// *************************************************************************** *
// *                                                                           *
// *                      Mentor Graphics Corporation                          *
// *                          All rights reserved                              *
// *                                                                           *
// *************************************************************************** *
// *                                                                           *
// * Description:         Partial CANDB File (for BMS Node)                    *
// * Generated at:        2025-09-16 19:54                                     *
// * Node                 BMS                                                  *
// *                                                                           *
// *************************************************************************** *
// *                                                                           *
// *             THIS CONFIGURATION MIGHT CONTAIN SOME ERRORS                  *
// *              IF THE INPUT MODEL WAS NOT PROPERLY FORMED!                  *
// *                    Do Not Use this File directly!                         *
// *                                                                           *
// *************************************************************************** *
VERSION "BMS"

NS_ :

BS_ :

BU_ : BMS

BO_ 305 BMS_PTCANFD_0x131 : 16 BMS
 SG_ BMSChrgrCurCurCp : 63|12@0+ (0.25,0.0) [0.0|1023.75] "A" Vector__XXX
 SG_ HvBattAvgCur : 47|16@0+ (0.1,-3276.7) [-3276.7|3276.8] "A" Vector__XXX
 SG_ HvBattChrgnModSts : 23|3@0+ (1,0) [0|7] "" Vector__XXX
 SG_ HvBattDCPortU : 31|14@0+ (0.1,0.0) [0.0|1638.3000000000002] "" Vector__XXX
 SG_ HvBattHVIL1Sts : 13|2@0+ (1,0) [0|3] "" Vector__XXX
 SG_ HvBattHVIL2Sts : 15|2@0+ (1,0) [0|3] "" Vector__XXX
 SG_ HvBattHVILStsSigGrpChks : 7|8@0+ (1,0) [0|255] "" Vector__XXX
 SG_ HvBattHVILStsSigGrpCntr : 11|4@0+ (1,0) [0|15] "" Vector__XXX
 SG_ HvBattServModSts : 33|2@0+ (1,0) [0|3] "" Vector__XXX

BO_ 449 BMS_PTCANFD_0x1C1 : 32 BMS
 SG_ BMSAuthenticationSts : 57|2@0+ (1,0) [0|3] "" Vector__XXX
 SG_ BMSBCPErrSts : 87|3@0+ (1,0) [0|7] "" Vector__XXX
 SG_ BMSBHMErrSts : 39|2@0+ (1.0,0.0) [0.0|1.0] "" Vector__XXX
 SG_ BMSChrgnAwakeSts : 84|3@0+ (1,0) [0|7] "" Vector__XXX
 SG_ BMSChrgnPauseSts : 81|2@0+ (1,0) [0|3] "" Vector__XXX
 SG_ BMSChrgnRepeatReq : 111|2@0+ (1,0) [0|3] "" Vector__XXX
 SG_ DCChrgnCntctSts : 13|2@0+ (1,0) [0|3] "" Vector__XXX
 SG_ DCChrgnHvBattSoCSigGrpChks : 7|8@0+ (1,0) [0|255] "" Vector__XXX
 SG_ DCChrgnHvBattSoCSigGrpCntr : 11|4@0+ (1,0) [0|15] "" Vector__XXX
 SG_ DCChrgnNegCntctSts : 25|2@0+ (1,0) [0|3] "" Vector__XXX
 SG_ DCChrgnPosCntctSts : 15|2@0+ (1,0) [0|3] "" Vector__XXX
 SG_ DCPileType : 35|3@0+ (1.0,0.0) [0.0|5.0] "" Vector__XXX
 SG_ HvBattAvgCurBackUp : 143|16@0+ (0.1,-3276.7) [-3276.7|3276.8] "A" Vector__XXX
 SG_ HvBattCoolgLvlReq : 63|3@0+ (1,0) [0|7] "" Vector__XXX
 SG_ HvBattFlgChrgnSoCLimFinish : 51|1@0+ (1,0) [0|1] "" Vector__XXX
 SG_ HvBattFlgDchrgnSoCLimFinish : 50|1@0+ (1,0) [0|1] "" Vector__XXX
 SG_ HvBattFlgFullChrgnFinish : 52|1@0+ (1,0) [0|1] "" Vector__XXX
 SG_ HvBattHeatCurLim : 71|14@0+ (0.1,0.0) [0.0|1638.3000000000002] "A" Vector__XXX
 SG_ HvBattHeatgLvlReq : 60|3@0+ (1,0) [0|7] "" Vector__XXX
 SG_ HvBattLowTSocRedn : 109|14@0+ (0.01,0.0) [0.0|100.0] "pct" Vector__XXX
 SG_ HvBattNormTDispSoc : 127|14@0+ (0.01,0.0) [0.0|100.0] "pct" Vector__XXX
 SG_ HvBattSoCAct : 23|11@0+ (0.05,0.0) [0.0|100.0] "%" Vector__XXX
 SG_ HvBattSoCDisp : 47|11@0+ (0.05,0.0) [0.0|100.0] "%" Vector__XXX
 SG_ HvBattSoCDispForHiResl : 95|16@0+ (0.01,0.0) [0.0|100.0] "%" Vector__XXX
 SG_ HvBattSoCDispFV : 215|16@0+ (1.0,0.0) [0.0|65535.0] "" Vector__XXX
 SG_ HvBattSoCDispMAC : 231|32@0+ (1.0,0.0) [0.0|4294967295.0] "" Vector__XXX
 SG_ HVSampChipOverCurrFlg : 49|1@0+ (1.0,0.0) [0.0|1.0] "" Vector__XXX
 SG_ PrechargnPosCntctSts : 37|2@0+ (1,0) [0|3] "" Vector__XXX

BO_ 534 BMS_PTCANFD_0x216 : 8 BMS
 SG_ BMSSyncFVReq : 7|32@0+ (1.0,0.0) [0.0|4294967295.0] "" Vector__XXX

BO_ 626 BMS_PTCANFD_0x272 : 24 BMS
 SG_ BMSFaultInfoFlag : 119|1@0+ (1.0,0.0) [0.0|1.0] "" Vector__XXX
 SG_ FlybackFaultInf : 151|12@0+ (1.0,0.0) [0.0|4095.0] "" Vector__XXX
 SG_ FlybackOutput4Volt : 167|9@0+ (0.1,0.0) [0.0|51.1] "V" Vector__XXX
 SG_ FlybackSupply2OcCtr : 183|8@0+ (1.0,0.0) [0.0|255.0] "" Vector__XXX
 SG_ HvBattActvThermRemd : 31|2@0+ (1,0) [0|3] "" Vector__XXX
 SG_ HvBattDchrgnEgyDisp : 103|11@0+ (0.1,0.0) [0.0|200.0] "kWh" Vector__XXX
 SG_ HvBattDchrgnEgyMax : 87|11@0+ (0.1,0.0) [0.0|200.0] "kWh" Vector__XXX
 SG_ HvBattFlgLowSoc : 118|2@0+ (1,0) [0|3] "" Vector__XXX
 SG_ HvBattFlgPfmn : 27|1@0+ (1,0) [0|1] "" Vector__XXX
 SG_ HvBattFlgSfty : 55|3@0+ (1,0) [0|7] "" Vector__XXX
 SG_ HvBattFlgSftySigGrpChks : 39|8@0+ (1,0) [0|255] "" Vector__XXX
 SG_ HvBattFlgSftySigGrpCntr : 43|4@0+ (1,0) [0|15] "" Vector__XXX
 SG_ HvBattFlgThermRunAway : 45|2@0+ (1,0) [0|3] "" Vector__XXX
 SG_ HvBattHlthMngtFcnSts : 25|2@0+ (1,0) [0|3] "" Vector__XXX
 SG_ HvBattHWFailReq : 76|1@0+ (1,0) [0|1] "" Vector__XXX
 SG_ HvBattLeakFltIndcn : 116|1@0+ (1.0,0.0) [0.0|1.0] "" Vector__XXX
 SG_ HvBattLowSocDrvInhb : 115|1@0+ (1,0) [0|1] "" Vector__XXX
 SG_ HvBattRlyHldSts : 143|2@0+ (1,0) [0|3] "" Vector__XXX
 SG_ HvBattRlyHldStsChks : 127|8@0+ (1.0,0.0) [0.0|255.0] "" Vector__XXX
 SG_ HvBattRlyHldStsCntr : 131|4@0+ (1.0,0.0) [0.0|15.0] "" Vector__XXX
 SG_ HvBattRmngChrgnTi : 7|12@0+ (1.0,0.0) [0.0|4095.0] "min" Vector__XXX
 SG_ HvBattRmngDchrgnTi : 11|12@0+ (1.0,0.0) [0.0|4095.0] "min" Vector__XXX
 SG_ HvBattSoCLock : 71|11@0+ (0.05,0.0) [0.0|100.0] "%" Vector__XXX
 SG_ HvbattSrvReq : 114|2@0+ (1,0) [0|3] "" Vector__XXX
 SG_ HvBattSupChrgnResp : 153|2@0+ (1,0) [0|3] "" Vector__XXX
 SG_ HvBattTempLowFault : 26|1@0+ (1,0) [0|1] "" Vector__XXX

BO_ 627 BMS_PTCANFD_0x273 : 16 BMS
 SG_ HvBattCellUDifFltRSMS : 21|2@0+ (1,0) [0|3] "" Vector__XXX
 SG_ HvBattCellUOverFltRSMS : 31|2@0+ (1,0) [0|3] "" Vector__XXX
 SG_ HvBattCellUUnderFltRSMS : 29|2@0+ (1,0) [0|3] "" Vector__XXX
 SG_ HvBattChrgnEmcyOffReq : 25|1@0+ (1.0,0.0) [0.0|1.0] "" Vector__XXX
 SG_ HvBattChrgnrComFltRSMS : 51|2@0+ (1,0) [0|3] "" Vector__XXX
 SG_ HvBattColdWarn : 35|1@0+ (1,0) [0|1] "" Vector__XXX
 SG_ HvBattFRSReact : 63|8@0+ (1.0,0.0) [0.0|255.0] "" Vector__XXX
 SG_ HvBattFusaPulseCurrMon : 24|1@0+ (1.0,0.0) [0.0|1.0] "" Vector__XXX
 SG_ HvBattMaxUCellIDRSMS : 7|8@0+ (1.0,0.0) [1.0|255.0] "" Vector__XXX
 SG_ HvBattMILReq : 32|1@0+ (1,0) [0|1] "" Vector__XXX
 SG_ HvBattMinUCellIDRSMS : 15|8@0+ (1.0,0.0) [1.0|255.0] "" Vector__XXX
 SG_ HvBattOperationReq : 39|4@0+ (1,0) [0|15] "" Vector__XXX
 SG_ HvBattOverChrgnFltRSMS : 27|2@0+ (1,0) [0|3] "" Vector__XXX
 SG_ HvBattOverCurFltRSMS : 49|2@0+ (1,0) [0|3] "" Vector__XXX
 SG_ HvBattPackUOverFltRSMS : 34|2@0+ (1,0) [0|3] "" Vector__XXX
 SG_ HvBattPackUUnderFltRSMS : 47|2@0+ (1,0) [0|3] "" Vector__XXX
 SG_ HvBattPwrDoMoSceRSMS : 67|2@0+ (1,0) [0|3] "" Vector__XXX
 SG_ HvBattRutPheatgChrgnSts1 : 79|8@0+ (1.0,0.0) [0.0|255.0] "" Vector__XXX
 SG_ HvBattRutPheatgChrgnSts2 : 87|8@0+ (1,0) [0|255] "" Vector__XXX
 SG_ HvBattRutPheatgChrgnSts3 : 95|16@0+ (1.0,0.0) [0.0|65535.0] "" Vector__XXX
 SG_ HvBattRutPheatgChrgnSts4 : 111|16@0+ (1.0,0.0) [0.0|65535.0] "" Vector__XXX
 SG_ HvBattSocHiFltRSMS : 45|2@0+ (1,0) [0|3] "" Vector__XXX
 SG_ HvBattSocHopFltRSMS : 43|2@0+ (1,0) [0|3] "" Vector__XXX
 SG_ HvBattSocLoFltRSMS : 41|2@0+ (1,0) [0|3] "" Vector__XXX
 SG_ HvBattTDifFltRSMS : 55|2@0+ (1,0) [0|3] "" Vector__XXX
 SG_ HvBattTotFltQntyRSMS : 19|4@0+ (1.0,0.0) [0.0|15.0] "" Vector__XXX
 SG_ HvBattTOverFltRSMS : 53|2@0+ (1,0) [0|3] "" Vector__XXX
 SG_ MainNegCntctFlt : 65|2@0+ (1,0) [0|3] "" Vector__XXX
 SG_ MainPosCntctFlt : 23|2@0+ (1,0) [0|3] "" Vector__XXX

BO_ 629 BMS_PTCANFD_0x275 : 16 BMS
 SG_ DCChrgrCurCp : 27|12@0+ (0.25,0.0) [0.0|1023.75] "A" Vector__XXX
 SG_ DCChrgrUCp : 47|11@0+ (1.0,0.0) [0.0|2047.0] "V" Vector__XXX
 SG_ FlybackOutput1Volt : 48|9@0+ (0.1,0.0) [0.0|51.1] "V" Vector__XXX
 SG_ FlybackOutput2Volt : 71|9@0+ (0.1,0.0) [0.0|51.1] "V" Vector__XXX
 SG_ FlybackOutput3Volt : 72|9@0+ (0.1,0.0) [0.0|51.1] "V" Vector__XXX
 SG_ FlybackSupply1OcCtr : 95|8@0+ (1.0,0.0) [0.0|255.0] "" Vector__XXX
 SG_ HvBattCurMaxLimDCChrgn : 7|14@0+ (0.1,0.0) [0.0|1000.0] "A" Vector__XXX
 SG_ HvBattUMaxLimDCChrgn : 23|12@0+ (0.25,0.0) [0.0|1000.0] "V" Vector__XXX

BO_ 630 BMS_PTCANFD_0x276 : 64 BMS
 SG_ BuckOutpUReq : 135|13@0+ (0.1,0.0) [0.0|819.1] "V" Vector__XXX
 SG_ DCChrgnProtocolVers : 90|3@0+ (1,0) [0|7] "" Vector__XXX
 SG_ DCChrgrActCur : 103|12@0+ (0.25,0.0) [0.0|1023.75] "A" Vector__XXX
 SG_ DCChrgrActU : 119|11@0+ (1.0,0.0) [0.0|2047.0] "V" Vector__XXX
 SG_ DCChrgrTypInfo : 107|4@0+ (1,0) [0|15] "" Vector__XXX
 SG_ HvBatt2CCUSleepCmd : 183|8@0+ (1.0,0.0) [0.0|255.0] "" Vector__XXX
 SG_ HvBattBkdHeatgTi : 207|12@0+ (1.0,0.0) [0.0|4095.0] "min" Vector__XXX
 SG_ HvBattBkdPredChrgnTi : 211|12@0+ (1.0,0.0) [0.0|4095.0] "min" Vector__XXX
 SG_ HvBattChrgdEgyThisChrgnCyc : 151|17@0+ (0.001,0.0) [0.0|131.071] "kwh" Vector__XXX
 SG_ HvBattCurMaxLimACChrgn : 55|14@0+ (0.1,0.0) [0.0|1000.0] "A" Vector__XXX
 SG_ HvBattDCChrgnfltTyp : 255|3@0+ (1,0) [0|7] "" Vector__XXX
 SG_ HvBattDCChrgnSts : 123|4@0+ (1,0) [0|15] "" Vector__XXX
 SG_ HvBattDCChrgnTyp : 252|3@0+ (1,0) [0|7] "" Vector__XXX
 SG_ HvBattKeepWrmgTi : 231|12@0+ (1.0,0.0) [0.0|4095.0] "min" Vector__XXX
 SG_ HvBattOCCurMaxAuxFastRec : 191|16@0+ (1.0,-32767.0) [-32767.0|32768.0] "A" Vector__XXX
 SG_ HvBattOCCurMaxAuxRec : 327|16@0+ (1.0,-32767.0) [-32767.0|32768.0] "A" Vector__XXX
 SG_ HvBattOCCurMaxMainFastRec : 343|16@0+ (1.0,-32767.0) [-32767.0|32768.0] "A" Vector__XXX
 SG_ HvBattOCCurMaxMainRec : 359|16@0+ (1.0,-32767.0) [-32767.0|32768.0] "A" Vector__XXX
 SG_ HvBattPreHeatgTi : 235|12@0+ (1.0,0.0) [0.0|4095.0] "min" Vector__XXX
 SG_ HvBattSyncUCellMax : 311|16@0+ (0.0001,0.0) [0.0|6.5535000000000005] "V" Vector__XXX
 SG_ HvBattSyncUCellMin : 295|16@0+ (0.0001,0.0) [0.0|6.5535000000000005] "V" Vector__XXX
 SG_ HvBattUCellAvg : 87|13@0+ (0.001,0.0) [0.0|8.19] "V" Vector__XXX
 SG_ HvBattUCellMax : 23|13@0+ (0.001,0.0) [0.0|8.191] "V" Vector__XXX
 SG_ HvBattUCellMin : 39|13@0+ (0.001,0.0) [0.0|8.191] "V" Vector__XXX
 SG_ HvBattUCellSigGrpChks : 7|8@0+ (1,0) [0|255] "" Vector__XXX
 SG_ HvBattUCellSigGrpCntr : 11|4@0+ (1,0) [0|15] "" Vector__XXX
 SG_ HvBattUCellSyncCur : 279|16@0+ (0.1,-3276.8) [-3276.8|3276.7] "A" Vector__XXX
 SG_ HvBattUCellSyncSigGrpChks : 263|8@0+ (1,0) [0|255] "" Vector__XXX
 SG_ HvBattUCellSyncSigGrpCntr : 267|4@0+ (1,0) [0|15] "" Vector__XXX
 SG_ HvBattUMaxLimACChrgn : 71|12@0+ (0.25,0.0) [0.0|1000.0] "V" Vector__XXX

BO_ 632 BMS_PTCANFD_0x278 : 32 BMS
 SG_ HvBattCorsCur : 7|16@0+ (0.1,-3276.7) [-3276.7|3276.8] "A" Vector__XXX
 SG_ HvBattFltNr1 : 191|10@0+ (1.0,0.0) [0.0|1023.0] "" Vector__XXX
 SG_ HvBattFltNr2 : 215|10@0+ (1.0,0.0) [0.0|1023.0] "" Vector__XXX
 SG_ HvBattFltNr3 : 217|10@0+ (1.0,0.0) [0.0|1023.0] "" Vector__XXX
 SG_ HvBattFltNr4 : 239|10@0+ (1.0,0.0) [0.0|1023.0] "" Vector__XXX
 SG_ HvBattFltNr5 : 241|10@0+ (1.0,0.0) [0.0|1023.0] "" Vector__XXX
 SG_ HvBattFltNrIdx : 193|10@0+ (1.0,0.0) [0.0|1023.0] "" Vector__XXX
 SG_ HvBattFltTotNr : 137|10@0+ (1.0,0.0) [0.0|1023.0] "" Vector__XXX
 SG_ HvBatThrRson : 159|32@0+ (1.0,0.0) [0.0|4294967295.0] "" Vector__XXX
 SG_ HvBattSopMdlLongTiChrgCurr : 39|11@0+ (1.0,0.0) [0.0|2047.0] "A" Vector__XXX
 SG_ HvBattSopMdlLongTiDchaCurr : 55|11@0+ (1.0,0.0) [0.0|2047.0] "A" Vector__XXX
 SG_ HvBattSopMdlShoTiChrgCurr : 71|11@0+ (1.0,0.0) [0.0|2047.0] "A" Vector__XXX
 SG_ HvBattSopMdlShoTiDchaCurr : 87|11@0+ (1.0,0.0) [0.0|2047.0] "A" Vector__XXX
 SG_ HvBattUkl30C : 135|9@0+ (0.1,0.0) [0.0|51.1] "V" Vector__XXX
 SG_ HvBattV2VSts : 142|3@0+ (1,0) [0|7] "" Vector__XXX

BO_ 633 BMS_PTCANFD_0x279 : 32 BMS
 SG_ HvBattCellURSMS1 : 7|13@0+ (0.001,0.0) [0.0|8.19] "V" Vector__XXX
 SG_ HvBattCellURSMS10 : 151|13@0+ (0.001,0.0) [0.0|8.19] "V" Vector__XXX
 SG_ HvBattCellURSMS11 : 167|13@0+ (0.001,0.0) [0.0|8.19] "V" Vector__XXX
 SG_ HvBattCellURSMS12 : 183|13@0+ (0.001,0.0) [0.0|8.19] "V" Vector__XXX
 SG_ HvBattCellURSMS13 : 199|13@0+ (0.001,0.0) [0.0|8.19] "V" Vector__XXX
 SG_ HvBattCellURSMS14 : 215|13@0+ (0.001,0.0) [0.0|8.19] "V" Vector__XXX
 SG_ HvBattCellURSMS15 : 231|13@0+ (0.001,0.0) [0.0|8.19] "V" Vector__XXX
 SG_ HvBattCellURSMS16 : 247|13@0+ (0.001,0.0) [0.0|8.191] "V" Vector__XXX
 SG_ HvBattCellURSMS2 : 23|13@0+ (0.001,0.0) [0.0|8.19] "V" Vector__XXX
 SG_ HvBattCellURSMS3 : 39|13@0+ (0.001,0.0) [0.0|8.19] "V" Vector__XXX
 SG_ HvBattCellURSMS4 : 55|13@0+ (0.001,0.0) [0.0|8.19] "V" Vector__XXX
 SG_ HvBattCellURSMS5 : 71|13@0+ (0.001,0.0) [0.0|8.19] "V" Vector__XXX
 SG_ HvBattCellURSMS6 : 87|13@0+ (0.001,0.0) [0.0|8.19] "V" Vector__XXX
 SG_ HvBattCellURSMS7 : 103|13@0+ (0.001,0.0) [0.0|8.19] "V" Vector__XXX
 SG_ HvBattCellURSMS8 : 119|13@0+ (0.001,0.0) [0.0|8.19] "V" Vector__XXX
 SG_ HvBattCellURSMS9 : 135|13@0+ (0.001,0.0) [0.0|8.19] "V" Vector__XXX

BO_ 634 BMS_PTCANFD_0x27A : 32 BMS
 SG_ HvBattCellURSMS17 : 7|13@0+ (0.001,0.0) [0.0|8.191] "V" Vector__XXX
 SG_ HvBattCellURSMS18 : 23|13@0+ (0.001,0.0) [0.0|8.191] "V" Vector__XXX
 SG_ HvBattCellURSMS19 : 39|13@0+ (0.001,0.0) [0.0|8.191] "V" Vector__XXX
 SG_ HvBattCellURSMS20 : 55|13@0+ (0.001,0.0) [0.0|8.191] "V" Vector__XXX
 SG_ HvBattCellURSMS21 : 71|13@0+ (0.001,0.0) [0.0|8.191] "V" Vector__XXX
 SG_ HvBattCellURSMS22 : 87|13@0+ (0.001,0.0) [0.0|8.191] "V" Vector__XXX
 SG_ HvBattCellURSMS23 : 103|13@0+ (0.001,0.0) [0.0|8.191] "V" Vector__XXX
 SG_ HvBattCellURSMS24 : 119|13@0+ (0.001,0.0) [0.0|8.191] "V" Vector__XXX
 SG_ HvBattCellURSMS25 : 135|13@0+ (0.001,0.0) [0.0|8.191] "V" Vector__XXX
 SG_ HvBattCellURSMS26 : 151|13@0+ (0.001,0.0) [0.0|8.191] "V" Vector__XXX
 SG_ HvBattCellURSMS27 : 167|13@0+ (0.001,0.0) [0.0|8.191] "V" Vector__XXX
 SG_ HvBattCellURSMS28 : 183|13@0+ (0.001,0.0) [0.0|8.191] "V" Vector__XXX
 SG_ HvBattCellURSMS29 : 199|13@0+ (0.001,0.0) [0.0|8.191] "V" Vector__XXX
 SG_ HvBattCellURSMS30 : 215|13@0+ (0.001,0.0) [0.0|8.191] "V" Vector__XXX
 SG_ HvBattCellURSMS31 : 231|13@0+ (0.001,0.0) [0.0|8.191] "V" Vector__XXX
 SG_ HvBattCellURSMS32 : 247|13@0+ (0.001,0.0) [0.0|8.191] "V" Vector__XXX

BO_ 635 BMS_PTCANFD_0x27B : 32 BMS
 SG_ HvBattCellURSMS33 : 7|13@0+ (0.001,0.0) [0.0|8.191] "V" Vector__XXX
 SG_ HvBattCellURSMS34 : 23|13@0+ (0.001,0.0) [0.0|8.191] "V" Vector__XXX
 SG_ HvBattCellURSMS35 : 39|13@0+ (0.001,0.0) [0.0|8.191] "V" Vector__XXX
 SG_ HvBattCellURSMS36 : 55|13@0+ (0.001,0.0) [0.0|8.191] "V" Vector__XXX
 SG_ HvBattCellURSMS37 : 71|13@0+ (0.001,0.0) [0.0|8.191] "V" Vector__XXX
 SG_ HvBattCellURSMS38 : 87|13@0+ (0.001,0.0) [0.0|8.191] "V" Vector__XXX
 SG_ HvBattCellURSMS39 : 103|13@0+ (0.001,0.0) [0.0|8.191] "V" Vector__XXX
 SG_ HvBattCellURSMS40 : 119|13@0+ (0.001,0.0) [0.0|8.191] "V" Vector__XXX
 SG_ HvBattCellURSMS41 : 135|13@0+ (0.001,0.0) [0.0|8.191] "V" Vector__XXX
 SG_ HvBattCellURSMS42 : 151|13@0+ (0.001,0.0) [0.0|8.191] "V" Vector__XXX
 SG_ HvBattCellURSMS43 : 167|13@0+ (0.001,0.0) [0.0|8.191] "V" Vector__XXX
 SG_ HvBattCellURSMS44 : 183|13@0+ (0.001,0.0) [0.0|8.191] "V" Vector__XXX
 SG_ HvBattCellURSMS45 : 199|13@0+ (0.001,0.0) [0.0|8.191] "V" Vector__XXX
 SG_ HvBattCellURSMS46 : 215|13@0+ (0.001,0.0) [0.0|8.191] "V" Vector__XXX
 SG_ HvBattCellURSMS47 : 231|13@0+ (0.001,0.0) [0.0|8.191] "V" Vector__XXX
 SG_ HvBattCellURSMS48 : 247|13@0+ (0.001,0.0) [0.0|8.191] "V" Vector__XXX

BO_ 636 BMS_PTCANFD_0x27C : 32 BMS
 SG_ HvBattCellURSMS49 : 7|13@0+ (0.001,0.0) [0.0|8.191] "V" Vector__XXX
 SG_ HvBattCellURSMS50 : 23|13@0+ (0.001,0.0) [0.0|8.191] "V" Vector__XXX
 SG_ HvBattCellURSMS51 : 39|13@0+ (0.001,0.0) [0.0|8.191] "V" Vector__XXX
 SG_ HvBattCellURSMS52 : 55|13@0+ (0.001,0.0) [0.0|8.191] "V" Vector__XXX
 SG_ HvBattCellURSMS53 : 71|13@0+ (0.001,0.0) [0.0|8.191] "V" Vector__XXX
 SG_ HvBattCellURSMS54 : 87|13@0+ (0.001,0.0) [0.0|8.191] "V" Vector__XXX
 SG_ HvBattCellURSMS55 : 103|13@0+ (0.001,0.0) [0.0|8.191] "V" Vector__XXX
 SG_ HvBattCellURSMS56 : 119|13@0+ (0.001,0.0) [0.0|8.191] "V" Vector__XXX
 SG_ HvBattCellURSMS57 : 135|13@0+ (0.001,0.0) [0.0|8.191] "V" Vector__XXX
 SG_ HvBattCellURSMS58 : 151|13@0+ (0.001,0.0) [0.0|8.191] "V" Vector__XXX
 SG_ HvBattCellURSMS59 : 167|13@0+ (0.001,0.0) [0.0|8.191] "V" Vector__XXX
 SG_ HvBattCellURSMS60 : 183|13@0+ (0.001,0.0) [0.0|8.191] "V" Vector__XXX
 SG_ HvBattCellURSMS61 : 199|13@0+ (0.001,0.0) [0.0|8.191] "V" Vector__XXX
 SG_ HvBattCellURSMS62 : 215|13@0+ (0.001,0.0) [0.0|8.191] "V" Vector__XXX
 SG_ HvBattCellURSMS63 : 231|13@0+ (0.001,0.0) [0.0|8.191] "V" Vector__XXX
 SG_ HvBattCellURSMS64 : 247|13@0+ (0.001,0.0) [0.0|8.191] "V" Vector__XXX

BO_ 637 BMS_PTCANFD_0x27D : 32 BMS
 SG_ HvBattCellURSMS65 : 7|13@0+ (0.001,0.0) [0.0|8.191] "V" Vector__XXX
 SG_ HvBattCellURSMS66 : 23|13@0+ (0.001,0.0) [0.0|8.191] "V" Vector__XXX
 SG_ HvBattCellURSMS67 : 39|13@0+ (0.001,0.0) [0.0|8.191] "V" Vector__XXX
 SG_ HvBattCellURSMS68 : 55|13@0+ (0.001,0.0) [0.0|8.191] "V" Vector__XXX
 SG_ HvBattCellURSMS69 : 71|13@0+ (0.001,0.0) [0.0|8.191] "V" Vector__XXX
 SG_ HvBattCellURSMS70 : 87|13@0+ (0.001,0.0) [0.0|8.191] "V" Vector__XXX
 SG_ HvBattCellURSMS71 : 103|13@0+ (0.001,0.0) [0.0|8.191] "V" Vector__XXX
 SG_ HvBattCellURSMS72 : 119|13@0+ (0.001,0.0) [0.0|8.191] "V" Vector__XXX
 SG_ HvBattCellURSMS73 : 135|13@0+ (0.001,0.0) [0.0|8.191] "V" Vector__XXX
 SG_ HvBattCellURSMS74 : 151|13@0+ (0.001,0.0) [0.0|8.191] "V" Vector__XXX
 SG_ HvBattCellURSMS75 : 167|13@0+ (0.001,0.0) [0.0|8.191] "V" Vector__XXX
 SG_ HvBattCellURSMS76 : 183|13@0+ (0.001,0.0) [0.0|8.191] "V" Vector__XXX
 SG_ HvBattCellURSMS77 : 199|13@0+ (0.001,0.0) [0.0|8.191] "V" Vector__XXX
 SG_ HvBattCellURSMS78 : 215|13@0+ (0.001,0.0) [0.0|8.191] "V" Vector__XXX
 SG_ HvBattCellURSMS79 : 231|13@0+ (0.001,0.0) [0.0|8.191] "V" Vector__XXX
 SG_ HvBattCellURSMS80 : 247|13@0+ (0.001,0.0) [0.0|8.191] "V" Vector__XXX

BO_ 638 BMS_PTCANFD_0x27E : 32 BMS
 SG_ HvBattCellURSMS81 : 7|13@0+ (0.001,0.0) [0.0|8.191] "V" Vector__XXX
 SG_ HvBattCellURSMS82 : 23|13@0+ (0.001,0.0) [0.0|8.191] "V" Vector__XXX
 SG_ HvBattCellURSMS83 : 39|13@0+ (0.001,0.0) [0.0|8.191] "V" Vector__XXX
 SG_ HvBattCellURSMS84 : 55|13@0+ (0.001,0.0) [0.0|8.191] "V" Vector__XXX
 SG_ HvBattCellURSMS85 : 71|13@0+ (0.001,0.0) [0.0|8.191] "V" Vector__XXX
 SG_ HvBattCellURSMS86 : 87|13@0+ (0.001,0.0) [0.0|8.191] "V" Vector__XXX
 SG_ HvBattCellURSMS87 : 103|13@0+ (0.001,0.0) [0.0|8.191] "V" Vector__XXX
 SG_ HvBattCellURSMS88 : 119|13@0+ (0.001,0.0) [0.0|8.191] "V" Vector__XXX
 SG_ HvBattCellURSMS89 : 135|13@0+ (0.001,0.0) [0.0|8.191] "V" Vector__XXX
 SG_ HvBattCellURSMS90 : 151|13@0+ (0.001,0.0) [0.0|8.191] "V" Vector__XXX
 SG_ HvBattCellURSMS91 : 167|13@0+ (0.001,0.0) [0.0|8.191] "V" Vector__XXX
 SG_ HvBattCellURSMS92 : 183|13@0+ (0.001,0.0) [0.0|8.191] "V" Vector__XXX
 SG_ HvBattCellURSMS93 : 199|13@0+ (0.001,0.0) [0.0|8.191] "V" Vector__XXX
 SG_ HvBattCellURSMS94 : 215|13@0+ (0.001,0.0) [0.0|8.191] "V" Vector__XXX
 SG_ HvBattCellURSMS95 : 231|13@0+ (0.001,0.0) [0.0|8.191] "V" Vector__XXX
 SG_ HvBattCellURSMS96 : 247|13@0+ (0.001,0.0) [0.0|8.191] "V" Vector__XXX

BO_ 639 BMS_PTCANFD_0x27F : 32 BMS
 SG_ HvBattCellURSMS100 : 55|13@0+ (0.001,0.0) [0.0|8.191] "V" Vector__XXX
 SG_ HvBattCellURSMS101 : 71|13@0+ (0.001,0.0) [0.0|8.191] "V" Vector__XXX
 SG_ HvBattCellURSMS102 : 87|13@0+ (0.001,0.0) [0.0|8.191] "V" Vector__XXX
 SG_ HvBattCellURSMS103 : 103|13@0+ (0.001,0.0) [0.0|8.191] "V" Vector__XXX
 SG_ HvBattCellURSMS104 : 119|13@0+ (0.001,0.0) [0.0|8.191] "V" Vector__XXX
 SG_ HvBattCellURSMS105 : 135|13@0+ (0.001,0.0) [0.0|8.191] "V" Vector__XXX
 SG_ HvBattCellURSMS106 : 151|13@0+ (0.001,0.0) [0.0|8.191] "V" Vector__XXX
 SG_ HvBattCellURSMS107 : 167|13@0+ (0.001,0.0) [0.0|8.191] "V" Vector__XXX
 SG_ HvBattCellURSMS108 : 183|13@0+ (0.001,0.0) [0.0|8.191] "V" Vector__XXX
 SG_ HvBattCellURSMS109 : 199|13@0+ (0.001,0.0) [0.0|8.191] "V" Vector__XXX
 SG_ HvBattCellURSMS110 : 215|13@0+ (0.001,0.0) [0.0|8.191] "V" Vector__XXX
 SG_ HvBattCellURSMS111 : 231|13@0+ (0.001,0.0) [0.0|8.191] "V" Vector__XXX
 SG_ HvBattCellURSMS112 : 247|13@0+ (0.001,0.0) [0.0|8.191] "V" Vector__XXX
 SG_ HvBattCellURSMS97 : 7|13@0+ (0.001,0.0) [0.0|8.191] "V" Vector__XXX
 SG_ HvBattCellURSMS98 : 23|13@0+ (0.001,0.0) [0.0|8.191] "V" Vector__XXX
 SG_ HvBattCellURSMS99 : 39|13@0+ (0.001,0.0) [0.0|8.191] "V" Vector__XXX

BO_ 642 BMS_PTCANFD_0x282 : 8 BMS
 SG_ BMUFuSaFltRct : 23|1@0+ (1,0) [0|1] "" Vector__XXX
 SG_ CellOverVoltFatalFaultNum : 7|8@0+ (1.0,0.0) [0.0|255.0] "" Vector__XXX
 SG_ CellUnderVoltFatalFaultNum : 15|8@0+ (1.0,0.0) [0.0|255.0] "" Vector__XXX
 SG_ GaCMSAfeDieTempOTTestFail : 22|1@0+ (1,0) [0|1] "" Vector__XXX
 SG_ GaCTMModlTempSampElecFault : 21|1@0+ (1,0) [0|1] "" Vector__XXX
 SG_ GaCTMModlTempSamplingOoRSts : 20|1@0+ (1,0) [0|1] "" Vector__XXX
 SG_ GeACCChargeOvercurrentL1Fault : 19|1@0+ (1,0) [0|1] "" Vector__XXX
 SG_ GeACCChargeOvercurrentL2Fault : 18|1@0+ (1,0) [0|1] "" Vector__XXX
 SG_ GeACCChargeOverCurrentL3Fault : 17|1@0+ (1,0) [0|1] "" Vector__XXX
 SG_ GeACCChargeOverCurrentL4Fault : 16|1@0+ (1,0) [0|1] "" Vector__XXX
 SG_ GeACCChargeOverCurrentL5Fault : 31|1@0+ (1,0) [0|1] "" Vector__XXX
 SG_ GeBCSOverCurrentDeviationFault : 30|1@0+ (1,0) [0|1] "" Vector__XXX
 SG_ GeBCVVdncSmpCircAbnFault : 29|1@0+ (1,0) [0|1] "" Vector__XXX
 SG_ GeBCVVdpcSmpCircAbnFault : 28|1@0+ (1,0) [0|1] "" Vector__XXX
 SG_ GeBCVVmncSmpCircAbnFault : 27|1@0+ (1,0) [0|1] "" Vector__XXX
 SG_ GeBCVVmpcSmpCircAbnFault : 26|1@0+ (1,0) [0|1] "" Vector__XXX
 SG_ GeDCCChargeOvercurrentL1Fault : 25|1@0+ (1,0) [0|1] "" Vector__XXX
 SG_ GeDCCChargeOvercurrentL2Fault : 24|1@0+ (1,0) [0|1] "" Vector__XXX
 SG_ GeDCCChargeOverCurrentL3Fault : 39|1@0+ (1,0) [0|1] "" Vector__XXX
 SG_ GeDCCChargeOverCurrentL4Fault : 38|1@0+ (1,0) [0|1] "" Vector__XXX
 SG_ GeDCCChargeOverCurrentL5Fault : 47|1@0+ (1,0) [0|1] "" Vector__XXX
 SG_ ModlOverTempFatalFaultNum : 37|6@0+ (1.0,0.0) [0.0|63.0] "" Vector__XXX

BO_ 645 BMS_PTCANFD_0x285 : 48 BMS
 SG_ HvBattAFECommSt : 191|16@0+ (1,0) [0|65535] "" Vector__XXX
 SG_ HvBattUCellEigValue1 : 156|13@0+ (0.001,0.0) [0.0|8.191] "V" Vector__XXX
 SG_ HvBattUCellEigValue2 : 175|13@0+ (0.001,0.0) [0.0|8.191] "V" Vector__XXX

BO_ 646 BMS_PTCANFD_0x286 : 24 BMS
 SG_ BMSBCLCurReq : 87|14@0+ (0.1,0.0) [0.0|1638.3000000000002] "A" Vector__XXX
 SG_ BMSBCLVolReq : 117|14@0+ (0.1,0.0) [0.0|1638.3000000000002] "V" Vector__XXX
 SG_ BMSBCPFxCurU : 151|11@0+ (1.0,0.0) [0.0|2047.0] "V" Vector__XXX
 SG_ BMSBCPFxMaxU : 154|11@0+ (1.0,0.0) [0.0|2047.0] "V" Vector__XXX
 SG_ BMSBHMFxU : 175|11@0+ (1.0,0.0) [0.0|2047.0] "V" Vector__XXX
 SG_ BMSCHMRxSts : 89|2@0+ (1.0,0.0) [0.0|1.0] "" Vector__XXX
 SG_ BMSCMLRxSts : 103|2@0+ (1.0,0.0) [0.0|1.0] "" Vector__XXX
 SG_ BMSCRMARxSts : 101|2@0+ (1.0,0.0) [0.0|1.0] "" Vector__XXX
 SG_ BMSCRMORxSts : 99|2@0+ (1,0) [0|3] "" Vector__XXX
 SG_ BMSCROARxSts : 97|2@0+ (1.0,0.0) [0.0|1.0] "" Vector__XXX
 SG_ BMSCROORxSts : 107|2@0+ (1.0,0.0) [0.0|1.0] "" Vector__XXX
 SG_ DCChrgnNegCntctFlt : 111|2@0+ (1,0) [0|3] "" Vector__XXX
 SG_ DCChrgnPosCntctFlt : 109|2@0+ (1,0) [0|3] "" Vector__XXX
 SG_ DCChrgrCc1ConnectnSts : 180|3@0+ (1,0) [0|7] "" Vector__XXX
 SG_ DchaByChrgrBattallwFlg : 131|2@0+ (1,0) [0|3] "" Vector__XXX
 SG_ HvBattChrgnDeratForT : 105|2@0+ (1,0) [0|3] "" Vector__XXX
 SG_ HvBattCmptFaultIndcn : 135|4@0+ (1,0) [0|15] "" Vector__XXX
 SG_ HvBattInsulChkProgrs : 143|8@0+ (1.0,0.0) [0.0|255.0] "" Vector__XXX
 SG_ HvBattInsulChkSigGrpChks : 7|8@0+ (1,0) [0|255] "" Vector__XXX
 SG_ HvBattInsulChkSigGrpCntr : 11|4@0+ (1,0) [0|15] "" Vector__XXX
 SG_ HvBattInsulChkSts : 14|3@0+ (1,0) [0|7] "" Vector__XXX
 SG_ HvBattInsulRN : 39|16@0+ (1.0,0.0) [0.0|65535.0] "kOhm" Vector__XXX
 SG_ HvBattInsulRP : 23|16@0+ (1.0,0.0) [0.0|65535.0] "kOhm" Vector__XXX
 SG_ HvBusInsulRN : 71|16@0+ (1.0,0.0) [0.0|65535.0] "kOhm" Vector__XXX
 SG_ HvBusInsulRP : 55|16@0+ (1.0,0.0) [0.0|65535.0] "kOhm" Vector__XXX
 SG_ PrechargnPosCntctFlt : 119|2@0+ (1,0) [0|3] "" Vector__XXX

BO_ 647 BMS_PTCANFD_0x287 : 32 BMS
 SG_ HvBattCellURSMS113 : 7|13@0+ (0.001,0.0) [0.0|8.191] "V" Vector__XXX
 SG_ HvBattCellURSMS114 : 23|13@0+ (0.001,0.0) [0.0|8.191] "V" Vector__XXX
 SG_ HvBattCellURSMS115 : 39|13@0+ (0.001,0.0) [0.0|8.191] "V" Vector__XXX
 SG_ HvBattCellURSMS116 : 55|13@0+ (0.001,0.0) [0.0|8.191] "V" Vector__XXX
 SG_ HvBattCellURSMS117 : 71|13@0+ (0.001,0.0) [0.0|8.191] "V" Vector__XXX
 SG_ HvBattCellURSMS118 : 87|13@0+ (0.001,0.0) [0.0|8.191] "V" Vector__XXX
 SG_ HvBattCellURSMS119 : 103|13@0+ (0.001,0.0) [0.0|8.191] "V" Vector__XXX
 SG_ HvBattCellURSMS120 : 119|13@0+ (0.001,0.0) [0.0|8.191] "V" Vector__XXX
 SG_ HvBattCellURSMS121 : 135|13@0+ (0.001,0.0) [0.0|8.191] "V" Vector__XXX
 SG_ HvBattCellURSMS122 : 151|13@0+ (0.001,0.0) [0.0|8.191] "V" Vector__XXX
 SG_ HvBattCellURSMS123 : 167|13@0+ (0.001,0.0) [0.0|8.191] "V" Vector__XXX
 SG_ HvBattCellURSMS124 : 183|13@0+ (0.001,0.0) [0.0|8.191] "V" Vector__XXX
 SG_ HvBattCellURSMS125 : 199|13@0+ (0.001,0.0) [0.0|8.191] "V" Vector__XXX
 SG_ HvBattCellURSMS126 : 215|13@0+ (0.001,0.0) [0.0|8.191] "V" Vector__XXX
 SG_ HvBattCellURSMS127 : 231|13@0+ (0.001,0.0) [0.0|8.191] "V" Vector__XXX
 SG_ HvBattCellURSMS128 : 247|13@0+ (0.001,0.0) [0.0|8.191] "V" Vector__XXX

BO_ 648 BMS_PTCANFD_0x288 : 32 BMS
 SG_ HvBattCellURSMS129 : 7|13@0+ (0.001,0.0) [0.0|8.191] "V" Vector__XXX
 SG_ HvBattCellURSMS130 : 23|13@0+ (0.001,0.0) [0.0|8.191] "V" Vector__XXX
 SG_ HvBattCellURSMS131 : 39|13@0+ (0.001,0.0) [0.0|8.191] "V" Vector__XXX
 SG_ HvBattCellURSMS132 : 55|13@0+ (0.001,0.0) [0.0|8.191] "V" Vector__XXX
 SG_ HvBattCellURSMS133 : 71|13@0+ (0.001,0.0) [0.0|8.191] "V" Vector__XXX
 SG_ HvBattCellURSMS134 : 87|13@0+ (0.001,0.0) [0.0|8.191] "V" Vector__XXX
 SG_ HvBattCellURSMS135 : 103|13@0+ (0.001,0.0) [0.0|8.191] "V" Vector__XXX
 SG_ HvBattCellURSMS136 : 119|13@0+ (0.001,0.0) [0.0|8.191] "V" Vector__XXX
 SG_ HvBattCellURSMS137 : 135|13@0+ (0.001,0.0) [0.0|8.191] "V" Vector__XXX
 SG_ HvBattCellURSMS138 : 151|13@0+ (0.001,0.0) [0.0|8.191] "V" Vector__XXX
 SG_ HvBattCellURSMS139 : 167|13@0+ (0.001,0.0) [0.0|8.191] "V" Vector__XXX
 SG_ HvBattCellURSMS140 : 183|13@0+ (0.001,0.0) [0.0|8.191] "V" Vector__XXX
 SG_ HvBattCellURSMS141 : 199|13@0+ (0.001,0.0) [0.0|8.191] "V" Vector__XXX
 SG_ HvBattCellURSMS142 : 215|13@0+ (0.001,0.0) [0.0|8.191] "V" Vector__XXX
 SG_ HvBattCellURSMS143 : 231|13@0+ (0.001,0.0) [0.0|8.191] "V" Vector__XXX
 SG_ HvBattCellURSMS144 : 247|13@0+ (0.001,0.0) [0.0|8.191] "V" Vector__XXX

BO_ 649 BMS_PTCANFD_0x289 : 32 BMS
 SG_ HvBattCellURSMS145 : 7|13@0+ (0.001,0.0) [0.0|8.191] "V" Vector__XXX
 SG_ HvBattCellURSMS146 : 23|13@0+ (0.001,0.0) [0.0|8.191] "V" Vector__XXX
 SG_ HvBattCellURSMS147 : 39|13@0+ (0.001,0.0) [0.0|8.191] "V" Vector__XXX
 SG_ HvBattCellURSMS148 : 55|13@0+ (0.001,0.0) [0.0|8.191] "V" Vector__XXX
 SG_ HvBattCellURSMS149 : 71|13@0+ (0.001,0.0) [0.0|8.191] "V" Vector__XXX
 SG_ HvBattCellURSMS150 : 87|13@0+ (0.001,0.0) [0.0|8.191] "V" Vector__XXX
 SG_ HvBattCellURSMS151 : 103|13@0+ (0.001,0.0) [0.0|8.191] "V" Vector__XXX
 SG_ HvBattCellURSMS152 : 119|13@0+ (0.001,0.0) [0.0|8.191] "V" Vector__XXX
 SG_ HvBattCellURSMS153 : 135|13@0+ (0.001,0.0) [0.0|8.191] "V" Vector__XXX
 SG_ HvBattCellURSMS154 : 151|13@0+ (0.001,0.0) [0.0|8.191] "V" Vector__XXX
 SG_ HvBattCellURSMS155 : 167|13@0+ (0.001,0.0) [0.0|8.191] "V" Vector__XXX
 SG_ HvBattCellURSMS156 : 183|13@0+ (0.001,0.0) [0.0|8.191] "V" Vector__XXX
 SG_ HvBattCellURSMS157 : 199|13@0+ (0.001,0.0) [0.0|8.191] "V" Vector__XXX
 SG_ HvBattCellURSMS158 : 215|13@0+ (0.001,0.0) [0.0|8.191] "V" Vector__XXX
 SG_ HvBattCellURSMS159 : 231|13@0+ (0.001,0.0) [0.0|8.191] "V" Vector__XXX
 SG_ HvBattCellURSMS160 : 247|13@0+ (0.001,0.0) [0.0|8.191] "V" Vector__XXX

BO_ 650 BMS_PTCANFD_0x28A : 32 BMS
 SG_ HvBattCellURSMS161 : 7|13@0+ (0.001,0.0) [0.0|8.191] "V" Vector__XXX
 SG_ HvBattCellURSMS162 : 23|13@0+ (0.001,0.0) [0.0|8.191] "V" Vector__XXX
 SG_ HvBattCellURSMS163 : 39|13@0+ (0.001,0.0) [0.0|8.191] "V" Vector__XXX
 SG_ HvBattCellURSMS164 : 55|13@0+ (0.001,0.0) [0.0|8.191] "V" Vector__XXX
 SG_ HvBattCellURSMS165 : 71|13@0+ (0.001,0.0) [0.0|8.191] "V" Vector__XXX
 SG_ HvBattCellURSMS166 : 87|13@0+ (0.001,0.0) [0.0|8.191] "V" Vector__XXX
 SG_ HvBattCellURSMS167 : 103|13@0+ (0.001,0.0) [0.0|8.191] "V" Vector__XXX
 SG_ HvBattCellURSMS168 : 119|13@0+ (0.001,0.0) [0.0|8.191] "V" Vector__XXX
 SG_ HvBattCellURSMS169 : 135|13@0+ (0.001,0.0) [0.0|8.191] "V" Vector__XXX
 SG_ HvBattCellURSMS170 : 151|13@0+ (0.001,0.0) [0.0|8.191] "V" Vector__XXX
 SG_ HvBattCellURSMS171 : 167|13@0+ (0.001,0.0) [0.0|8.191] "V" Vector__XXX
 SG_ HvBattCellURSMS172 : 183|13@0+ (0.001,0.0) [0.0|8.191] "V" Vector__XXX
 SG_ HvBattCellURSMS173 : 199|13@0+ (0.001,0.0) [0.0|8.191] "V" Vector__XXX
 SG_ HvBattCellURSMS174 : 215|13@0+ (0.001,0.0) [0.0|8.191] "V" Vector__XXX
 SG_ HvBattCellURSMS175 : 231|13@0+ (0.001,0.0) [0.0|8.191] "V" Vector__XXX
 SG_ HvBattCellURSMS176 : 247|13@0+ (0.001,0.0) [0.0|8.191] "V" Vector__XXX

BO_ 651 BMS_PTCANFD_0x28B : 32 BMS
 SG_ HvBattCellURSMS177 : 7|13@0+ (0.001,0.0) [0.0|8.191] "V" Vector__XXX
 SG_ HvBattCellURSMS178 : 23|13@0+ (0.001,0.0) [0.0|8.191] "V" Vector__XXX
 SG_ HvBattCellURSMS179 : 39|13@0+ (0.001,0.0) [0.0|8.191] "V" Vector__XXX
 SG_ HvBattCellURSMS180 : 55|13@0+ (0.001,0.0) [0.0|8.191] "V" Vector__XXX
 SG_ HvBattCellURSMS181 : 71|13@0+ (0.001,0.0) [0.0|8.191] "V" Vector__XXX
 SG_ HvBattCellURSMS182 : 87|13@0+ (0.001,0.0) [0.0|8.191] "V" Vector__XXX
 SG_ HvBattCellURSMS183 : 103|13@0+ (0.001,0.0) [0.0|8.191] "V" Vector__XXX
 SG_ HvBattCellURSMS184 : 119|13@0+ (0.001,0.0) [0.0|8.191] "V" Vector__XXX
 SG_ HvBattCellURSMS185 : 135|13@0+ (0.001,0.0) [0.0|8.191] "V" Vector__XXX
 SG_ HvBattCellURSMS186 : 151|13@0+ (0.001,0.0) [0.0|8.191] "V" Vector__XXX
 SG_ HvBattCellURSMS187 : 167|13@0+ (0.001,0.0) [0.0|8.191] "V" Vector__XXX
 SG_ HvBattCellURSMS188 : 183|13@0+ (0.001,0.0) [0.0|8.191] "V" Vector__XXX
 SG_ HvBattCellURSMS189 : 199|13@0+ (0.001,0.0) [0.0|8.191] "V" Vector__XXX
 SG_ HvBattCellURSMS190 : 215|13@0+ (0.001,0.0) [0.0|8.191] "V" Vector__XXX
 SG_ HvBattCellURSMS191 : 231|13@0+ (0.001,0.0) [0.0|8.191] "V" Vector__XXX
 SG_ HvBattCellURSMS192 : 247|13@0+ (0.001,0.0) [0.0|8.191] "V" Vector__XXX

BO_ 652 BMS_PTCANFD_0x28C : 32 BMS
 SG_ HvBattCellURSMS193 : 7|13@0+ (0.001,0.0) [0.0|8.191] "V" Vector__XXX
 SG_ HvBattCellURSMS194 : 23|13@0+ (0.001,0.0) [0.0|8.191] "V" Vector__XXX
 SG_ HvBattCellURSMS195 : 39|13@0+ (0.001,0.0) [0.0|8.191] "V" Vector__XXX
 SG_ HvBattCellURSMS196 : 55|13@0+ (0.001,0.0) [0.0|8.191] "V" Vector__XXX
 SG_ HvBattCellURSMS197 : 71|13@0+ (0.001,0.0) [0.0|8.191] "V" Vector__XXX
 SG_ HvBattCellURSMS198 : 87|13@0+ (0.001,0.0) [0.0|8.191] "V" Vector__XXX
 SG_ HvBattCellURSMS199 : 103|13@0+ (0.001,0.0) [0.0|8.191] "V" Vector__XXX
 SG_ HvBattCellURSMS200 : 119|13@0+ (0.001,0.0) [0.0|8.191] "V" Vector__XXX
 SG_ HvBattCellURSMS201 : 135|13@0+ (0.001,0.0) [0.0|8.191] "V" Vector__XXX
 SG_ HvBattCellURSMS202 : 151|13@0+ (0.001,0.0) [0.0|8.191] "V" Vector__XXX
 SG_ HvBattCellURSMS203 : 167|13@0+ (0.001,0.0) [0.0|8.191] "V" Vector__XXX
 SG_ HvBattCellURSMS204 : 183|13@0+ (0.001,0.0) [0.0|8.191] "V" Vector__XXX
 SG_ HvBattCellURSMS205 : 199|13@0+ (0.001,0.0) [0.0|8.191] "V" Vector__XXX
 SG_ HvBattCellURSMS206 : 215|13@0+ (0.001,0.0) [0.0|8.191] "V" Vector__XXX
 SG_ HvBattCellURSMS207 : 231|13@0+ (0.001,0.0) [0.0|8.191] "V" Vector__XXX
 SG_ HvBattCellURSMS208 : 247|13@0+ (0.001,0.0) [0.0|8.191] "V" Vector__XXX

BO_ 653 BMS_PTCANFD_0x28D : 32 BMS
 SG_ HvBattCellURSMS209 : 7|13@0+ (0.001,0.0) [0.0|8.191] "V" Vector__XXX
 SG_ HvBattCellURSMS210 : 23|13@0+ (0.001,0.0) [0.0|8.191] "V" Vector__XXX
 SG_ HvBattCellURSMS211 : 39|13@0+ (0.001,0.0) [0.0|8.191] "V" Vector__XXX
 SG_ HvBattCellURSMS212 : 55|13@0+ (0.001,0.0) [0.0|8.191] "V" Vector__XXX
 SG_ HvBattCellURSMS213 : 71|13@0+ (0.001,0.0) [0.0|8.191] "V" Vector__XXX
 SG_ HvBattCellURSMS214 : 87|13@0+ (0.001,0.0) [0.0|8.191] "V" Vector__XXX
 SG_ HvBattCellURSMS215 : 103|13@0+ (0.001,0.0) [0.0|8.191] "V" Vector__XXX
 SG_ HvBattCellURSMS216 : 119|13@0+ (0.001,0.0) [0.0|8.191] "V" Vector__XXX
 SG_ HvBattCellURSMS217 : 135|13@0+ (0.001,0.0) [0.0|8.191] "V" Vector__XXX
 SG_ HvBattCellURSMS218 : 151|13@0+ (0.001,0.0) [0.0|8.191] "V" Vector__XXX
 SG_ HvBattCellURSMS219 : 167|13@0+ (0.001,0.0) [0.0|8.191] "V" Vector__XXX
 SG_ HvBattCellURSMS220 : 183|13@0+ (0.001,0.0) [0.0|8.191] "V" Vector__XXX
 SG_ HvBattCellURSMS221 : 199|13@0+ (0.001,0.0) [0.0|8.191] "V" Vector__XXX
 SG_ HvBattCellURSMS222 : 215|13@0+ (0.001,0.0) [0.0|8.191] "V" Vector__XXX
 SG_ HvBattCellURSMS223 : 231|13@0+ (0.001,0.0) [0.0|8.191] "V" Vector__XXX
 SG_ HvBattCellURSMS224 : 247|13@0+ (0.001,0.0) [0.0|8.191] "V" Vector__XXX

BO_ 654 BMS_PTCANFD_0x28E : 32 BMS
 SG_ HvBattCellURSMS225 : 7|13@0+ (0.001,0.0) [0.0|8.191] "V" Vector__XXX
 SG_ HvBattCellURSMS226 : 23|13@0+ (0.001,0.0) [0.0|8.191] "V" Vector__XXX
 SG_ HvBattCellURSMS227 : 39|13@0+ (0.001,0.0) [0.0|8.191] "V" Vector__XXX
 SG_ HvBattCellURSMS228 : 55|13@0+ (0.001,0.0) [0.0|8.191] "V" Vector__XXX
 SG_ HvBattCellURSMS229 : 71|13@0+ (0.001,0.0) [0.0|8.191] "V" Vector__XXX
 SG_ HvBattCellURSMS230 : 87|13@0+ (0.001,0.0) [0.0|8.191] "V" Vector__XXX
 SG_ HvBattCellURSMS231 : 103|13@0+ (0.001,0.0) [0.0|8.191] "V" Vector__XXX
 SG_ HvBattCellURSMS232 : 119|13@0+ (0.001,0.0) [0.0|8.191] "V" Vector__XXX
 SG_ HvBattCellURSMS233 : 135|13@0+ (0.001,0.0) [0.0|8.191] "V" Vector__XXX
 SG_ HvBattCellURSMS234 : 151|13@0+ (0.001,0.0) [0.0|8.191] "V" Vector__XXX
 SG_ HvBattCellURSMS235 : 167|13@0+ (0.001,0.0) [0.0|8.191] "V" Vector__XXX
 SG_ HvBattCellURSMS236 : 183|13@0+ (0.001,0.0) [0.0|8.191] "V" Vector__XXX
 SG_ HvBattCellURSMS237 : 199|13@0+ (0.001,0.0) [0.0|8.191] "V" Vector__XXX
 SG_ HvBattCellURSMS238 : 215|13@0+ (0.001,0.0) [0.0|8.191] "V" Vector__XXX
 SG_ HvBattCellURSMS239 : 231|13@0+ (0.001,0.0) [0.0|8.191] "V" Vector__XXX
 SG_ HvBattCellURSMS240 : 247|13@0+ (0.001,0.0) [0.0|8.191] "V" Vector__XXX

BO_ 678 BMS_PTCANFD_0x2A6 : 32 BMS
 SG_ BmsFaultReact : 119|32@0+ (1.0,0.0) [0.0|4294967295.0] "" Vector__XXX
 SG_ GeTHRBpsSensorErrFault : 104|1@0+ (1.0,0.0) [0.0|1.0] "" Vector__XXX
 SG_ HallCurrSampDiag : 151|8@0+ (1,0) [0|255] "" Vector__XXX
 SG_ HvBattCellSocSts : 159|8@0+ (1.0,0.0) [0.0|255.0] "" Vector__XXX
 SG_ HvBattCellTempNotOkNum : 167|8@0+ (1,0) [0|255] "" Vector__XXX
 SG_ HvBattCellVoltNotOkNum : 175|8@0+ (1,0) [0|255] "" Vector__XXX
 SG_ HvBattChrgnDrtRsn : 183|4@0+ (1.0,0.0) [0.0|15.0] "" Vector__XXX
 SG_ HvBattDcChgSts : 231|5@0+ (1,0) [0|31] "" Vector__XXX
 SG_ HvBattDchaSocThisDischrgnCyc : 226|11@0+ (0.05,0.0) [0.0|100.05000000000001] "%" Vector__XXX
 SG_ HvBattDchrgnDrtRsn : 179|4@0+ (1.0,0.0) [0.0|15.0] "" Vector__XXX
 SG_ HvBattHvRawU2 : 7|15@0+ (0.1,-1638.4) [-1638.4|1638.3000000000002] "V" Vector__XXX
 SG_ HvBattHvRawU3 : 23|15@0+ (0.1,-1638.4) [-1638.4|1638.3000000000002] "V" Vector__XXX
 SG_ HvBattHvRawU4 : 39|15@0+ (0.1,-1638.4) [-1638.4|1638.3000000000002] "V" Vector__XXX
 SG_ HvBattHvRawU5 : 55|15@0+ (0.1,-1638.4) [-1638.4|1638.3000000000002] "V" Vector__XXX
 SG_ HvBattHvRawU6 : 71|15@0+ (0.1,-1638.4) [-1638.4|1638.3000000000002] "V" Vector__XXX
 SG_ HvBattHvRawU7 : 87|15@0+ (0.1,-1638.4) [-1638.4|1638.3000000000002] "V" Vector__XXX
 SG_ HvBattHvRawU8 : 103|15@0+ (0.1,-1638.4) [-1638.4|1638.3000000000002] "V" Vector__XXX
 SG_ HvBattLeakSensU : 223|8@0+ (0.1,0.0) [0.0|25.5] "V" Vector__XXX
 SG_ HvBattPfcChipDiag : 191|8@0+ (1,0) [0|255] "" Vector__XXX
 SG_ HvBattPfcDeploySts : 199|8@0+ (1,0) [0|255] "" Vector__XXX
 SG_ HvBattPheatgForChrgnFnshTi : 247|6@0+ (1.0,0.0) [0.0|63.0] "" Vector__XXX
 SG_ HvBattRutPheatgFinshd : 255|3@0+ (1.0,0.0) [0.0|4.0] "" Vector__XXX
 SG_ HVSampDiag : 207|8@0+ (1,0) [0|255] "" Vector__XXX
 SG_ ShuntCurrSampDiag : 215|8@0+ (1,0) [0|255] "" Vector__XXX

BO_ 679 BMS_PTCANFD_0x2A7 : 32 BMS
 SG_ HvBattCellURSMS241 : 7|13@0+ (0.001,0.0) [0.0|8.191] "V" Vector__XXX
 SG_ HvBattCellURSMS242 : 23|13@0+ (0.001,0.0) [0.0|8.191] "V" Vector__XXX
 SG_ HvBattCellURSMS243 : 39|13@0+ (0.001,0.0) [0.0|8.191] "V" Vector__XXX
 SG_ HvBattCellURSMS244 : 55|13@0+ (0.001,0.0) [0.0|8.191] "V" Vector__XXX
 SG_ HvBattCellURSMS245 : 71|13@0+ (0.001,0.0) [0.0|8.191] "V" Vector__XXX
 SG_ HvBattCellURSMS246 : 87|13@0+ (0.001,0.0) [0.0|8.191] "V" Vector__XXX
 SG_ HvBattCellURSMS247 : 103|13@0+ (0.001,0.0) [0.0|8.191] "V" Vector__XXX
 SG_ HvBattCellURSMS248 : 119|13@0+ (0.001,0.0) [0.0|8.191] "V" Vector__XXX
 SG_ HvBattCellURSMS249 : 135|13@0+ (0.001,0.0) [0.0|8.191] "V" Vector__XXX
 SG_ HvBattCellURSMS250 : 151|13@0+ (0.001,0.0) [0.0|8.191] "V" Vector__XXX
 SG_ HvBattCellURSMS251 : 167|13@0+ (0.001,0.0) [0.0|8.191] "V" Vector__XXX
 SG_ HvBattCellURSMS252 : 183|13@0+ (0.001,0.0) [0.0|8.191] "V" Vector__XXX
 SG_ HvBattCellURSMS253 : 199|13@0+ (0.001,0.0) [0.0|8.191] "V" Vector__XXX
 SG_ HvBattCellURSMS254 : 215|13@0+ (0.001,0.0) [0.0|8.191] "V" Vector__XXX
 SG_ HvBattCellURSMS255 : 231|13@0+ (0.001,0.0) [0.0|8.191] "V" Vector__XXX
 SG_ HvBattCellURSMS256 : 247|13@0+ (0.001,0.0) [0.0|8.191] "V" Vector__XXX

BO_ 821 BMS_PTCANFD_0x335 : 64 BMS
 SG_ HvBattAFEErrMsk1 : 7|32@0+ (1.0,0.0) [0.0|4294967295.0] "" Vector__XXX
 SG_ HvBattAFEErrMsk2 : 39|32@0+ (1.0,0.0) [0.0|4294967295.0] "" Vector__XXX
 SG_ HvBattAFEErrMsk3 : 71|32@0+ (1.0,0.0) [0.0|4294967295.0] "" Vector__XXX
 SG_ HvBattAFEErrMsk4 : 103|32@0+ (1.0,0.0) [0.0|4294967295.0] "" Vector__XXX
 SG_ HvBattBJBErrMsk1 : 135|32@0+ (1.0,0.0) [0.0|4294967295.0] "" Vector__XXX
 SG_ HvBattBJBErrMsk2 : 167|32@0+ (1.0,0.0) [0.0|4294967295.0] "" Vector__XXX
 SG_ HvBattBJBErrMsk3 : 199|32@0+ (1.0,0.0) [0.0|4294967295.0] "" Vector__XXX
 SG_ HvBattMCUErrMsk1 : 231|32@0+ (1.0,0.0) [0.0|4294967295.0] "" Vector__XXX
 SG_ HvBattMCUErrMsk2 : 263|32@0+ (1.0,0.0) [0.0|4294967295.0] "" Vector__XXX
 SG_ HvBattMCUErrMsk3 : 295|32@0+ (1.0,0.0) [0.0|4294967295.0] "" Vector__XXX
 SG_ HvBattMCUErrMsk4 : 327|32@0+ (1.0,0.0) [0.0|4294967295.0] "" Vector__XXX
 SG_ HvBattMCUErrMsk5 : 359|32@0+ (1.0,0.0) [0.0|4294967295.0] "" Vector__XXX
 SG_ HvBattMCUErrMsk6 : 391|32@0+ (1.0,0.0) [0.0|4294967295.0] "" Vector__XXX
 SG_ HvBattMCUErrMsk7 : 423|32@0+ (1.0,0.0) [0.0|4294967295.0] "" Vector__XXX
 SG_ HvBattMCUErrMsk8 : 455|32@0+ (1.0,0.0) [0.0|4294967295.0] "" Vector__XXX
 SG_ HvBattSBCErrMsk1 : 487|32@0+ (1.0,0.0) [0.0|4294967295.0] "" Vector__XXX

BO_ 832 BMS_PTCANFD_0x340 : 32 BMS
 SG_ HvBattTempRSMS1 : 7|9@0+ (0.5,-40.0) [-40.0|215.0] "℃" Vector__XXX
 SG_ HvBattTempRSMS10 : 151|9@0+ (0.5,-40.0) [-40.0|215.0] "℃" Vector__XXX
 SG_ HvBattTempRSMS11 : 167|9@0+ (0.5,-40.0) [-40.0|215.0] "℃" Vector__XXX
 SG_ HvBattTempRSMS12 : 183|9@0+ (0.5,-40.0) [-40.0|215.0] "℃" Vector__XXX
 SG_ HvBattTempRSMS13 : 199|9@0+ (0.5,-40.0) [-40.0|215.0] "℃" Vector__XXX
 SG_ HvBattTempRSMS14 : 215|9@0+ (0.5,-40.0) [-40.0|215.0] "℃" Vector__XXX
 SG_ HvBattTempRSMS15 : 231|9@0+ (0.5,-40.0) [-40.0|215.0] "℃" Vector__XXX
 SG_ HvBattTempRSMS16 : 247|9@0+ (0.5,-40.0) [-40.0|215.0] "℃" Vector__XXX
 SG_ HvBattTempRSMS2 : 23|9@0+ (0.5,-40.0) [-40.0|215.0] "℃" Vector__XXX
 SG_ HvBattTempRSMS3 : 39|9@0+ (0.5,-40.0) [-40.0|215.0] "℃" Vector__XXX
 SG_ HvBattTempRSMS4 : 55|9@0+ (0.5,-40.0) [-40.0|215.0] "℃" Vector__XXX
 SG_ HvBattTempRSMS5 : 71|9@0+ (0.5,-40.0) [-40.0|215.0] "℃" Vector__XXX
 SG_ HvBattTempRSMS6 : 87|9@0+ (0.5,-40.0) [-40.0|215.0] "℃" Vector__XXX
 SG_ HvBattTempRSMS7 : 103|9@0+ (0.5,-40.0) [-40.0|215.0] "℃" Vector__XXX
 SG_ HvBattTempRSMS8 : 119|9@0+ (0.5,-40.0) [-40.0|215.0] "℃" Vector__XXX
 SG_ HvBattTempRSMS9 : 135|9@0+ (0.5,-40.0) [-40.0|215.0] "℃" Vector__XXX

BO_ 843 BMS_PTCANFD_0x34B : 8 BMS
 SG_ DcChrgDegradedID : 7|8@0+ (1.0,0.0) [0.0|255.0] "" Vector__XXX
 SG_ HvBattChrgFailrRsnID : 15|8@0+ (1.0,0.0) [0.0|255.0] "" Vector__XXX

BO_ 901 BMS_PTCANFD_0x385 : 32 BMS
 SG_ HVBattCellVoltCpnsInfo : 199|32@0+ (1.0,0.0) [0.0|4294967295.0] "" Vector__XXX
 SG_ HvBattCooltTReq : 135|8@0+ (1.0,-40.0) [-40.0|210.0] "℃" Vector__XXX
 SG_ HvBattDCchrgdEgyThisChrgnCyc : 175|17@0+ (1.0,0.0) [0.0|131071.0] "wh" Vector__XXX
 SG_ HvBattDevmtGrp05 : 7|32@0+ (1.0,0.0) [0.0|0.0] "" Vector__XXX
 SG_ HvBattDevmtGrp06 : 39|32@0+ (1.0,0.0) [0.0|0.0] "" Vector__XXX
 SG_ HvBattDevmtGrp07 : 71|32@0+ (1.0,0.0) [0.0|0.0] "" Vector__XXX
 SG_ HvBattDevmtGrp08 : 103|32@0+ (1.0,0.0) [0.0|0.0] "" Vector__XXX
 SG_ HvBattEgyDispForChrgnToTarSoC : 143|13@0+ (20.0,0.0) [0.0|163000.0] "" Vector__XXX
 SG_ HvBattEgyDispForDchrgnToTarSoC : 159|13@0+ (20.0,0.0) [0.0|163000.0] "" Vector__XXX

BO_ 912 BMS_PTCANFD_0x390 : 32 BMS
 SG_ BalOnCellNumb : 207|8@0+ (1.0,0.0) [0.0|255.0] "" Vector__XXX
 SG_ CMU1ComErrTi : 87|8@0+ (0.5,0.0) [0.0|127.5] "s" Vector__XXX
 SG_ CMU2ComErrTi : 95|8@0+ (0.5,0.0) [0.0|127.5] "s" Vector__XXX
 SG_ CMU3ComErrTi : 103|8@0+ (0.5,0.0) [0.0|127.5] "s" Vector__XXX
 SG_ HvBattCellAvrgSocErr : 135|11@0+ (0.05,0.0) [0.0|100.0] "%" Vector__XXX
 SG_ HvBattCellMaxSoc : 114|11@0+ (0.05,0.0) [0.0|100.0] "%" Vector__XXX
 SG_ HvBattCellMaxSocErr : 183|11@0+ (0.05,0.0) [0.0|100.0] "%" Vector__XXX
 SG_ HvBattCellMaxSocErrIdx : 175|8@0+ (1.0,0.0) [1.0|255.0] "" Vector__XXX
 SG_ HvBattCellMaxSocIdx : 159|8@0+ (1.0,0.0) [1.0|255.0] "" Vector__XXX
 SG_ HvBattCellMinSoc : 186|11@0+ (0.05,0.0) [0.0|100.0] "%" Vector__XXX
 SG_ HvBattCellMinSocIdx : 167|8@0+ (1.0,0.0) [1.0|255.0] "" Vector__XXX
 SG_ HvBattEgyAvlForChrgnToTarSoC : 55|13@0+ (20.0,0.0) [0.0|163000.0] "Wh" Vector__XXX
 SG_ HvBattEgyAvlForDchrgnToTarSoC : 39|13@0+ (20.0,0.0) [0.0|163000.0] "Wh" Vector__XXX
 SG_ HvBattPressureInsdPack : 71|12@0+ (0.1,0.0) [0.0|409.40000000000003] "kPa" Vector__XXX
 SG_ HvBattSoCLimMax : 7|11@0+ (0.05,0.0) [0.0|100.0] "%" Vector__XXX
 SG_ HvBattSoCLimMin : 23|11@0+ (0.05,0.0) [0.0|100.0] "%" Vector__XXX
 SG_ HvPrechargeTimer : 140|13@0+ (1.0,0.0) [0.0|8191.0] "" Vector__XXX

BO_ 916 BMS_PTCANFD_0x394 : 8 BMS
 SG_ HvBattDchaEgyThisCycRSMS : 18|11@0+ (0.1,0.0) [0.0|204.70000000000002] "kWh" Vector__XXX
 SG_ HvBattRecupEgyThisCycRSMS : 39|11@0+ (0.1,0.0) [0.0|204.70000000000002] "kWh" Vector__XXX

BO_ 928 BMS_PTCANFD_0x3A0 : 64 BMS
 SG_ EaCTCCutoffCounter0 : 7|32@0+ (1.0,0.0) [0.0|4294967295.0] "" Vector__XXX
 SG_ EaCTCCutoffCounter1 : 39|32@0+ (1.0,0.0) [0.0|4294967295.0] "" Vector__XXX
 SG_ EaCTCCutoffCounter2 : 71|32@0+ (1.0,0.0) [0.0|4294967295.0] "" Vector__XXX
 SG_ EaCTCCutoffCounter3 : 103|32@0+ (1.0,0.0) [0.0|4294967295.0] "" Vector__XXX
 SG_ EaCTCCutoffCounter4 : 135|32@0+ (1.0,0.0) [0.0|4294967295.0] "" Vector__XXX
 SG_ EaCTCCutoffCounter5 : 167|32@0+ (1.0,0.0) [0.0|4294967295.0] "" Vector__XXX
 SG_ EaCTCCutoffCounter6 : 199|32@0+ (1.0,0.0) [0.0|4294967295.0] "" Vector__XXX
 SG_ EaCTCCutoffCounter7 : 231|32@0+ (1.0,0.0) [0.0|4294967295.0] "" Vector__XXX
 SG_ HvBattChargePwrLimit : 311|16@0+ (1.0,0.0) [0.0|65535.0] "kW" Vector__XXX
 SG_ HvBattChargerMaxPwr : 327|16@0+ (1.0,0.0) [0.0|65535.0] "kW" Vector__XXX
 SG_ HvBattChrgnMapCurr : 343|16@0+ (0.1,-3276.8) [-3276.8|3276.7] "A" Vector__XXX
 SG_ HVBattChrgQuaInf : 263|24@0+ (1.0,0.0) [0.0|16777215.0] "" Vector__XXX
 SG_ HvbattChrgrPlsCurLv1Cnt : 383|8@0+ (1.0,0.0) [0.0|254.0] "" Vector__XXX
 SG_ HvBattCondPredIndex : 359|8@0+ (1.0,0.0) [0.0|255.0] "" Vector__XXX
 SG_ HVBattDaisyChnQuaInf : 287|24@0+ (1.0,0.0) [0.0|16777215.0] "" Vector__XXX
 SG_ HvBattDCChrgrCc1Volt : 367|8@0+ (0.1,0.0) [0.0|25.5] "V" Vector__XXX
 SG_ HvBattDCChrgrCc2Volt : 375|8@0+ (0.1,0.0) [0.0|25.5] "V" Vector__XXX
 SG_ HvBattSOCFcn1 : 391|16@0+ (1.0,0.0) [0.0|65535.0] "" Vector__XXX
 SG_ HvBattSOCFcn2 : 407|16@0+ (1.0,0.0) [0.0|65535.0] "" Vector__XXX
 SG_ HvBattSOCFcn3 : 423|16@0+ (1.0,0.0) [0.0|65535.0] "" Vector__XXX
 SG_ HvBattSOCFcn4 : 439|16@0+ (1.0,0.0) [0.0|65535.0] "" Vector__XXX
 SG_ HvBattSOCFcn5 : 455|16@0+ (1.0,0.0) [0.0|65535.0] "" Vector__XXX
 SG_ HvBattSOCFcn6 : 471|16@0+ (1.0,0.0) [0.0|65535.0] "" Vector__XXX
 SG_ HvBattSOCFcn7 : 487|16@0+ (1.0,0.0) [0.0|65535.0] "" Vector__XXX
 SG_ HvBattSOCFcn8 : 503|16@0+ (1.0,0.0) [0.0|65535.0] "" Vector__XXX

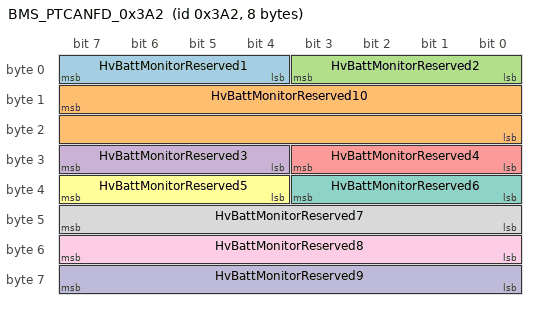
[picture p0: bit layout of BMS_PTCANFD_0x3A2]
BO_ 930 BMS_PTCANFD_0x3A2 : 8 BMS
 SG_ HvBattMonitorReserved1 : 7|4@0+ (1.0,0.0) [0.0|15.0] "" Vector__XXX
 SG_ HvBattMonitorReserved10 : 15|16@0+ (1.0,0.0) [0.0|65535.0] "" Vector__XXX
 SG_ HvBattMonitorReserved2 : 3|4@0+ (1.0,0.0) [0.0|15.0] "" Vector__XXX
 SG_ HvBattMonitorReserved3 : 31|4@0+ (1.0,0.0) [0.0|15.0] "" Vector__XXX
 SG_ HvBattMonitorReserved4 : 27|4@0+ (1.0,0.0) [0.0|15.0] "" Vector__XXX
 SG_ HvBattMonitorReserved5 : 39|4@0+ (1.0,0.0) [0.0|15.0] "" Vector__XXX
 SG_ HvBattMonitorReserved6 : 35|4@0+ (1.0,0.0) [0.0|15.0] "" Vector__XXX
 SG_ HvBattMonitorReserved7 : 47|8@0+ (1.0,0.0) [0.0|255.0] "" Vector__XXX
 SG_ HvBattMonitorReserved8 : 55|8@0+ (1.0,0.0) [0.0|255.0] "" Vector__XXX
 SG_ HvBattMonitorReserved9 : 63|8@0+ (1.0,0.0) [0.0|255.0] "" Vector__XXX

BO_ 991 BMS_PTCANFD_0x3DF : 16 BMS
 SG_ FlybackCtrReqRsn : 119|16@0+ (1.0,0.0) [0.0|65535.0] "" Vector__XXX
 SG_ HvBattActvHeatTrfPwrTar : 103|10@0- (100.0,0.0) [-51200.0|51100.0] "W" Vector__XXX
 SG_ HvBattSocCalcResv1 : 7|8@0+ (1.0,0.0) [0.0|255.0] "" Vector__XXX
 SG_ HvBattSocCalcResv2 : 15|8@0+ (1.0,0.0) [0.0|255.0] "" Vector__XXX
 SG_ HvBattSocCalcResv3 : 23|8@0+ (1.0,0.0) [0.0|255.0] "" Vector__XXX
 SG_ HvBattSocCalcResv4 : 31|8@0+ (1.0,0.0) [0.0|255.0] "" Vector__XXX
 SG_ HvBattSocCalcResv5 : 39|16@0+ (1.0,0.0) [0.0|65535.0] "" Vector__XXX
 SG_ HvBattSocCalcResv6 : 55|16@0+ (1.0,0.0) [0.0|65535.0] "" Vector__XXX
 SG_ HvBattSocCalcResv7 : 71|16@0+ (1.0,0.0) [0.0|65535.0] "" Vector__XXX
 SG_ HvBattSocCalcResv8 : 87|16@0+ (1.0,0.0) [0.0|65535.0] "" Vector__XXX

BO_ 1001 BMS_PTCANFD_0x3E9 : 64 BMS
 SG_ BMUMcuResetReason : 7|32@0+ (1.0,0.0) [0.0|4294967295.0] "" Vector__XXX
 SG_ BMUNVFault : 316|1@0+ (1,0) [0|1] "" Vector__XXX
 SG_ HvBattAFECellTempLF : 327|16@0+ (1,0) [0|65535] "" Vector__XXX
 SG_ HvBattAFECellVoltLF : 391|16@0+ (1,0) [0|65535] "" Vector__XXX
 SG_ HvBattBMSTotTiHrWithTempRSMS : 39|17@0+ (1.0,0.0) [0.0|131071.0] "Hour" Vector__XXX
 SG_ HvBattBMSTotTiHrWithTempRSMSCode : 54|4@0+ (1.0,0.0) [0.0|15.0] "" Vector__XXX
 SG_ HvBattBPSDiag : 315|4@0+ (1,0) [0|15] "" Vector__XXX
 SG_ HvBattCellBalAllwSts : 407|16@0+ (1.0,0.0) [0.0|65535.0] "" Vector__XXX
 SG_ HvBattCellBalAllwStsIdx : 423|8@0+ (1.0,0.0) [0.0|255.0] "" Vector__XXX
 SG_ HvBattCellBalRemainITIdx : 431|8@0+ (1.0,0.0) [0.0|255.0] "" Vector__XXX
 SG_ HvBattCellBalRemainTi : 439|16@0+ (1.0,0.0) [0.0|65535.0] "min" Vector__XXX
 SG_ HvBattCellBalTempMax : 455|8@0+ (1.0,-40.0) [-40.0|215.0] "" Vector__XXX
 SG_ HvBattCellBBTemp1 : 264|9@0+ (0.5,-40.0) [-40.0|215.5] "" Vector__XXX
 SG_ HvBattCellBBTemp2 : 287|9@0+ (0.5,-40.0) [-40.0|215.5] "" Vector__XXX
 SG_ HvBattCellBBTemp3 : 368|9@0+ (0.5,-40.0) [-40.0|215.5] "℃" Vector__XXX
 SG_ HvBattCellBBTemp4 : 463|9@0+ (0.5,-40.0) [-40.0|215.5] "℃" Vector__XXX
 SG_ HvBattCellBBTemp5 : 464|9@0+ (0.5,-40.0) [-40.0|215.5] "℃" Vector__XXX
 SG_ HvBattCellBBTemp6 : 487|9@0+ (0.5,-40.0) [-40.0|215.5] "℃" Vector__XXX
 SG_ HvBattCellBBVltg1 : 290|11@0+ (0.001,-1.0) [-1.0|1.0470000000000002] "" Vector__XXX
 SG_ HvBattCellBBVltg2 : 311|11@0+ (0.001,-1.0) [-1.0|1.0470000000000002] "" Vector__XXX
 SG_ HvBattCellLastCalCapRSMS : 63|8@0+ (0.5,0.0) [0.0|127.5] "%" Vector__XXX
 SG_ HvBattCellLastCalCapRSMSCode : 71|8@0+ (1.0,0.0) [0.0|255.0] "" Vector__XXX
 SG_ HvBattCellTotBalAsRSMS : 79|23@0+ (1.0,0.0) [0.0|8388607.0] "As" Vector__XXX
 SG_ HvBattCellTotBalAsRSMSCode : 103|8@0+ (1.0,0.0) [0.0|255.0] "" Vector__XXX
 SG_ HvBattChipBalSts : 503|16@0+ (1.0,0.0) [0.0|65535.0] "" Vector__XXX
 SG_ HvBattChipBalStsIdx : 470|4@0+ (1.0,0.0) [0.0|15.0] "" Vector__XXX
 SG_ HvBattCntctClsdTimesRSMS : 111|23@0+ (1.0,0.0) [0.0|8388607.0] "" Vector__XXX
 SG_ HvBattCpCalcdCnt : 135|16@0+ (1.0,0.0) [0.0|65535.0] "" Vector__XXX
 SG_ HvBattCpUpdRsn : 50|3@0+ (1.0,0.0) [0.0|7.0] "" Vector__XXX
 SG_ HvBattHvBoxBBTemp1 : 343|9@0+ (0.5,-40.0) [-40.0|215.5] "" Vector__XXX
 SG_ HvBattHvBoxBBTemp2 : 344|9@0+ (0.5,-40.0) [-40.0|215.5] "" Vector__XXX
 SG_ HvBattHvBoxBBTemp3 : 367|9@0+ (0.5,-40.0) [-40.0|215.5] "" Vector__XXX
 SG_ HvBattPriorityThermalSt : 88|1@0+ (1.0,0.0) [0.0|1.0] "" Vector__XXX
 SG_ HvBattRCalcdCnt : 151|16@0+ (1.0,0.0) [0.0|65535.0] "" Vector__XXX
 SG_ HvBattRUpdRsn : 271|3@0+ (1.0,0.0) [0.0|7.0] "" Vector__XXX
 SG_ HvBattShuntLF : 466|1@0+ (1,0) [0|1] "" Vector__XXX
 SG_ HvBattThermalTiOut : 120|1@0+ (1.0,0.0) [0.0|1.0] "" Vector__XXX
 SG_ HvBattThrSigFlgRsn : 167|24@0+ (1.0,0.0) [0.0|16777215.0] "" Vector__XXX
 SG_ HvBattTotEgyAhWithCRateRSMS : 191|23@0+ (1.0,0.0) [0.0|8388607.0] "Ah" Vector__XXX
 SG_ HvBattTotEgyAhWithCRateRSMSCode : 215|8@0+ (1.0,0.0) [0.0|255.0] "" Vector__XXX
 SG_ HvBattTotEgyAhWithTempRSMS : 223|23@0+ (1.0,0.0) [0.0|8388607.0] "Ah" Vector__XXX
 SG_ HvBattTotEgyAhWithTempRSMSCode : 247|8@0+ (1.0,0.0) [0.0|255.0] "" Vector__XXX
 SG_ HvBattTotOverCurrAh : 255|16@0+ (0.01,0.0) [0.0|655.35] "Ah" Vector__XXX

BO_ 1003 BMS_PTCANFD_0x3EB : 64 BMS
 SG_ HvBattRemaChrgnTiChrgrInfo1 : 7|16@0+ (1.0,0.0) [0.0|65535.0] "" Vector__XXX
 SG_ HvBattRemaChrgnTiChrgrInfo2 : 23|16@0+ (1.0,0.0) [0.0|65535.0] "" Vector__XXX
 SG_ HvBattRemaChrgnTiChrgrInfo3 : 39|16@0+ (1.0,0.0) [0.0|65535.0] "" Vector__XXX
 SG_ HvBattRemaChrgnTiChrgrInfo4 : 55|16@0+ (1.0,0.0) [0.0|65535.0] "" Vector__XXX
 SG_ HvBattRemaChrgnTiChrgrInfo5 : 71|16@0+ (1.0,0.0) [0.0|65535.0] "" Vector__XXX
 SG_ HvBattRemaChrgnTiChrgrInfo6 : 87|16@0+ (1.0,0.0) [0.0|65535.0] "" Vector__XXX
 SG_ HvBattRemaChrgnTiChrgrInfo7 : 103|16@0+ (1.0,0.0) [0.0|65535.0] "" Vector__XXX
 SG_ HvBattRemaChrgnTiChrgrInfo8 : 119|16@0+ (1.0,0.0) [0.0|65535.0] "" Vector__XXX
 SG_ HvBattRemaChrgnTiCtrlCur : 135|16@0+ (1.0,0.0) [0.0|65535.0] "" Vector__XXX
 SG_ HvBattRemaChrgnTiCtrlU : 151|16@0+ (1.0,0.0) [0.0|65535.0] "" Vector__XXX
 SG_ HvBattRutPheatgThermReqSoc1 : 167|16@0+ (1.0,0.0) [0.0|65535.0] "" Vector__XXX
 SG_ HvBattRutPheatgThermReqSoc10 : 183|16@0+ (1.0,0.0) [0.0|65535.0] "" Vector__XXX
 SG_ HvBattRutPheatgThermReqSoc11 : 199|16@0+ (1.0,0.0) [0.0|65535.0] "" Vector__XXX
 SG_ HvBattRutPheatgThermReqSoc12 : 215|16@0+ (1.0,0.0) [0.0|65535.0] "" Vector__XXX
 SG_ HvBattRutPheatgThermReqSoc13 : 231|16@0+ (1.0,0.0) [0.0|65535.0] "" Vector__XXX
 SG_ HvBattRutPheatgThermReqSoc14 : 247|16@0+ (1.0,0.0) [0.0|65535.0] "" Vector__XXX
 SG_ HvBattRutPheatgThermReqSoc15 : 263|16@0+ (1.0,0.0) [0.0|65535.0] "" Vector__XXX
 SG_ HvBattRutPheatgThermReqSoc16 : 279|16@0+ (1.0,0.0) [0.0|65535.0] "" Vector__XXX
 SG_ HvBattRutPheatgThermReqSoc17 : 295|16@0+ (1.0,0.0) [0.0|65535.0] "" Vector__XXX
 SG_ HvBattRutPheatgThermReqSoc18 : 311|16@0+ (1.0,0.0) [0.0|65535.0] "" Vector__XXX
 SG_ HvBattRutPheatgThermReqSoc19 : 327|16@0+ (1.0,0.0) [0.0|65535.0] "" Vector__XXX
 SG_ HvBattRutPheatgThermReqSoc2 : 343|16@0+ (1.0,0.0) [0.0|65535.0] "" Vector__XXX
 SG_ HvBattRutPheatgThermReqSoc20 : 359|16@0+ (1.0,0.0) [0.0|65535.0] "" Vector__XXX
 SG_ HvBattRutPheatgThermReqSoc3 : 375|16@0+ (1.0,0.0) [0.0|65535.0] "" Vector__XXX
 SG_ HvBattRutPheatgThermReqSoc4 : 391|16@0+ (1.0,0.0) [0.0|65535.0] "" Vector__XXX
 SG_ HvBattRutPheatgThermReqSoc5 : 407|16@0+ (1.0,0.0) [0.0|65535.0] "" Vector__XXX
 SG_ HvBattRutPheatgThermReqSoc6 : 423|16@0+ (1.0,0.0) [0.0|65535.0] "" Vector__XXX
 SG_ HvBattRutPheatgThermReqSoc7 : 439|16@0+ (1.0,0.0) [0.0|65535.0] "" Vector__XXX
 SG_ HvBattRutPheatgThermReqSoc8 : 455|16@0+ (1.0,0.0) [0.0|65535.0] "" Vector__XXX
 SG_ HvBattRutPheatgThermReqSoc9 : 471|16@0+ (1.0,0.0) [0.0|65535.0] "" Vector__XXX
 SG_ HvBattShuntDriftCurr : 487|16@0+ (0.1,-3276.8) [-3276.8|3276.7] "A" Vector__XXX

BO_ 1005 BMS_PTCANFD_0x3ED : 48 BMS
 SG_ DCCnctrNegTemp : 15|8@0+ (1.0,-40.0) [-40.0|214.0] "℃" Vector__XXX
 SG_ DCCnctrPosTemp : 23|8@0+ (1.0,-40.0) [-40.0|214.0] "℃" Vector__XXX
 SG_ HvBattCapRSMS : 7|8@0+ (0.5,0.0) [0.0|100.0] "pct" Vector__XXX
 SG_ HvBattCellNTCIdx : 31|6@0+ (1.0,0.0) [0.0|63.0] "" Vector__XXX
 SG_ HvBattCellNTCMaxResv1 : 24|9@0+ (0.5,-40.0) [-40.0|215.0] "" Vector__XXX
 SG_ HvBattCellNTCMaxResv2 : 103|9@0+ (0.5,-40.0) [-40.0|215.0] "" Vector__XXX
 SG_ HvBattCellNTCMinResv1 : 104|9@0+ (0.5,-40.0) [-40.0|215.0] "" Vector__XXX
 SG_ HvBattCellNTCMinResv2 : 127|9@0+ (0.5,-40.0) [-40.0|215.0] "" Vector__XXX
 SG_ HvbattChrgPlsCurLv1 : 134|1@0+ (1.0,0.0) [0.0|1.0] "" Vector__XXX
 SG_ HvbattChrgPlsCurLv2 : 133|1@0+ (1.0,0.0) [0.0|1.0] "" Vector__XXX
 SG_ HvbattChrgrPlsCurLv2Cnt : 47|8@0+ (1.0,0.0) [0.0|254.0] "" Vector__XXX
 SG_ HVBattDischargeSoCTargetReq : 55|16@0+ (0.05,0.0) [0.0|100.0] "" Vector__XXX
 SG_ HvBattLCMInfo1 : 151|16@0+ (1.0,0.0) [0.0|65534.0] "" Vector__XXX
 SG_ HvBattLCMInfo2 : 167|16@0+ (1.0,0.0) [0.0|65534.0] "" Vector__XXX
 SG_ HvBattLCMInfo3 : 183|32@0+ (1.0,0.0) [0.0|4294967294.0] "" Vector__XXX
 SG_ HvBattOverDchaCnt : 128|9@0+ (1.0,0.0) [0.0|510.0] "" Vector__XXX
 SG_ HvBattOverDchaFlg : 132|1@0+ (1,0) [0|1] "" Vector__XXX
 SG_ HvBattResRSMS : 71|16@0+ (0.01,0.0) [0.0|655.35] "mΩ" Vector__XXX
 SG_ HVBattRestTimeReq : 87|8@0+ (0.5,0.0) [0.0|127.5] "" Vector__XXX
 SG_ HvBattRutPheatgThermSts1 : 319|16@0+ (1.0,0.0) [0.0|65535.0] "" Vector__XXX
 SG_ HvBattRutPheatgThermSts2 : 335|16@0+ (1.0,0.0) [0.0|65535.0] "" Vector__XXX
 SG_ HvBattRutPheatgThermSts3 : 351|16@0+ (1.0,0.0) [0.0|65535.0] "" Vector__XXX
 SG_ HvBattRutPheatgThermSts4 : 367|16@0+ (1.0,0.0) [0.0|65535.0] "" Vector__XXX
 SG_ HvBattSohCalcInfo1 : 215|8@0+ (1.0,0.0) [0.0|255.0] "" Vector__XXX
 SG_ HvBattSohCalcInfo2 : 223|32@0+ (1.0,0.0) [0.0|4294967295.0] "" Vector__XXX
 SG_ HvBattSohCalcInfo3 : 255|32@0+ (1.0,0.0) [0.0|4294967295.0] "" Vector__XXX
 SG_ HvBattSOHRSMSCode : 95|8@0+ (1.0,0.0) [1.0|255.0] "" Vector__XXX
 SG_ HVFlybackPwrAllwd : 383|8@0+ (1.0,0.0) [0.0|255.0] "W" Vector__XXX
 SG_ PyroFuseMskReq : 287|16@0+ (1.0,0.0) [0.0|65535.0] "" Vector__XXX
 SG_ PyroFuseReq : 303|16@0+ (1.0,0.0) [0.0|65535.0] "" Vector__XXX

BO_ 1006 BMS_PTCANFD_0x3EE : 32 BMS
 SG_ HvBattMaxCellSOCPred : 199|8@0+ (1.0,0.0) [0.0|255.0] "pct" Vector__XXX
 SG_ HvBattMaxCellTempPred : 207|8@0+ (1.0,-40.0) [-40.0|215.0] "degC" Vector__XXX
 SG_ HvBattMaxCellVoltPred : 215|16@0+ (1.0,0.0) [0.0|65535.0] "mV" Vector__XXX
 SG_ HvBattMinCellSOCPred : 231|8@0+ (1.0,0.0) [0.0|255.0] "pct" Vector__XXX
 SG_ HvBattMinCellTempPred : 239|8@0+ (1.0,-40.0) [-40.0|215.0] "degC" Vector__XXX
 SG_ HvBattMinCellVoltPred : 247|16@0+ (1.0,0.0) [0.0|65535.0] "mV" Vector__XXX
 SG_ HvBattPackCodeX1 : 7|8@0+ (1.0,0.0) [0.0|127.0] "" Vector__XXX
 SG_ HvBattPackCodeX10 : 79|8@0+ (1.0,0.0) [0.0|127.0] "" Vector__XXX
 SG_ HvBattPackCodeX11 : 87|8@0+ (1.0,0.0) [0.0|127.0] "" Vector__XXX
 SG_ HvBattPackCodeX12 : 95|8@0+ (1.0,0.0) [0.0|127.0] "" Vector__XXX
 SG_ HvBattPackCodeX13 : 103|8@0+ (1.0,0.0) [0.0|127.0] "" Vector__XXX
 SG_ HvBattPackCodeX14 : 111|8@0+ (1.0,0.0) [0.0|127.0] "" Vector__XXX
 SG_ HvBattPackCodeX15 : 119|8@0+ (1.0,0.0) [0.0|127.0] "" Vector__XXX
 SG_ HvBattPackCodeX16 : 127|8@0+ (1.0,0.0) [0.0|127.0] "" Vector__XXX
 SG_ HvBattPackCodeX17 : 135|8@0+ (1.0,0.0) [0.0|127.0] "" Vector__XXX
 SG_ HvBattPackCodeX18 : 143|8@0+ (1.0,0.0) [0.0|127.0] "" Vector__XXX
 SG_ HvBattPackCodeX19 : 151|8@0+ (1.0,0.0) [0.0|127.0] "" Vector__XXX
 SG_ HvBattPackCodeX2 : 15|8@0+ (1.0,0.0) [0.0|127.0] "" Vector__XXX
 SG_ HvBattPackCodeX20 : 159|8@0+ (1.0,0.0) [0.0|127.0] "" Vector__XXX
 SG_ HvBattPackCodeX21 : 167|8@0+ (1.0,0.0) [0.0|127.0] "" Vector__XXX
 SG_ HvBattPackCodeX22 : 175|8@0+ (1.0,0.0) [0.0|127.0] "" Vector__XXX
 SG_ HvBattPackCodeX23 : 183|8@0+ (1.0,0.0) [0.0|127.0] "" Vector__XXX
 SG_ HvBattPackCodeX24 : 191|8@0+ (1.0,0.0) [0.0|127.0] "" Vector__XXX
 SG_ HvBattPackCodeX3 : 23|8@0+ (1.0,0.0) [0.0|127.0] "" Vector__XXX
 SG_ HvBattPackCodeX4 : 31|8@0+ (1.0,0.0) [0.0|127.0] "" Vector__XXX
 SG_ HvBattPackCodeX5 : 39|8@0+ (1.0,0.0) [0.0|127.0] "" Vector__XXX
 SG_ HvBattPackCodeX6 : 47|8@0+ (1.0,0.0) [0.0|127.0] "" Vector__XXX
 SG_ HvBattPackCodeX7 : 55|8@0+ (1.0,0.0) [0.0|127.0] "" Vector__XXX
 SG_ HvBattPackCodeX8 : 63|8@0+ (1.0,0.0) [0.0|127.0] "" Vector__XXX
 SG_ HvBattPackCodeX9 : 71|8@0+ (1.0,0.0) [0.0|127.0] "" Vector__XXX

BO_ 1010 BMS_PTCANFD_0x3F2 : 32 BMS
 SG_ BDUCooltFlowReq : 231|8@0+ (0.2,0.0) [0.0|50.0] "" Vector__XXX
 SG_ FlybackCtrSts : 199|8@0+ (1.0,0.0) [0.0|255.0] "" Vector__XXX
 SG_ HvBattCellBalActvt : 20|1@0+ (1,0) [0|1] "" Vector__XXX
 SG_ HvBattCellTAvg : 207|9@0+ (0.5,-40.0) [-40.0|215.0] "℃" Vector__XXX
 SG_ HvBattCellTMax : 175|9@0+ (0.5,-40.0) [-40.0|215.0] "℃" Vector__XXX
 SG_ HvBattCellTMaxResv : 239|9@0+ (0.5,-40.0) [-40.0|215.5] "℃" Vector__XXX
 SG_ HvBattCellTMin : 177|9@0+ (0.5,-40.0) [-40.0|215.0] "℃" Vector__XXX
 SG_ HvBattCellTMinResv : 240|9@0+ (0.5,-40.0) [-40.0|215.5] "℃" Vector__XXX
 SG_ HvBattCellTSigGrpChks : 159|8@0+ (1,0) [0|255] "" Vector__XXX
 SG_ HvBattCellTSigGrpCntr : 163|4@0+ (1,0) [0|15] "" Vector__XXX
 SG_ HvBattCooltFlowReq : 223|8@0+ (0.2,0.0) [0.0|50.0] "L/min" Vector__XXX
 SG_ HvBattFaultInfoFlag : 96|1@0+ (1,0) [0|1] "" Vector__XXX
 SG_ HvBattNTCIdx : 246|6@0+ (1,0) [0|63] "" Vector__XXX
 SG_ HvBattPackDesnMaxEngy : 143|11@0+ (0.1,0.0) [0.0|204.70000000000002] "" Vector__XXX
 SG_ HvBattSoH : 7|14@0+ (0.01,0.0) [0.0|100.0] "%" Vector__XXX
 SG_ HVBattTempRiskLvl : 19|4@0+ (1,0) [0|15] "" Vector__XXX
 SG_ HvBattTotChrgdEgyAh : 31|23@0+ (1.0,0.0) [0.0|8388607.0] "Ah" Vector__XXX
 SG_ HvBattTotChrgdEgyWh : 55|32@0+ (1.0,0.0) [0.0|4294967295.0] "Wh" Vector__XXX
 SG_ HvBattTotDchrgdEgyAh : 87|23@0+ (1.0,0.0) [0.0|8388607.0] "Ah" Vector__XXX
 SG_ HvBattTotDchrgdEgyWh : 111|32@0+ (1.0,0.0) [0.0|4294967295.0] "Wh" Vector__XXX

BO_ 1012 BMS_PTCANFD_0x3F4 : 64 BMS
 SG_ DCChrgnPortTNegTerminal : 183|8@0+ (1.0,-40.0) [-40.0|214.0] "℃" Vector__XXX
 SG_ DCChrgnPortTPosTerminal : 191|8@0+ (1.0,-40.0) [-40.0|214.0] "℃" Vector__XXX
 SG_ HvBattAvgShuntDriftCurr : 327|16@0+ (0.1,-3276.7) [-3276.7|3276.8] "A" Vector__XXX
 SG_ HvBattBMUVersion : 47|12@0+ (1.0,0.0) [0.0|949.0] "" Vector__XXX
 SG_ HvBattBSWVersion : 31|16@0+ (1.0,0.0) [0.0|949.0] "" Vector__XXX
 SG_ HvBattCellBBVltg3 : 226|11@0+ (0.001,-1.0) [-1.0|1.0470000000000002] "V" Vector__XXX
 SG_ HvBattCellQntyRSMS : 199|8@0+ (1.0,0.0) [1.0|255.0] "" Vector__XXX
 SG_ HvBattCMCVersion : 51|12@0+ (1.0,0.0) [0.0|949.0] "" Vector__XXX
 SG_ HvBattCrsChkRec : 71|8@0+ (1.0,0.0) [0.0|255.0] "" Vector__XXX
 SG_ HvBattExpVlvFluNTCTemp1 : 367|8@0+ (1.0,-40.0) [-40.0|215.0] "degC" Vector__XXX
 SG_ HvBattExpVlvFluNTCTemp2 : 375|8@0+ (1.0,-40.0) [-40.0|215.0] "degC" Vector__XXX
 SG_ HvBattExpVlvFluNTCTemp3 : 383|8@0+ (1.0,-40.0) [-40.0|215.0] "degC" Vector__XXX
 SG_ HvBattExpVlvFluNTCTemp4 : 391|8@0+ (1.0,-40.0) [-40.0|215.0] "degC" Vector__XXX
 SG_ HvBattFrqHiSocWarn : 175|2@0+ (1,0) [0|3] "" Vector__XXX
 SG_ HvBattHallDriftCurr : 159|16@0+ (0.1,-3276.8) [-3276.8|3276.7] "V" Vector__XXX
 SG_ HvBattMaxTProbIDRSMS : 207|7@0+ (1.0,0.0) [1.0|127.0] "" Vector__XXX
 SG_ HvBattMinTProbIDRSMS : 223|7@0+ (1.0,0.0) [1.0|127.0] "" Vector__XXX
 SG_ HvBattOverCurrentAs : 111|16@0+ (0.5,0.0) [0.0|32767.5] "As" Vector__XXX
 SG_ HvBattPackCurrPred : 127|16@0+ (1.0,-32768.0) [-32768.0|32767.0] "A" Vector__XXX
 SG_ HvBattPackQntyRSMS : 231|5@0+ (1.0,0.0) [0.0|31.0] "" Vector__XXX
 SG_ HvBattPackVoltPred : 143|16@0+ (1.0,0.0) [0.0|65535.0] "V" Vector__XXX
 SG_ HvBattPfcChkRec : 79|8@0+ (1.0,0.0) [0.0|255.0] "" Vector__XXX
 SG_ HvBattPfcFailRsn : 87|24@0+ (1.0,0.0) [0.0|262143.0] "" Vector__XXX
 SG_ HVBattRefcapVoltInfo : 343|8@0+ (1.0,0.0) [0.0|255.0] "" Vector__XXX
 SG_ HvBattShuntTemp : 351|9@0+ (0.5,-40.0) [-40.0|215.5] "℃" Vector__XXX
 SG_ HvBattSWVersion : 7|24@0+ (1.0,0.0) [0.0|9949999.0] "" Vector__XXX
 SG_ HvBattTPrbQntyRSMS : 215|7@0+ (1.0,0.0) [1.0|127.0] "" Vector__XXX
 SG_ HvFlybackACCWh : 247|16@0+ (1.0,0.0) [0.0|65535.0] "Wh" Vector__XXX
 SG_ HvFlybackAvgCur : 263|16@0+ (0.0001,-3.2767) [-3.2767|3.2768000000000006] "A" Vector__XXX
 SG_ HvFlybackAvgPwr : 279|16@0+ (0.1,-3276.7) [-3276.7|3276.8] "W" Vector__XXX
 SG_ HvFlybackColC : 295|32@0+ (0.01,0.0) [0.0|42949672.95] "Ah" Vector__XXX

BO_ 1016 BMS_PTCANFD_0x3F8 : 32 BMS
 SG_ HvBattTempRSMS17 : 7|9@0+ (0.5,-40.0) [-40.0|215.0] "℃" Vector__XXX
 SG_ HvBattTempRSMS18 : 23|9@0+ (0.5,-40.0) [-40.0|215.0] "℃" Vector__XXX
 SG_ HvBattTempRSMS19 : 39|9@0+ (0.5,-40.0) [-40.0|215.0] "℃" Vector__XXX
 SG_ HvBattTempRSMS20 : 55|9@0+ (0.5,-40.0) [-40.0|215.0] "℃" Vector__XXX
 SG_ HvBattTempRSMS21 : 71|9@0+ (0.5,-40.0) [-40.0|215.0] "℃" Vector__XXX
 SG_ HvBattTempRSMS22 : 87|9@0+ (0.5,-40.0) [-40.0|215.0] "℃" Vector__XXX
 SG_ HvBattTempRSMS23 : 103|9@0+ (0.5,-40.0) [-40.0|215.0] "℃" Vector__XXX
 SG_ HvBattTempRSMS24 : 119|9@0+ (0.5,-40.0) [-40.0|215.0] "℃" Vector__XXX
 SG_ HvBattTempRSMS25 : 135|9@0+ (0.5,-40.0) [-40.0|215.0] "℃" Vector__XXX
 SG_ HvBattTempRSMS26 : 151|9@0+ (0.5,-40.0) [-40.0|215.0] "℃" Vector__XXX
 SG_ HvBattTempRSMS27 : 167|9@0+ (0.5,-40.0) [-40.0|215.0] "℃" Vector__XXX
 SG_ HvBattTempRSMS28 : 183|9@0+ (0.5,-40.0) [-40.0|215.5] "℃" Vector__XXX
 SG_ HvBattTempRSMS29 : 199|9@0+ (0.5,-40.0) [-40.0|215.5] "℃" Vector__XXX
 SG_ HvBattTempRSMS30 : 215|9@0+ (0.5,-40.0) [-40.0|215.5] "℃" Vector__XXX
 SG_ HvBattTempRSMS31 : 231|9@0+ (0.5,-40.0) [-40.0|215.5] "℃" Vector__XXX
 SG_ HvBattTempRSMS32 : 247|9@0+ (0.5,-40.0) [-40.0|215.5] "℃" Vector__XXX

BO_ 1019 BMS_PTCANFD_0x3FB : 32 BMS
 SG_ HvBattTempRSMS33 : 7|9@0+ (0.5,-40.0) [-40.0|215.5] "℃" Vector__XXX
 SG_ HvBattTempRSMS34 : 23|9@0+ (0.5,-40.0) [-40.0|215.5] "℃" Vector__XXX
 SG_ HvBattTempRSMS35 : 39|9@0+ (0.5,-40.0) [-40.0|215.5] "℃" Vector__XXX
 SG_ HvBattTempRSMS36 : 55|9@0+ (0.5,-40.0) [-40.0|215.5] "℃" Vector__XXX
 SG_ HvBattTempRSMS37 : 71|9@0+ (0.5,-40.0) [-40.0|215.5] "℃" Vector__XXX
 SG_ HvBattTempRSMS38 : 87|9@0+ (0.5,-40.0) [-40.0|215.5] "℃" Vector__XXX
 SG_ HvBattTempRSMS39 : 103|9@0+ (0.5,-40.0) [-40.0|215.5] "℃" Vector__XXX
 SG_ HvBattTempRSMS40 : 119|9@0+ (0.5,-40.0) [-40.0|215.5] "℃" Vector__XXX
 SG_ HvBattTempRSMS41 : 135|9@0+ (0.5,-40.0) [-40.0|215.5] "℃" Vector__XXX
 SG_ HvBattTempRSMS42 : 151|9@0+ (0.5,-40.0) [-40.0|215.5] "℃" Vector__XXX
 SG_ HvBattTempRSMS43 : 167|9@0+ (0.5,-40.0) [-40.0|215.5] "℃" Vector__XXX
 SG_ HvBattTempRSMS44 : 183|9@0+ (0.5,-40.0) [-40.0|215.5] "℃" Vector__XXX
 SG_ HvBattTempRSMS45 : 199|9@0+ (0.5,-40.0) [-40.0|215.5] "℃" Vector__XXX
 SG_ HvBattTempRSMS46 : 215|9@0+ (0.5,-40.0) [-40.0|215.5] "℃" Vector__XXX
 SG_ HvBattTempRSMS47 : 231|9@0+ (0.5,-40.0) [-40.0|215.5] "℃" Vector__XXX
 SG_ HvBattTempRSMS48 : 247|9@0+ (0.5,-40.0) [-40.0|215.5] "℃" Vector__XXX

BO_ 1020 BMS_PTCANFD_0x3FC : 32 BMS
 SG_ HvBattTempRSMS49 : 7|9@0+ (0.5,-40.0) [-40.0|215.5] "℃" Vector__XXX
 SG_ HvBattTempRSMS50 : 23|9@0+ (0.5,-40.0) [-40.0|215.5] "℃" Vector__XXX
 SG_ HvBattTempRSMS51 : 39|9@0+ (0.5,-40.0) [-40.0|215.5] "℃" Vector__XXX
 SG_ HvBattTempRSMS52 : 55|9@0+ (0.5,-40.0) [-40.0|215.5] "℃" Vector__XXX
 SG_ HvBattTempRSMS53 : 71|9@0+ (0.5,-40.0) [-40.0|215.5] "℃" Vector__XXX
 SG_ HvBattTempRSMS54 : 87|9@0+ (0.5,-40.0) [-40.0|215.5] "℃" Vector__XXX
 SG_ HvBattTempRSMS55 : 103|9@0+ (0.5,-40.0) [-40.0|215.5] "℃" Vector__XXX
 SG_ HvBattTempRSMS56 : 119|9@0+ (0.5,-40.0) [-40.0|215.5] "℃" Vector__XXX
 SG_ HvBattTempRSMS57 : 135|9@0+ (0.5,-40.0) [-40.0|215.5] "℃" Vector__XXX
 SG_ HvBattTempRSMS58 : 151|9@0+ (0.5,-40.0) [-40.0|215.5] "℃" Vector__XXX
 SG_ HvBattTempRSMS59 : 167|9@0+ (0.5,-40.0) [-40.0|215.5] "℃" Vector__XXX
 SG_ HvBattTempRSMS60 : 183|9@0+ (0.5,-40.0) [-40.0|215.5] "℃" Vector__XXX
 SG_ HvBattTempRSMS61 : 199|9@0+ (0.5,-40.0) [-40.0|215.5] "℃" Vector__XXX
 SG_ HvBattTempRSMS62 : 215|9@0+ (0.5,-40.0) [-40.0|215.5] "℃" Vector__XXX
 SG_ HvBattTempRSMS63 : 231|9@0+ (0.5,-40.0) [-40.0|215.5] "℃" Vector__XXX
 SG_ HvBattTempRSMS64 : 247|9@0+ (0.5,-40.0) [-40.0|215.5] "℃" Vector__XXX

// Signal Comments
CM_ SG_ 305 BMSChrgrCurCurCp "2015+桩当前电流能力";
CM_ SG_ 305 HvBattAvgCur "HV battery average current  Discharging battery  positive  charging battery  negative .";
CM_ SG_ 305 HvBattChrgnModSts "HV battery charging mode status. 表示可以启动对应充放电流程";
CM_ SG_ 305 HvBattDCPortU "High voltage battery DC port voltage
高压电池直流充电口电压";
CM_ SG_ 305 HvBattHVIL1Sts "HV battery inter lock loop 1 status.";
CM_ SG_ 305 HvBattHVIL2Sts "HV battery inter lock loop 2 status.";
CM_ SG_ 305 HvBattServModSts "Hv Battery Service Mode Status";
CM_ SG_ 449 BMSAuthenticationSts "2015+桩鉴权状态反馈";
CM_ SG_ 449 BMSBCPErrSts "BMS发送BCP后报错状态";
CM_ SG_ 449 BMSBHMErrSts "BMS发送BHM后检测到桩的错误";
CM_ SG_ 449 BMSChrgnAwakeSts "2015+车桩唤醒状态";
CM_ SG_ 449 BMSChrgnPauseSts "2015+充电暂停状态";
CM_ SG_ 449 BMSChrgnRepeatReq "2015+车桩重连请求";
CM_ SG_ 449 DCChrgnCntctSts "DC charging contactor status";
CM_ SG_ 449 DCChrgnNegCntctSts "DC charging negative contactor status";
CM_ SG_ 449 DCChrgnPosCntctSts "DC charging positive contactor status";
CM_ SG_ 449 DCPileType "直流充电桩类型";
CM_ SG_ 449 HvBattAvgCurBackUp "HV battery average current(BackUp)
整包均值电流(备用)";
CM_ SG_ 449 HvBattCoolgLvlReq "HV battery cooling level request.";
CM_ SG_ 449 HvBattFlgChrgnSoCLimFinish "HV battery Set SOC charging limit finish flag";
CM_ SG_ 449 HvBattFlgDchrgnSoCLimFinish "HV battery Set SOC discharge limit finish flag";
CM_ SG_ 449 HvBattFlgFullChrgnFinish "HV battery full Charging of HV battery is finished or not flag";
CM_ SG_ 449 HvBattHeatCurLim "Hv battery pulse heating current limit";
CM_ SG_ 449 HvBattHeatgLvlReq "HV battery heating level request.";
CM_ SG_ 449 HvBattLowTSocRedn "HV battery low Temperature soc Reduction
低温SOC显示";
CM_ SG_ 449 HvBattNormTDispSoc "HV battery normal temperature SOC display
常温显示SOC";
CM_ SG_ 449 HvBattSoCAct "HV battery SoC actual";
CM_ SG_ 449 HvBattSoCDisp "HV battery State Of Energy for HMI Display / 高压电池剩余可用能量百分比状态信息用于HMI人机交互显示";
CM_ SG_ 449 HvBattSoCDispForHiResl "HV battery SoC Display for High Resolution
高精度显示SOC";
CM_ SG_ 449 HVSampChipOverCurrFlg "Overcurrent flag sent by HV sampling chip";
CM_ SG_ 449 PrechargnPosCntctSts "Precharging positive contact status";
CM_ SG_ 626 BMSFaultInfoFlag "BMS Fault Information Flag";
CM_ SG_ 626 FlybackFaultInf "Flyback Fault Information
Flyback故障信息";
CM_ SG_ 626 FlybackOutput4Volt "Flyback output 4 voltage 
Flyback输出4的电压";
CM_ SG_ 626 FlybackSupply2OcCtr "Flyback Supply2 Overcurrent Counter 
Flyback 供电2的过载计数值";
CM_ SG_ 626 HvBattActvThermRemd "电池主动冷却/保温请求文言提示";
CM_ SG_ 626 HvBattDchrgnEgyDisp "HV battery maximum display discharging  energy to map the SOC display in the 25C";
CM_ SG_ 626 HvBattDchrgnEgyMax "HV battery maximum discharging energy  for range calculation display  指当前SoC放到屏显SoC=0%的可用电量 用于车辆续航剩余里程计算";
CM_ SG_ 626 HvBattFlgLowSoc "低电量标志位";
CM_ SG_ 626 HvBattFlgPfmn "HV battery performance assurance event flag HV battery performance assurance event happened or not";
CM_ SG_ 626 HvBattFlgSfty "HV battery safety flag HV battery safety happened or not";
CM_ SG_ 626 HvBattFlgThermRunAway "HV battery thermal runaway flag HV battery thermal run away happened or not";
CM_ SG_ 626 HvBattHlthMngtFcnSts "电池健康管家功能开关状态
battery healthy management function switch status";
CM_ SG_ 626 HvBattHWFailReq "BMS有安全风险的失效提示";
CM_ SG_ 626 HvBattLeakFltIndcn "Indication for the battery pack coolant liquid leakage fault status";
CM_ SG_ 626 HvBattLowSocDrvInhb "低SOC退档请求";
CM_ SG_ 626 HvBattRlyHldSts "继电器保持功能置位情况";
CM_ SG_ 626 HvBattRmngChrgnTi "HV battery remaining charging time based on current charging current.";
CM_ SG_ 626 HvBattRmngDchrgnTi "HV battery The remaining discharging time based on current discharging current V2X .";
CM_ SG_ 626 HvBattSoCLock "HV battery SoC forLock due to Low Temperature";
CM_ SG_ 626 HvbattSrvReq "High voltage battery system service request";
CM_ SG_ 626 HvBattSupChrgnResp "Super Charge Response";
CM_ SG_ 626 HvBattTempLowFault "BMS温度低于一定值的故障状态";
CM_ SG_ 627 HvBattCellUDifFltRSMS "HV battery cell voltage difference excessive fault information";
CM_ SG_ 627 HvBattCellUOverFltRSMS "HV battery cell voltage over voltage fault information";
CM_ SG_ 627 HvBattCellUUnderFltRSMS "HV battery cell voltage under voltage fault information";
CM_ SG_ 627 HvBattChrgnEmcyOffReq "Charge contact open request flag
充电继电器立刻断开的单一信号标志位";
CM_ SG_ 627 HvBattChrgnrComFltRSMS "Hv Battery charging communication fault information";
CM_ SG_ 627 HvBattColdWarn "HV battery cold warn";
CM_ SG_ 627 HvBattFRSReact "Functional safety fault response status
功能安全故障响应状态";
CM_ SG_ 627 HvBattFusaPulseCurrMon "Functional safety pulse current surge event monitoring
功能安全脉冲电流冲击事件监控";
CM_ SG_ 627 HvBattMaxUCellIDRSMS "The Number of maximum Voltage Cell in HV Battery";
CM_ SG_ 627 HvBattMILReq "BMS MIL request
BMS请求MIL灯点亮";
CM_ SG_ 627 HvBattMinUCellIDRSMS "The Number of minimum Voltage Cell in HV Battery";
CM_ SG_ 627 HvBattOperationReq "Hv battery operation request 电池操作用户建议信号 包括均衡请求 满充请求 具体充电方法 静置时间要求等";
CM_ SG_ 627 HvBattOverChrgnFltRSMS "HV battery over charged fault information";
CM_ SG_ 627 HvBattOverCurFltRSMS "Hv Battery over current fault information";
CM_ SG_ 627 HvBattPackUOverFltRSMS "HV battery pack voltage over voltage fault information";
CM_ SG_ 627 HvBattPackUUnderFltRSMS "HV battery pack voltage under voltage fault information";
CM_ SG_ 627 HvBattPwrDoMoSceRSMS "HV battery Power-down Monitoring Scenario for 32960 (type of HV battery Power-down Monitoring Scenario)
32960法规高压电池断电场景的监控类型
";
CM_ SG_ 627 HvBattRutPheatgChrgnSts1 "在途加热功能,设置目标充电目标SOC对应充电内部状态1";
CM_ SG_ 627 HvBattRutPheatgChrgnSts2 "在途加热功能,设置目标充电目标SOC对应充电内部状态2";
CM_ SG_ 627 HvBattRutPheatgChrgnSts3 "在途加热功能,设置目标充电目标SOC对应充电内部状态3";
CM_ SG_ 627 HvBattRutPheatgChrgnSts4 "在途加热功能,设置目标充电目标SOC对应充电内部状态4";
CM_ SG_ 627 HvBattSocHiFltRSMS "HV battery SOC too high fault information";
CM_ SG_ 627 HvBattSocHopFltRSMS "HV battery SOC hop fault information";
CM_ SG_ 627 HvBattSocLoFltRSMS "HV battery SOC too low fault information";
CM_ SG_ 627 HvBattTDifFltRSMS "HV battery temperature difference excessive fault information";
CM_ SG_ 627 HvBattTotFltQntyRSMS "Quantity of faults in HV Battery";
CM_ SG_ 627 HvBattTOverFltRSMS "HV battery temperature over fault information";
CM_ SG_ 627 MainNegCntctFlt "Main Negative contactor fault";
CM_ SG_ 627 MainPosCntctFlt "Main Postivie contactor fault";
CM_ SG_ 629 DCChrgrCurCp "DC charger current capacity.  negative";
CM_ SG_ 629 DCChrgrUCp "DC charger voltage capacity.";
CM_ SG_ 629 FlybackOutput1Volt "Flyback output 1 voltage
Flyback输出1的电压";
CM_ SG_ 629 FlybackOutput2Volt "Flyback output 2 voltage
Flyback输出2的电压";
CM_ SG_ 629 FlybackOutput3Volt "Flyback output 3 voltage
Flyback输出3的电压";
CM_ SG_ 629 FlybackSupply1OcCtr "Flyback Overcurrent Counter
Flyback 过载计数值";
CM_ SG_ 629 HvBattCurMaxLimDCChrgn "HV battery Maximum current allowed for battery DC charging. negative";
CM_ SG_ 629 HvBattUMaxLimDCChrgn "HV battery Maximum voltage allowed for battery DC charging.";
CM_ SG_ 630 BuckOutpUReq "Buck output voltage request";
CM_ SG_ 630 DCChrgnProtocolVers "DC Charging Protocol Version";
CM_ SG_ 630 DCChrgrActCur "DC charger actual current during charging. negative";
CM_ SG_ 630 DCChrgrActU "DC charger actual voltage during charging.";
CM_ SG_ 630 DCChrgrTypInfo "DC Charger Type information  i.e. DC Charging book status";
CM_ SG_ 630 HvBatt2CCUSleepCmd "HvBatt control CCU sleep command
电池BMU控制CCU休眠指令";
CM_ SG_ 630 HvBattBkdHeatgTi "HV battery booked  heating time";
CM_ SG_ 630 HvBattBkdPredChrgnTi "HV battery booked charging predicted time based on current charging current.";
CM_ SG_ 630 HvBattChrgdEgyThisChrgnCyc "HV battery charged energy this charging cycle AC/DC/Wireless charging  used for added range km  calculation by this charging cycle .";
CM_ SG_ 630 HvBattCurMaxLimACChrgn "HV battery Maximum current allowed for battery AC charging.  negative";
CM_ SG_ 630 HvBattDCChrgnfltTyp "DC Charging fault Type";
CM_ SG_ 630 HvBattDCChrgnSts "HV Battery DC charging status.";
CM_ SG_ 630 HvBattDCChrgnTyp "DC charge type  Direct charge or Boost charge  .";
CM_ SG_ 630 HvBattKeepWrmgTi "HV battery keep warming time after charging finished";
CM_ SG_ 630 HvBattOCCurMaxAuxFastRec "HV battery max current of aux Fast ADC when OC happen
OC过流发生时辅Fast ADC的极值电流值";
CM_ SG_ 630 HvBattOCCurMaxAuxRec "HV battery max current of aux ADC when OC happen
OC过流发生时辅ADC的极值电流值";
CM_ SG_ 630 HvBattOCCurMaxMainFastRec "HV battery max current of main Fast ADC when OC happen
OC过流发生时主Fast ADC的极值电流值";
CM_ SG_ 630 HvBattOCCurMaxMainRec "HV battery max current of main ADC when OC happen
OC过流发生时主ADC的极值电流值";
CM_ SG_ 630 HvBattPreHeatgTi "High Voltage Battery Remaining heating time  电池先导加热倒计时";
CM_ SG_ 630 HvBattSyncUCellMax "HV Battery synchronized maximum cell voltage";
CM_ SG_ 630 HvBattSyncUCellMin "HV Battery synchronized minimum cell voltage";
CM_ SG_ 630 HvBattUCellAvg "HV Battery average cell voltage.";
CM_ SG_ 630 HvBattUCellMax "HV Battery maximum cell voltage";
CM_ SG_ 630 HvBattUCellMin "HV battery minimum cell voltage";
CM_ SG_ 630 HvBattUCellSyncCur "HV Battery Cell Voltage synchronized current";
CM_ SG_ 630 HvBattUMaxLimACChrgn "HV battery Maximum voltage allowed for battery AC charging.";
CM_ SG_ 632 HvBattCorsCur "电流传感器2电流";
CM_ SG_ 632 HvBattFltNr1 "Fault Number1";
CM_ SG_ 632 HvBattFltNr2 "Fault Number2";
CM_ SG_ 632 HvBattFltNr3 "Fault Number3";
CM_ SG_ 632 HvBattFltNr4 "Fault Number4";
CM_ SG_ 632 HvBattFltNr5 "Fault Number5";
CM_ SG_ 632 HvBattFltNrIdx "Fault Number Index";
CM_ SG_ 632 HvBattFltTotNr "Fault Total Number";
CM_ SG_ 632 HvBatThrRson "热失控发生原因";
CM_ SG_ 632 HvBattSopMdlLongTiChrgCurr "模型计算长时充电电流";
CM_ SG_ 632 HvBattSopMdlLongTiDchaCurr "模型计算长时放电电流";
CM_ SG_ 632 HvBattSopMdlShoTiChrgCurr "Driving: dynamic recharge current limit；Charging: basic value for overcurrent diagnosis。
行车：动态回充电流限制；充电：过流诊断的基础值";
CM_ SG_ 632 HvBattSopMdlShoTiDchaCurr "模型计算短时放电电流";
CM_ SG_ 632 HvBattUkl30C "KL30C电压";
CM_ SG_ 632 HvBattV2VSts "V2V状态";
CM_ SG_ 633 HvBattCellURSMS1 "CellU RSMS Signal Group  Detail voltage of cells in current frame";
CM_ SG_ 633 HvBattCellURSMS10 "CellU RSMS Signal Group  Detail voltage of cells in current frame";
CM_ SG_ 633 HvBattCellURSMS11 "CellU RSMS Signal Group  Detail voltage of cells in current frame";
CM_ SG_ 633 HvBattCellURSMS12 "CellU RSMS Signal Group  Detail voltage of cells in current frame";
CM_ SG_ 633 HvBattCellURSMS13 "CellU RSMS Signal Group  Detail voltage of cells in current frame";
CM_ SG_ 633 HvBattCellURSMS14 "CellU RSMS Signal Group  Detail voltage of cells in current frame";
CM_ SG_ 633 HvBattCellURSMS15 "CellU RSMS Signal Group  Detail voltage of cells in current frame";
CM_ SG_ 633 HvBattCellURSMS16 "CellU RSMS Signal Group  Detail voltage of cells in HV battery";
CM_ SG_ 633 HvBattCellURSMS2 "CellU RSMS Signal Group  Detail voltage of cells in current frame";
CM_ SG_ 633 HvBattCellURSMS3 "CellU RSMS Signal Group  Detail voltage of cells in current frame";
CM_ SG_ 633 HvBattCellURSMS4 "CellU RSMS Signal Group  Detail voltage of cells in current frame";
CM_ SG_ 633 HvBattCellURSMS5 "CellU RSMS Signal Group  Detail voltage of cells in current frame";
CM_ SG_ 633 HvBattCellURSMS6 "CellU RSMS Signal Group  Detail voltage of cells in current frame";
CM_ SG_ 633 HvBattCellURSMS7 "CellU RSMS Signal Group  Detail voltage of cells in current frame";
CM_ SG_ 633 HvBattCellURSMS8 "CellU RSMS Signal Group  Detail voltage of cells in current frame";
CM_ SG_ 633 HvBattCellURSMS9 "CellU RSMS Signal Group  Detail voltage of cells in current frame";
CM_ SG_ 634 HvBattCellURSMS17 "CellU RSMS Signal Group  Detail voltage of cells in HV battery";
CM_ SG_ 634 HvBattCellURSMS18 "CellU RSMS Signal Group  Detail voltage of cells in HV battery";
CM_ SG_ 634 HvBattCellURSMS19 "CellU RSMS Signal Group  Detail voltage of cells in HV battery";
CM_ SG_ 634 HvBattCellURSMS20 "CellU RSMS Signal Group  Detail voltage of cells in HV battery";
CM_ SG_ 634 HvBattCellURSMS21 "CellU RSMS Signal Group  Detail voltage of cells in HV battery";
CM_ SG_ 634 HvBattCellURSMS22 "CellU RSMS Signal Group  Detail voltage of cells in HV battery";
CM_ SG_ 634 HvBattCellURSMS23 "CellU RSMS Signal Group  Detail voltage of cells in HV battery";
CM_ SG_ 634 HvBattCellURSMS24 "CellU RSMS Signal Group  Detail voltage of cells in HV battery";
CM_ SG_ 634 HvBattCellURSMS25 "CellU RSMS Signal Group  Detail voltage of cells in HV battery";
CM_ SG_ 634 HvBattCellURSMS26 "CellU RSMS Signal Group  Detail voltage of cells in HV battery";
CM_ SG_ 634 HvBattCellURSMS27 "CellU RSMS Signal Group  Detail voltage of cells in HV battery";
CM_ SG_ 634 HvBattCellURSMS28 "CellU RSMS Signal Group  Detail voltage of cells in HV battery";
CM_ SG_ 634 HvBattCellURSMS29 "CellU RSMS Signal Group  Detail voltage of cells in HV battery";
CM_ SG_ 634 HvBattCellURSMS30 "CellU RSMS Signal Group  Detail voltage of cells in HV battery";
CM_ SG_ 634 HvBattCellURSMS31 "CellU RSMS Signal Group  Detail voltage of cells in HV battery";
CM_ SG_ 634 HvBattCellURSMS32 "CellU RSMS Signal Group  Detail voltage of cells in HV battery";
CM_ SG_ 635 HvBattCellURSMS33 "CellU RSMS Signal Group  Detail voltage of cells in HV battery";
CM_ SG_ 635 HvBattCellURSMS34 "CellU RSMS Signal Group  Detail voltage of cells in HV battery";
CM_ SG_ 635 HvBattCellURSMS35 "CellU RSMS Signal Group  Detail voltage of cells in HV battery";
CM_ SG_ 635 HvBattCellURSMS36 "CellU RSMS Signal Group  Detail voltage of cells in HV battery";
CM_ SG_ 635 HvBattCellURSMS37 "CellU RSMS Signal Group  Detail voltage of cells in HV battery";
CM_ SG_ 635 HvBattCellURSMS38 "CellU RSMS Signal Group  Detail voltage of cells in HV battery";
CM_ SG_ 635 HvBattCellURSMS39 "CellU RSMS Signal Group  Detail voltage of cells in HV battery";
CM_ SG_ 635 HvBattCellURSMS40 "CellU RSMS Signal Group  Detail voltage of cells in HV battery";
CM_ SG_ 635 HvBattCellURSMS41 "CellU RSMS Signal Group  Detail voltage of cells in HV battery";
CM_ SG_ 635 HvBattCellURSMS42 "CellU RSMS Signal Group  Detail voltage of cells in HV battery";
CM_ SG_ 635 HvBattCellURSMS43 "CellU RSMS Signal Group  Detail voltage of cells in HV battery";
CM_ SG_ 635 HvBattCellURSMS44 "CellU RSMS Signal Group  Detail voltage of cells in HV battery";
CM_ SG_ 635 HvBattCellURSMS45 "CellU RSMS Signal Group  Detail voltage of cells in HV battery";
CM_ SG_ 635 HvBattCellURSMS46 "CellU RSMS Signal Group  Detail voltage of cells in HV battery";
CM_ SG_ 635 HvBattCellURSMS47 "CellU RSMS Signal Group  Detail voltage of cells in HV battery";
CM_ SG_ 635 HvBattCellURSMS48 "CellU RSMS Signal Group  Detail voltage of cells in HV battery";
CM_ SG_ 636 HvBattCellURSMS49 "CellU RSMS Signal Group  Detail voltage of cells in HV battery";
CM_ SG_ 636 HvBattCellURSMS50 "CellU RSMS Signal Group  Detail voltage of cells in HV battery";
CM_ SG_ 636 HvBattCellURSMS51 "CellU RSMS Signal Group  Detail voltage of cells in HV battery";
CM_ SG_ 636 HvBattCellURSMS52 "CellU RSMS Signal Group  Detail voltage of cells in HV battery";
CM_ SG_ 636 HvBattCellURSMS53 "CellU RSMS Signal Group  Detail voltage of cells in HV battery";
CM_ SG_ 636 HvBattCellURSMS54 "CellU RSMS Signal Group  Detail voltage of cells in HV battery";
CM_ SG_ 636 HvBattCellURSMS55 "CellU RSMS Signal Group  Detail voltage of cells in HV battery";
CM_ SG_ 636 HvBattCellURSMS56 "CellU RSMS Signal Group  Detail voltage of cells in HV battery";
CM_ SG_ 636 HvBattCellURSMS57 "CellU RSMS Signal Group  Detail voltage of cells in HV battery";
CM_ SG_ 636 HvBattCellURSMS58 "CellU RSMS Signal Group  Detail voltage of cells in HV battery";
CM_ SG_ 636 HvBattCellURSMS59 "CellU RSMS Signal Group  Detail voltage of cells in HV battery";
CM_ SG_ 636 HvBattCellURSMS60 "CellU RSMS Signal Group  Detail voltage of cells in HV battery";
CM_ SG_ 636 HvBattCellURSMS61 "CellU RSMS Signal Group  Detail voltage of cells in HV battery";
CM_ SG_ 636 HvBattCellURSMS62 "CellU RSMS Signal Group  Detail voltage of cells in HV battery";
CM_ SG_ 636 HvBattCellURSMS63 "CellU RSMS Signal Group  Detail voltage of cells in HV battery";
CM_ SG_ 636 HvBattCellURSMS64 "CellU RSMS Signal Group  Detail voltage of cells in HV battery";
CM_ SG_ 637 HvBattCellURSMS65 "CellU RSMS Signal Group  Detail voltage of cells in HV battery";
CM_ SG_ 637 HvBattCellURSMS66 "CellU RSMS Signal Group  Detail voltage of cells in HV battery";
CM_ SG_ 637 HvBattCellURSMS67 "CellU RSMS Signal Group  Detail voltage of cells in HV battery";
CM_ SG_ 637 HvBattCellURSMS68 "CellU RSMS Signal Group  Detail voltage of cells in HV battery";
CM_ SG_ 637 HvBattCellURSMS69 "CellU RSMS Signal Group  Detail voltage of cells in HV battery";
CM_ SG_ 637 HvBattCellURSMS70 "CellU RSMS Signal Group  Detail voltage of cells in HV battery";
CM_ SG_ 637 HvBattCellURSMS71 "CellU RSMS Signal Group  Detail voltage of cells in HV battery";
CM_ SG_ 637 HvBattCellURSMS72 "CellU RSMS Signal Group  Detail voltage of cells in HV battery";
CM_ SG_ 637 HvBattCellURSMS73 "CellU RSMS Signal Group  Detail voltage of cells in HV battery";
CM_ SG_ 637 HvBattCellURSMS74 "CellU RSMS Signal Group  Detail voltage of cells in HV battery";
CM_ SG_ 637 HvBattCellURSMS75 "CellU RSMS Signal Group  Detail voltage of cells in HV battery";
CM_ SG_ 637 HvBattCellURSMS76 "CellU RSMS Signal Group  Detail voltage of cells in HV battery";
CM_ SG_ 637 HvBattCellURSMS77 "CellU RSMS Signal Group  Detail voltage of cells in HV battery";
CM_ SG_ 637 HvBattCellURSMS78 "CellU RSMS Signal Group  Detail voltage of cells in HV battery";
CM_ SG_ 637 HvBattCellURSMS79 "CellU RSMS Signal Group  Detail voltage of cells in HV battery";
CM_ SG_ 637 HvBattCellURSMS80 "CellU RSMS Signal Group  Detail voltage of cells in HV battery";
CM_ SG_ 638 HvBattCellURSMS81 "CellU RSMS Signal Group  Detail voltage of cells in HV battery";
CM_ SG_ 638 HvBattCellURSMS82 "CellU RSMS Signal Group  Detail voltage of cells in HV battery";
CM_ SG_ 638 HvBattCellURSMS83 "CellU RSMS Signal Group  Detail voltage of cells in HV battery";
CM_ SG_ 638 HvBattCellURSMS84 "CellU RSMS Signal Group  Detail voltage of cells in HV battery";
CM_ SG_ 638 HvBattCellURSMS85 "CellU RSMS Signal Group  Detail voltage of cells in HV battery";
CM_ SG_ 638 HvBattCellURSMS86 "CellU RSMS Signal Group  Detail voltage of cells in HV battery";
CM_ SG_ 638 HvBattCellURSMS87 "CellU RSMS Signal Group  Detail voltage of cells in HV battery";
CM_ SG_ 638 HvBattCellURSMS88 "CellU RSMS Signal Group  Detail voltage of cells in HV battery";
CM_ SG_ 638 HvBattCellURSMS89 "CellU RSMS Signal Group  Detail voltage of cells in HV battery";
CM_ SG_ 638 HvBattCellURSMS90 "CellU RSMS Signal Group  Detail voltage of cells in HV battery";
CM_ SG_ 638 HvBattCellURSMS91 "CellU RSMS Signal Group  Detail voltage of cells in HV battery";
CM_ SG_ 638 HvBattCellURSMS92 "CellU RSMS Signal Group  Detail voltage of cells in HV battery";
CM_ SG_ 638 HvBattCellURSMS93 "CellU RSMS Signal Group  Detail voltage of cells in HV battery";
CM_ SG_ 638 HvBattCellURSMS94 "CellU RSMS Signal Group  Detail voltage of cells in HV battery";
CM_ SG_ 638 HvBattCellURSMS95 "CellU RSMS Signal Group  Detail voltage of cells in HV battery";
CM_ SG_ 638 HvBattCellURSMS96 "CellU RSMS Signal Group  Detail voltage of cells in HV battery";
CM_ SG_ 639 HvBattCellURSMS100 "CellU RSMS Signal Group  Detail voltage of cells in HV battery";
CM_ SG_ 639 HvBattCellURSMS101 "CellU RSMS Signal Group  Detail voltage of cells in HV battery";
CM_ SG_ 639 HvBattCellURSMS102 "CellU RSMS Signal Group  Detail voltage of cells in HV battery";
CM_ SG_ 639 HvBattCellURSMS103 "CellU RSMS Signal Group  Detail voltage of cells in HV battery";
CM_ SG_ 639 HvBattCellURSMS104 "CellU RSMS Signal Group  Detail voltage of cells in HV battery";
CM_ SG_ 639 HvBattCellURSMS105 "CellU RSMS Signal Group  Detail voltage of cells in HV battery";
CM_ SG_ 639 HvBattCellURSMS106 "CellU RSMS Signal Group  Detail voltage of cells in HV battery";
CM_ SG_ 639 HvBattCellURSMS107 "CellU RSMS Signal Group  Detail voltage of cells in HV battery";
CM_ SG_ 639 HvBattCellURSMS108 "CellU RSMS Signal Group  Detail voltage of cells in HV battery";
CM_ SG_ 639 HvBattCellURSMS109 "CellU RSMS Signal Group  Detail voltage of cells in HV battery";
CM_ SG_ 639 HvBattCellURSMS110 "CellU RSMS Signal Group  Detail voltage of cells in HV battery";
CM_ SG_ 639 HvBattCellURSMS111 "CellU RSMS Signal Group  Detail voltage of cells in HV battery";
CM_ SG_ 639 HvBattCellURSMS112 "CellU RSMS Signal Group  Detail voltage of cells in HV battery";
CM_ SG_ 639 HvBattCellURSMS97 "CellU RSMS Signal Group  Detail voltage of cells in HV battery";
CM_ SG_ 639 HvBattCellURSMS98 "CellU RSMS Signal Group  Detail voltage of cells in HV battery";
CM_ SG_ 639 HvBattCellURSMS99 "CellU RSMS Signal Group  Detail voltage of cells in HV battery";
CM_ SG_ 642 BMUFuSaFltRct "BMU fault reaction triggered by function safety SW component";
CM_ SG_ 642 CellOverVoltFatalFaultNum "Occurrence number of Temporary Cell Over Voltage Fatal Fault";
CM_ SG_ 642 CellUnderVoltFatalFaultNum "Occurrence number of Temporary Cell Under Voltage Fatal Fault";
CM_ SG_ 642 GaCMSAfeDieTempOTTestFail "Temporary AFE die Over Temperature error";
CM_ SG_ 642 GaCTMModlTempSampElecFault "Temporary cell temperature electric error";
CM_ SG_ 642 GaCTMModlTempSamplingOoRSts "Temporary cell temperature out of range error";
CM_ SG_ 642 GeACCChargeOvercurrentL1Fault "BMS Fault information flag";
CM_ SG_ 642 GeACCChargeOvercurrentL2Fault "BMS Fault information flag";
CM_ SG_ 642 GeACCChargeOverCurrentL3Fault "AC充电过流3级故障";
CM_ SG_ 642 GeACCChargeOverCurrentL4Fault "AC充电过流4级故障";
CM_ SG_ 642 GeACCChargeOverCurrentL5Fault "AC充电过流5级故障";
CM_ SG_ 642 GeBCSOverCurrentDeviationFault "Temporary over current deviation fault";
CM_ SG_ 642 GeBCVVdncSmpCircAbnFault "DC负继电器后端电压  高压采样回路异常 V5";
CM_ SG_ 642 GeBCVVdpcSmpCircAbnFault "DC正继电器后端电压  高压采样回路异常 V3";
CM_ SG_ 642 GeBCVVmncSmpCircAbnFault "主负继电器后端电压  高压采样回路异常 V4";
CM_ SG_ 642 GeBCVVmpcSmpCircAbnFault "主正继电器后端电压  高压采样回路异常 V2";
CM_ SG_ 642 GeDCCChargeOvercurrentL1Fault "BMS Fault information flag";
CM_ SG_ 642 GeDCCChargeOvercurrentL2Fault "BMS Fault information flag";
CM_ SG_ 642 GeDCCChargeOverCurrentL3Fault "DC充电过流3级故障";
CM_ SG_ 642 GeDCCChargeOverCurrentL4Fault "DC充电过流4级故障";
CM_ SG_ 642 GeDCCChargeOverCurrentL5Fault "DC充电过流5级故障";
CM_ SG_ 642 ModlOverTempFatalFaultNum "Occurrence number of Temporary Cell Over Temperature Fatal Fault";
CM_ SG_ 645 HvBattAFECommSt "AFE Communication status";
CM_ SG_ 645 HvBattUCellEigValue1 "电芯电压特征值1";
CM_ SG_ 645 HvBattUCellEigValue2 "电芯电压特征值2";
CM_ SG_ 646 BMSBCLCurReq "Hv battery BCL Current requst
BMS发送BCL电流请求";
CM_ SG_ 646 BMSBCLVolReq "Hv battery BCL Voltage requst
BMS发送的BCL电压请求";
CM_ SG_ 646 BMSBCPFxCurU "BMS BCP Battery Currrnt Voltage";
CM_ SG_ 646 BMSBCPFxMaxU "BMS BCP Battery Max Voltage";
CM_ SG_ 646 BMSBHMFxU "BMS BHM Voltage";
CM_ SG_ 646 BMSCHMRxSts "HV Battery CHM receive states
BMS接收CHM的状态";
CM_ SG_ 646 BMSCMLRxSts "HV Battery CML receive states
BMS接收CML的状态";
CM_ SG_ 646 BMSCRMARxSts "HV Battery CRM=AA receive states
BMS接收CRM=AA的状态";
CM_ SG_ 646 BMSCRMORxSts "HV Battery CRM=00 receive states
BMS接收CRM=OO的状态";
CM_ SG_ 646 BMSCROARxSts "HV Battery CRO=AA receive states
BMS接收CRO=AA的状态";
CM_ SG_ 646 BMSCROORxSts "HV Battery CRO=00 receive states
BMS接收CRO=00的状态";
CM_ SG_ 646 DCChrgnNegCntctFlt "DC charging Negative contactor fault";
CM_ SG_ 646 DCChrgnPosCntctFlt "DC charging Postivie contactor fault";
CM_ SG_ 646 DCChrgrCc1ConnectnSts "DC charger CC1  connection status.";
CM_ SG_ 646 DchaByChrgrBattallwFlg "用桩能量方案在电池满充后,电池是否允许进入充电,只在浮充标志位置位后才有置位逻辑";
CM_ SG_ 646 HvBattChrgnDeratForT "电池温度过高或过低引起充电功率降低信息";
CM_ SG_ 646 HvBattCmptFaultIndcn "BMS故障文言提示信息";
CM_ SG_ 646 HvBattInsulChkProgrs "The checking status for current insulation checking location
定位具体正在检测的绝缘阻值路径";
CM_ SG_ 646 HvBattInsulChkSts "HV battery insulation check status.";
CM_ SG_ 646 HvBattInsulRN "HV battery negative electrode insulation resistance.";
CM_ SG_ 646 HvBattInsulRP "HV battery positive electrode insulation resistance.";
CM_ SG_ 646 HvBusInsulRN "HV bus negative electrode insulation resistance.";
CM_ SG_ 646 HvBusInsulRP "HV bus positive electrode insulation resistance.";
CM_ SG_ 646 PrechargnPosCntctFlt "Precharge Postivie contactor fault";
CM_ SG_ 647 HvBattCellURSMS113 "CellU RSMS Signal Group  Detail voltage of cells in HV battery";
CM_ SG_ 647 HvBattCellURSMS114 "CellU RSMS Signal Group  Detail voltage of cells in HV battery";
CM_ SG_ 647 HvBattCellURSMS115 "CellU RSMS Signal Group  Detail voltage of cells in HV battery";
CM_ SG_ 647 HvBattCellURSMS116 "CellU RSMS Signal Group  Detail voltage of cells in HV battery";
CM_ SG_ 647 HvBattCellURSMS117 "CellU RSMS Signal Group  Detail voltage of cells in HV battery";
CM_ SG_ 647 HvBattCellURSMS118 "CellU RSMS Signal Group  Detail voltage of cells in HV battery";
CM_ SG_ 647 HvBattCellURSMS119 "CellU RSMS Signal Group  Detail voltage of cells in HV battery";
CM_ SG_ 647 HvBattCellURSMS120 "CellU RSMS Signal Group  Detail voltage of cells in HV battery";
CM_ SG_ 647 HvBattCellURSMS121 "CellU RSMS Signal Group  Detail voltage of cells in HV battery";
CM_ SG_ 647 HvBattCellURSMS122 "CellU RSMS Signal Group  Detail voltage of cells in HV battery";
CM_ SG_ 647 HvBattCellURSMS123 "CellU RSMS Signal Group  Detail voltage of cells in HV battery";
CM_ SG_ 647 HvBattCellURSMS124 "CellU RSMS Signal Group  Detail voltage of cells in HV battery";
CM_ SG_ 647 HvBattCellURSMS125 "CellU RSMS Signal Group  Detail voltage of cells in HV battery";
CM_ SG_ 647 HvBattCellURSMS126 "CellU RSMS Signal Group  Detail voltage of cells in HV battery";
CM_ SG_ 647 HvBattCellURSMS127 "CellU RSMS Signal Group  Detail voltage of cells in HV battery";
CM_ SG_ 647 HvBattCellURSMS128 "CellU RSMS Signal Group  Detail voltage of cells in HV battery";
CM_ SG_ 648 HvBattCellURSMS129 "CellU RSMS Signal Group  Detail voltage of cells in HV battery";
CM_ SG_ 648 HvBattCellURSMS130 "CellU RSMS Signal Group  Detail voltage of cells in HV battery";
CM_ SG_ 648 HvBattCellURSMS131 "CellU RSMS Signal Group  Detail voltage of cells in HV battery";
CM_ SG_ 648 HvBattCellURSMS132 "CellU RSMS Signal Group  Detail voltage of cells in HV battery";
CM_ SG_ 648 HvBattCellURSMS133 "CellU RSMS Signal Group  Detail voltage of cells in HV battery";
CM_ SG_ 648 HvBattCellURSMS134 "CellU RSMS Signal Group  Detail voltage of cells in HV battery";
CM_ SG_ 648 HvBattCellURSMS135 "CellU RSMS Signal Group  Detail voltage of cells in HV battery";
CM_ SG_ 648 HvBattCellURSMS136 "CellU RSMS Signal Group  Detail voltage of cells in HV battery";
CM_ SG_ 648 HvBattCellURSMS137 "CellU RSMS Signal Group  Detail voltage of cells in HV battery";
CM_ SG_ 648 HvBattCellURSMS138 "CellU RSMS Signal Group  Detail voltage of cells in HV battery";
CM_ SG_ 648 HvBattCellURSMS139 "CellU RSMS Signal Group  Detail voltage of cells in HV battery";
CM_ SG_ 648 HvBattCellURSMS140 "CellU RSMS Signal Group  Detail voltage of cells in HV battery";
CM_ SG_ 648 HvBattCellURSMS141 "CellU RSMS Signal Group  Detail voltage of cells in HV battery";
CM_ SG_ 648 HvBattCellURSMS142 "CellU RSMS Signal Group  Detail voltage of cells in HV battery";
CM_ SG_ 648 HvBattCellURSMS143 "CellU RSMS Signal Group  Detail voltage of cells in HV battery";
CM_ SG_ 648 HvBattCellURSMS144 "CellU RSMS Signal Group  Detail voltage of cells in HV battery";
CM_ SG_ 649 HvBattCellURSMS145 "CellU RSMS Signal Group  Detail voltage of cells in HV battery";
CM_ SG_ 649 HvBattCellURSMS146 "CellU RSMS Signal Group  Detail voltage of cells in HV battery";
CM_ SG_ 649 HvBattCellURSMS147 "CellU RSMS Signal Group  Detail voltage of cells in HV battery";
CM_ SG_ 649 HvBattCellURSMS148 "CellU RSMS Signal Group  Detail voltage of cells in HV battery";
CM_ SG_ 649 HvBattCellURSMS149 "CellU RSMS Signal Group  Detail voltage of cells in HV battery";
CM_ SG_ 649 HvBattCellURSMS150 "CellU RSMS Signal Group  Detail voltage of cells in HV battery";
CM_ SG_ 649 HvBattCellURSMS151 "CellU RSMS Signal Group  Detail voltage of cells in HV battery";
CM_ SG_ 649 HvBattCellURSMS152 "CellU RSMS Signal Group  Detail voltage of cells in HV battery";
CM_ SG_ 649 HvBattCellURSMS153 "CellU RSMS Signal Group  Detail voltage of cells in HV battery";
CM_ SG_ 649 HvBattCellURSMS154 "CellU RSMS Signal Group  Detail voltage of cells in HV battery";
CM_ SG_ 649 HvBattCellURSMS155 "CellU RSMS Signal Group  Detail voltage of cells in HV battery";
CM_ SG_ 649 HvBattCellURSMS156 "CellU RSMS Signal Group  Detail voltage of cells in HV battery";
CM_ SG_ 649 HvBattCellURSMS157 "CellU RSMS Signal Group  Detail voltage of cells in HV battery";
CM_ SG_ 649 HvBattCellURSMS158 "CellU RSMS Signal Group  Detail voltage of cells in HV battery";
CM_ SG_ 649 HvBattCellURSMS159 "CellU RSMS Signal Group  Detail voltage of cells in HV battery";
CM_ SG_ 649 HvBattCellURSMS160 "CellU RSMS Signal Group  Detail voltage of cells in HV battery";
CM_ SG_ 650 HvBattCellURSMS161 "CellU RSMS Signal Group  Detail voltage of cells in HV battery";
CM_ SG_ 650 HvBattCellURSMS162 "CellU RSMS Signal Group  Detail voltage of cells in HV battery";
CM_ SG_ 650 HvBattCellURSMS163 "CellU RSMS Signal Group  Detail voltage of cells in HV battery";
CM_ SG_ 650 HvBattCellURSMS164 "CellU RSMS Signal Group  Detail voltage of cells in HV battery";
CM_ SG_ 650 HvBattCellURSMS165 "CellU RSMS Signal Group  Detail voltage of cells in HV battery";
CM_ SG_ 650 HvBattCellURSMS166 "CellU RSMS Signal Group  Detail voltage of cells in HV battery";
CM_ SG_ 650 HvBattCellURSMS167 "CellU RSMS Signal Group  Detail voltage of cells in HV battery";
CM_ SG_ 650 HvBattCellURSMS168 "CellU RSMS Signal Group  Detail voltage of cells in HV battery";
CM_ SG_ 650 HvBattCellURSMS169 "CellU RSMS Signal Group  Detail voltage of cells in HV battery";
CM_ SG_ 650 HvBattCellURSMS170 "CellU RSMS Signal Group  Detail voltage of cells in HV battery";
CM_ SG_ 650 HvBattCellURSMS171 "CellU RSMS Signal Group  Detail voltage of cells in HV battery";
CM_ SG_ 650 HvBattCellURSMS172 "CellU RSMS Signal Group  Detail voltage of cells in HV battery";
CM_ SG_ 650 HvBattCellURSMS173 "CellU RSMS Signal Group  Detail voltage of cells in HV battery";
CM_ SG_ 650 HvBattCellURSMS174 "CellU RSMS Signal Group  Detail voltage of cells in HV battery";
CM_ SG_ 650 HvBattCellURSMS175 "CellU RSMS Signal Group  Detail voltage of cells in HV battery";
CM_ SG_ 650 HvBattCellURSMS176 "CellU RSMS Signal Group  Detail voltage of cells in HV battery";
CM_ SG_ 651 HvBattCellURSMS177 "CellU RSMS Signal Group  Detail voltage of cells in HV battery";
CM_ SG_ 651 HvBattCellURSMS178 "CellU RSMS Signal Group  Detail voltage of cells in HV battery";
CM_ SG_ 651 HvBattCellURSMS179 "CellU RSMS Signal Group  Detail voltage of cells in HV battery";
CM_ SG_ 651 HvBattCellURSMS180 "CellU RSMS Signal Group  Detail voltage of cells in HV battery";
CM_ SG_ 651 HvBattCellURSMS181 "CellU RSMS Signal Group  Detail voltage of cells in HV battery";
CM_ SG_ 651 HvBattCellURSMS182 "CellU RSMS Signal Group  Detail voltage of cells in HV battery";
CM_ SG_ 651 HvBattCellURSMS183 "CellU RSMS Signal Group  Detail voltage of cells in HV battery";
CM_ SG_ 651 HvBattCellURSMS184 "CellU RSMS Signal Group  Detail voltage of cells in HV battery";
CM_ SG_ 651 HvBattCellURSMS185 "CellU RSMS Signal Group  Detail voltage of cells in HV battery";
CM_ SG_ 651 HvBattCellURSMS186 "CellU RSMS Signal Group  Detail voltage of cells in HV battery";
CM_ SG_ 651 HvBattCellURSMS187 "CellU RSMS Signal Group  Detail voltage of cells in HV battery";
CM_ SG_ 651 HvBattCellURSMS188 "CellU RSMS Signal Group  Detail voltage of cells in HV battery";
CM_ SG_ 651 HvBattCellURSMS189 "CellU RSMS Signal Group  Detail voltage of cells in HV battery";
CM_ SG_ 651 HvBattCellURSMS190 "CellU RSMS Signal Group  Detail voltage of cells in HV battery";
CM_ SG_ 651 HvBattCellURSMS191 "CellU RSMS Signal Group  Detail voltage of cells in HV battery";
CM_ SG_ 651 HvBattCellURSMS192 "CellU RSMS Signal Group  Detail voltage of cells in HV battery";
CM_ SG_ 652 HvBattCellURSMS193 "CellU RSMS Signal Group  Detail voltage of cells in HV battery";
CM_ SG_ 652 HvBattCellURSMS194 "CellU RSMS Signal Group  Detail voltage of cells in HV battery";
CM_ SG_ 652 HvBattCellURSMS195 "CellU RSMS Signal Group  Detail voltage of cells in HV battery";
CM_ SG_ 652 HvBattCellURSMS196 "CellU RSMS Signal Group  Detail voltage of cells in HV battery";
CM_ SG_ 652 HvBattCellURSMS197 "CellU RSMS Signal Group  Detail voltage of cells in HV battery";
CM_ SG_ 652 HvBattCellURSMS198 "CellU RSMS Signal Group  Detail voltage of cells in HV battery";
CM_ SG_ 652 HvBattCellURSMS199 "CellU RSMS Signal Group  Detail voltage of cells in HV battery";
CM_ SG_ 652 HvBattCellURSMS200 "CellU RSMS Signal Group  Detail voltage of cells in HV battery";
CM_ SG_ 652 HvBattCellURSMS201 "CellU RSMS Signal Group  Detail voltage of cells in HV battery";
CM_ SG_ 652 HvBattCellURSMS202 "CellU RSMS Signal Group  Detail voltage of cells in HV battery";
CM_ SG_ 652 HvBattCellURSMS203 "CellU RSMS Signal Group  Detail voltage of cells in HV battery";
CM_ SG_ 652 HvBattCellURSMS204 "CellU RSMS Signal Group  Detail voltage of cells in HV battery";
CM_ SG_ 652 HvBattCellURSMS205 "CellU RSMS Signal Group  Detail voltage of cells in HV battery";
CM_ SG_ 652 HvBattCellURSMS206 "CellU RSMS Signal Group  Detail voltage of cells in HV battery";
CM_ SG_ 652 HvBattCellURSMS207 "CellU RSMS Signal Group  Detail voltage of cells in HV battery";
CM_ SG_ 652 HvBattCellURSMS208 "CellU RSMS Signal Group  Detail voltage of cells in HV battery";
CM_ SG_ 653 HvBattCellURSMS209 "CellU RSMS Signal Group  Detail voltage of cells in HV battery";
CM_ SG_ 653 HvBattCellURSMS210 "CellU RSMS Signal Group  Detail voltage of cells in HV battery";
CM_ SG_ 653 HvBattCellURSMS211 "CellU RSMS Signal Group  Detail voltage of cells in HV battery";
CM_ SG_ 653 HvBattCellURSMS212 "CellU RSMS Signal Group  Detail voltage of cells in HV battery";
CM_ SG_ 653 HvBattCellURSMS213 "CellU RSMS Signal Group  Detail voltage of cells in HV battery";
CM_ SG_ 653 HvBattCellURSMS214 "CellU RSMS Signal Group  Detail voltage of cells in HV battery";
CM_ SG_ 653 HvBattCellURSMS215 "CellU RSMS Signal Group  Detail voltage of cells in HV battery";
CM_ SG_ 653 HvBattCellURSMS216 "CellU RSMS Signal Group  Detail voltage of cells in HV battery";
CM_ SG_ 653 HvBattCellURSMS217 "CellU RSMS Signal Group  Detail voltage of cells in HV battery";
CM_ SG_ 653 HvBattCellURSMS218 "CellU RSMS Signal Group  Detail voltage of cells in HV battery";
CM_ SG_ 653 HvBattCellURSMS219 "CellU RSMS Signal Group  Detail voltage of cells in HV battery";
CM_ SG_ 653 HvBattCellURSMS220 "CellU RSMS Signal Group  Detail voltage of cells in HV battery";
CM_ SG_ 653 HvBattCellURSMS221 "CellU RSMS Signal Group  Detail voltage of cells in HV battery";
CM_ SG_ 653 HvBattCellURSMS222 "CellU RSMS Signal Group  Detail voltage of cells in HV battery";
CM_ SG_ 653 HvBattCellURSMS223 "CellU RSMS Signal Group  Detail voltage of cells in HV battery";
CM_ SG_ 653 HvBattCellURSMS224 "CellU RSMS Signal Group  Detail voltage of cells in HV battery";
CM_ SG_ 654 HvBattCellURSMS225 "CellU RSMS Signal Group  Detail voltage of cells in HV battery";
CM_ SG_ 654 HvBattCellURSMS226 "CellU RSMS Signal Group  Detail voltage of cells in HV battery";
CM_ SG_ 654 HvBattCellURSMS227 "CellU RSMS Signal Group  Detail voltage of cells in HV battery";
CM_ SG_ 654 HvBattCellURSMS228 "CellU RSMS Signal Group  Detail voltage of cells in HV battery";
CM_ SG_ 654 HvBattCellURSMS229 "CellU RSMS Signal Group  Detail voltage of cells in HV battery";
CM_ SG_ 654 HvBattCellURSMS230 "CellU RSMS Signal Group  Detail voltage of cells in HV battery";
CM_ SG_ 654 HvBattCellURSMS231 "CellU RSMS Signal Group  Detail voltage of cells in HV battery";
CM_ SG_ 654 HvBattCellURSMS232 "CellU RSMS Signal Group  Detail voltage of cells in HV battery";
CM_ SG_ 654 HvBattCellURSMS233 "CellU RSMS Signal Group  Detail voltage of cells in HV battery";
CM_ SG_ 654 HvBattCellURSMS234 "CellU RSMS Signal Group  Detail voltage of cells in HV battery";
CM_ SG_ 654 HvBattCellURSMS235 "CellU RSMS Signal Group  Detail voltage of cells in HV battery";
CM_ SG_ 654 HvBattCellURSMS236 "CellU RSMS Signal Group  Detail voltage of cells in HV battery";
CM_ SG_ 654 HvBattCellURSMS237 "CellU RSMS Signal Group  Detail voltage of cells in HV battery";
CM_ SG_ 654 HvBattCellURSMS238 "CellU RSMS Signal Group  Detail voltage of cells in HV battery";
CM_ SG_ 654 HvBattCellURSMS239 "CellU RSMS Signal Group  Detail voltage of cells in HV battery";
CM_ SG_ 654 HvBattCellURSMS240 "CellU RSMS Signal Group  Detail voltage of cells in HV battery";
CM_ SG_ 678 BmsFaultReact "BMS FID";
CM_ SG_ 678 GeTHRBpsSensorErrFault "BMS Fault information flag";
CM_ SG_ 678 HallCurrSampDiag "Current sampling diagnosis result of HALL-type sensor";
CM_ SG_ 678 HvBattCellSocSts "Hv battery cell SOC status";
CM_ SG_ 678 HvBattCellTempNotOkNum "Number of faulty cell temperature sampling channels";
CM_ SG_ 678 HvBattCellVoltNotOkNum "Number of faulty cell voltage sampling channels";
CM_ SG_ 678 HvBattChrgnDrtRsn "Hv battery charge current limit derate reason";
CM_ SG_ 678 HvBattDcChgSts "电池直流充电状态";
CM_ SG_ 678 HvBattDchaSocThisDischrgnCyc "High Voltage battery Discharging SOC for this discharging cycle";
CM_ SG_ 678 HvBattDchrgnDrtRsn "Hv battery discharge current limit derate reason";
CM_ SG_ 678 HvBattHvRawU2 "高压采样点2电压";
CM_ SG_ 678 HvBattHvRawU3 "高压采样点3电压";
CM_ SG_ 678 HvBattHvRawU4 "高压采样点4电压";
CM_ SG_ 678 HvBattHvRawU5 "高压采样点5电压";
CM_ SG_ 678 HvBattHvRawU6 "高压采样点6电压";
CM_ SG_ 678 HvBattHvRawU7 "高压采样点7电压";
CM_ SG_ 678 HvBattHvRawU8 "高压采样点8电压";
CM_ SG_ 678 HvBattLeakSensU "HV battery Leak senss Voltage";
CM_ SG_ 678 HvBattPfcChipDiag "Pyro-Fuse squib chip diagnosis result";
CM_ SG_ 678 HvBattPfcDeploySts "Pyro-Fuse Deploy Status";
CM_ SG_ 678 HvBattPheatgForChrgnFnshTi "hvbattery preheating for charging finish time
电池预热完成剩余时间";
CM_ SG_ 678 HvBattRutPheatgFinshd "HV battery finish route preheating process
电池预热状态反馈";
CM_ SG_ 678 HVSampDiag "HV sampling diagnosis result";
CM_ SG_ 678 ShuntCurrSampDiag "Current sampling diagnosis result of shunt-type sensor";
CM_ SG_ 679 HvBattCellURSMS241 "CellU RSMS Signal Group  Detail voltage of cells in HV battery";
CM_ SG_ 679 HvBattCellURSMS242 "CellU RSMS Signal Group  Detail voltage of cells in HV battery";
CM_ SG_ 679 HvBattCellURSMS243 "CellU RSMS Signal Group  Detail voltage of cells in HV battery";
CM_ SG_ 679 HvBattCellURSMS244 "CellU RSMS Signal Group  Detail voltage of cells in HV battery";
CM_ SG_ 679 HvBattCellURSMS245 "CellU RSMS Signal Group  Detail voltage of cells in HV battery";
CM_ SG_ 679 HvBattCellURSMS246 "CellU RSMS Signal Group  Detail voltage of cells in HV battery";
CM_ SG_ 679 HvBattCellURSMS247 "CellU RSMS Signal Group  Detail voltage of cells in HV battery";
CM_ SG_ 679 HvBattCellURSMS248 "CellU RSMS Signal Group  Detail voltage of cells in HV battery";
CM_ SG_ 679 HvBattCellURSMS249 "CellU RSMS Signal Group  Detail voltage of cells in HV battery";
CM_ SG_ 679 HvBattCellURSMS250 "CellU RSMS Signal Group  Detail voltage of cells in HV battery";
CM_ SG_ 679 HvBattCellURSMS251 "CellU RSMS Signal Group  Detail voltage of cells in HV battery";
CM_ SG_ 679 HvBattCellURSMS252 "CellU RSMS Signal Group  Detail voltage of cells in HV battery";
CM_ SG_ 679 HvBattCellURSMS253 "CellU RSMS Signal Group  Detail voltage of cells in HV battery";
CM_ SG_ 679 HvBattCellURSMS254 "CellU RSMS Signal Group  Detail voltage of cells in HV battery";
CM_ SG_ 679 HvBattCellURSMS255 "CellU RSMS Signal Group  Detail voltage of cells in HV battery";
CM_ SG_ 679 HvBattCellURSMS256 "CellU RSMS Signal Group  Detail voltage of cells in HV battery";
CM_ SG_ 821 HvBattAFEErrMsk1 "AFE Sampling Chip Fault Group 1 
电芯采样芯片故障组1";
CM_ SG_ 821 HvBattAFEErrMsk2 "AFE Sampling Chip Fault Group 2
电芯采样芯片故障组2";
CM_ SG_ 821 HvBattAFEErrMsk3 "AFE Sampling Chip Fault Group 3
电芯采样芯片故障组3";
CM_ SG_ 821 HvBattAFEErrMsk4 "AFE Sampling Chip Fault Group 4
电芯采样芯片故障组4";
CM_ SG_ 821 HvBattBJBErrMsk1 "BJB Sampling Chip Fault Group 1
高压采样芯片故障组1";
CM_ SG_ 821 HvBattBJBErrMsk2 "BJB Sampling Chip Fault Group 2 
高压采样芯片故障组2";
CM_ SG_ 821 HvBattBJBErrMsk3 "BJB Sampling Chip Fault Group 3
高压采样芯片故障组3";
CM_ SG_ 821 HvBattMCUErrMsk1 "MCU Chip Fault Group1
MCU主芯片故障组1";
CM_ SG_ 821 HvBattMCUErrMsk2 "MCU Chip Fault Group2
MCU主芯片故障组2";
CM_ SG_ 821 HvBattMCUErrMsk3 "MCU Chip Fault Group3
MCU主芯片故障组3";
CM_ SG_ 821 HvBattMCUErrMsk4 "MCU Chip Fault Group4
MCU主芯片故障组4";
CM_ SG_ 821 HvBattMCUErrMsk5 "MCU Chip Fault Group5
MCU主芯片故障组5";
CM_ SG_ 821 HvBattMCUErrMsk6 "MCU Chip Fault Group6
MCU主芯片故障组6";
CM_ SG_ 821 HvBattMCUErrMsk7 "MCU Chip Fault Group7
MCU主芯片故障组7";
CM_ SG_ 821 HvBattMCUErrMsk8 "MCU Chip Fault Group8
MCU主芯片故障组8";
CM_ SG_ 821 HvBattSBCErrMsk1 "SBC Chip Fault Group1
电源芯片故障组1";
CM_ SG_ 832 HvBattTempRSMS1 "BattTemp RSMS Signal Group  Detail temperature of probes in HV battery";
CM_ SG_ 832 HvBattTempRSMS10 "BattTemp RSMS Signal Group  Detail temperature of probes in HV battery";
CM_ SG_ 832 HvBattTempRSMS11 "BattTemp RSMS Signal Group  Detail temperature of probes in HV battery";
CM_ SG_ 832 HvBattTempRSMS12 "BattTemp RSMS Signal Group  Detail temperature of probes in HV battery";
CM_ SG_ 832 HvBattTempRSMS13 "BattTemp RSMS Signal Group  Detail temperature of probes in HV battery";
CM_ SG_ 832 HvBattTempRSMS14 "BattTemp RSMS Signal Group  Detail temperature of probes in HV battery";
CM_ SG_ 832 HvBattTempRSMS15 "BattTemp RSMS Signal Group  Detail temperature of probes in HV battery";
CM_ SG_ 832 HvBattTempRSMS16 "BattTemp RSMS Signal Group  Detail temperature of probes in HV battery";
CM_ SG_ 832 HvBattTempRSMS2 "BattTemp RSMS Signal Group  Detail temperature of probes in HV battery";
CM_ SG_ 832 HvBattTempRSMS3 "BattTemp RSMS Signal Group  Detail temperature of probes in HV battery";
CM_ SG_ 832 HvBattTempRSMS4 "BattTemp RSMS Signal Group  Detail temperature of probes in HV battery";
CM_ SG_ 832 HvBattTempRSMS5 "BattTemp RSMS Signal Group  Detail temperature of probes in HV battery";
CM_ SG_ 832 HvBattTempRSMS6 "BattTemp RSMS Signal Group  Detail temperature of probes in HV battery";
CM_ SG_ 832 HvBattTempRSMS7 "BattTemp RSMS Signal Group  Detail temperature of probes in HV battery";
CM_ SG_ 832 HvBattTempRSMS8 "BattTemp RSMS Signal Group  Detail temperature of probes in HV battery";
CM_ SG_ 832 HvBattTempRSMS9 "BattTemp RSMS Signal Group  Detail temperature of probes in HV battery";
CM_ SG_ 843 DcChrgDegradedID "充电降流原因ID";
CM_ SG_ 843 HvBattChrgFailrRsnID "充电失败原因ID";
CM_ SG_ 901 HVBattCellVoltCpnsInfo "AFE Cell Voltage Compensation Related Info
AFE 单体电压补偿信息记录";
CM_ SG_ 901 HvBattCooltTReq "HV battery coolant temperature request.";
CM_ SG_ 901 HvBattDCchrgdEgyThisChrgnCyc "DC charging energy in this DC charging cycle";
CM_ SG_ 901 HvBattDevmtGrp05 "HV Battery development group 05";
CM_ SG_ 901 HvBattDevmtGrp06 "HV battery development group 06";
CM_ SG_ 901 HvBattDevmtGrp07 "HV Battery development group 07";
CM_ SG_ 901 HvBattDevmtGrp08 "HV Battery development group 08";
CM_ SG_ 901 HvBattEgyDispForChrgnToTarSoC "HV battery  display energy available for charging to target SoC referring to a user defined charging target SOC 
用于充电场景 最大允许充电SoC在100%";
CM_ SG_ 901 HvBattEgyDispForDchrgnToTarSoC "HV battery  display energy available for discharging to target SoC referring to a user defined discharging target SOC 
用于V2X场景 最小允许放电SoC在20%";
CM_ SG_ 912 BalOnCellNumb "当前开启均衡单体数目";
CM_ SG_ 912 CMU1ComErrTi "Accumulated duration of communication error of any AFE on CMU 1";
CM_ SG_ 912 CMU2ComErrTi "Accumulated duration of communication error of any AFE on CMU 2";
CM_ SG_ 912 CMU3ComErrTi "Accumulated duration of communication error of any AFE on CMU 3";
CM_ SG_ 912 HvBattCellAvrgSocErr "单体平均SOC计算误差";
CM_ SG_ 912 HvBattCellMaxSoc "单体最大SOC";
CM_ SG_ 912 HvBattCellMaxSocErr "单体最大SOC计算误差";
CM_ SG_ 912 HvBattCellMaxSocErrIdx "单体最大SOC计算误差 index";
CM_ SG_ 912 HvBattCellMaxSocIdx "单体最大SOC index";
CM_ SG_ 912 HvBattCellMinSoc "单体最小SOC";
CM_ SG_ 912 HvBattCellMinSocIdx "单体最小SOC index";
CM_ SG_ 912 HvBattEgyAvlForChrgnToTarSoC "HV battery energy available for charging to target SoC referring to a user defined charging target SOC 
用于充电场景 最大允许充电SoC在100%";
CM_ SG_ 912 HvBattEgyAvlForDchrgnToTarSoC "HV battery energy available for discharging to target SoC referring to a user defined discharging target SOC 
用于V2X场景 最小允许放电SoC在20%";
CM_ SG_ 912 HvBattPressureInsdPack "HV battery pressure inside the pack.";
CM_ SG_ 912 HvBattSoCLimMax "HV battery state of charge limit max  用于说明DOD的上限";
CM_ SG_ 912 HvBattSoCLimMin "HV battery state of charge limit min 用于说明DOD的下限";
CM_ SG_ 912 HvPrechargeTimer "最近一次预充时间";
CM_ SG_ 916 HvBattDchaEgyThisCycRSMS "HV battery discharging energy accumulate in this cycle";
CM_ SG_ 916 HvBattRecupEgyThisCycRSMS "HV battery recuperated energy accumulate in this cycle";
CM_ SG_ 928 EaCTCCutoffCounter0 "calculated count of Cut off HV relay in current range  1";
CM_ SG_ 928 EaCTCCutoffCounter1 "calculated count of Cut off HV relay in current range  2";
CM_ SG_ 928 EaCTCCutoffCounter2 "calculated count of Cut off HV relay in current range  3";
CM_ SG_ 928 EaCTCCutoffCounter3 "calculated count of Cut off HV relay in current range  4";
CM_ SG_ 928 EaCTCCutoffCounter4 "calculated count of Cut off HV relay in current range  5";
CM_ SG_ 928 EaCTCCutoffCounter5 "calculated count of Cut off HV relay in current range  6";
CM_ SG_ 928 EaCTCCutoffCounter6 "calculated count of Cut off HV relay in current range  7";
CM_ SG_ 928 EaCTCCutoffCounter7 "calculated count of Cut off HV relay in current range  8";
CM_ SG_ 928 HvBattChargePwrLimit "The battery pack allows for charging power
电池包允许充电功率";
CM_ SG_ 928 HvBattChargerMaxPwr "Maximum power of charging station
充电桩最大功率";
CM_ SG_ 928 HvBattChrgnMapCurr "Charging meter check current
充电查表电流";
CM_ SG_ 928 HVBattChrgQuaInf "calculated count of low quality charger usage

低质量充电桩使用次数记录";
CM_ SG_ 928 HvbattChrgrPlsCurLv1Cnt "充电脉冲电流故障1级发生次数";
CM_ SG_ 928 HvBattCondPredIndex "Polling code for predicting future operating conditions of battery cells
电芯未来工况预测值轮询码";
CM_ SG_ 928 HVBattDaisyChnQuaInf "DaisyChnQuality Information";
CM_ SG_ 928 HvBattDCChrgrCc1Volt "Voltage of CC1 (for 2015+)
CC1电压（充电2015+标准）";
CM_ SG_ 928 HvBattDCChrgrCc2Volt "Voltage of CC2 (for 2015/2015+)
CC2电压（充电2015/2015+标准）";
CM_ SG_ 928 HvBattSOCFcn1 "SOC计算状态信息";
CM_ SG_ 928 HvBattSOCFcn2 "SOC计算状态信息";
CM_ SG_ 928 HvBattSOCFcn3 "SOC计算状态信息";
CM_ SG_ 928 HvBattSOCFcn4 "SOC计算状态信息";
CM_ SG_ 928 HvBattSOCFcn5 "SOC计算状态信息";
CM_ SG_ 928 HvBattSOCFcn6 "SOC计算状态信息";
CM_ SG_ 928 HvBattSOCFcn7 "SOC计算状态信息";
CM_ SG_ 928 HvBattSOCFcn8 "SOC计算状态信息";
CM_ SG_ 930 HvBattMonitorReserved1 "HV battery Monitor Reserved Signal1";
CM_ SG_ 930 HvBattMonitorReserved10 "HV battery Monitor Reserved Signal10";
CM_ SG_ 930 HvBattMonitorReserved2 "HV battery Monitor Reserved Signal2";
CM_ SG_ 930 HvBattMonitorReserved3 "HV battery Monitor Reserved Signal3";
CM_ SG_ 930 HvBattMonitorReserved4 "HV battery Monitor Reserved Signal4";
CM_ SG_ 930 HvBattMonitorReserved5 "HV battery Monitor Reserved Signal5";
CM_ SG_ 930 HvBattMonitorReserved6 "HV battery Monitor Reserved Signal6";
CM_ SG_ 930 HvBattMonitorReserved7 "HV battery Monitor Reserved Signal7";
CM_ SG_ 930 HvBattMonitorReserved8 "HV battery Monitor Reserved Signal8";
CM_ SG_ 930 HvBattMonitorReserved9 "HV battery Monitor Reserved Signal9";
CM_ SG_ 991 FlybackCtrReqRsn "Reason for Flyback output On and Off request
flyback的打开关闭请求原因";
CM_ SG_ 991 HvBattActvHeatTrfPwrTar "HV battery Active heat transfer power target
电池换热目标功率值";
CM_ SG_ 991 HvBattSocCalcResv1 "SOC内部信号1";
CM_ SG_ 991 HvBattSocCalcResv2 "SOC内部信号2";
CM_ SG_ 991 HvBattSocCalcResv3 "SOC内部信号3";
CM_ SG_ 991 HvBattSocCalcResv4 "SOC内部信号4";
CM_ SG_ 991 HvBattSocCalcResv5 "SOC内部信号5";
CM_ SG_ 991 HvBattSocCalcResv6 "SOC内部信号6";
CM_ SG_ 991 HvBattSocCalcResv7 "SOC内部信号7";
CM_ SG_ 991 HvBattSocCalcResv8 "SOC内部信号8";
CM_ SG_ 1001 BMUMcuResetReason "BMU MCU reset reason";
CM_ SG_ 1001 BMUNVFault "BMU NV storage fault";
CM_ SG_ 1001 HvBattAFECellTempLF "Cell temperature related AFE latent fault";
CM_ SG_ 1001 HvBattAFECellVoltLF "Cell voltage related AFE latent fault";
CM_ SG_ 1001 HvBattBMSTotTiHrWithTempRSMS "HV battery total Sleep Time Hour in different Temp";
CM_ SG_ 1001 HvBattBMSTotTiHrWithTempRSMSCode "HV battery total Sleep Time Hour in different Temp Code";
CM_ SG_ 1001 HvBattBPSDiag "BPS fault";
CM_ SG_ 1001 HvBattCellBalAllwSts "Cell均衡允许条件状态
bit n balance channel n allowing status";
CM_ SG_ 1001 HvBattCellBalAllwStsIdx "Chip均衡允许条件状态单体index
current chip index for allowing status";
CM_ SG_ 1001 HvBattCellBalRemainITIdx "Cell均衡剩余时间单体index
current chip index for balance remaining time";
CM_ SG_ 1001 HvBattCellBalRemainTi "Cell均衡剩余时间
bit n balance channel n remaining time";
CM_ SG_ 1001 HvBattCellBalTempMax "均衡最大板子温度
the max temperature of balance";
CM_ SG_ 1001 HvBattCellBBTemp1 "Cell busbar temperature 1";
CM_ SG_ 1001 HvBattCellBBTemp2 "Cell busbar temperature 2";
CM_ SG_ 1001 HvBattCellBBTemp3 "Cell busbar temperature 3";
CM_ SG_ 1001 HvBattCellBBTemp4 "Cell busbar temperature 4";
CM_ SG_ 1001 HvBattCellBBTemp5 "Cell busbar temperature 5";
CM_ SG_ 1001 HvBattCellBBTemp6 "Cell busbar temperature 6";
CM_ SG_ 1001 HvBattCellBBVltg1 "Cell busbar voltage 1";
CM_ SG_ 1001 HvBattCellBBVltg2 "Cell busbar voltage 2";
CM_ SG_ 1001 HvBattCellLastCalCapRSMS "HV battery Cell Cal SOH Last Time";
CM_ SG_ 1001 HvBattCellLastCalCapRSMSCode "HV battery Cell Cal SOH Last Time Code";
CM_ SG_ 1001 HvBattCellTotBalAsRSMS "HV battery total Used Ah in different mode and Temp";
CM_ SG_ 1001 HvBattCellTotBalAsRSMSCode "HV battery total Used Ah in different mode and Temp Code";
CM_ SG_ 1001 HvBattChipBalSts "Chip均衡实际状态
bit n balance channel n active status";
CM_ SG_ 1001 HvBattChipBalStsIdx "Chip均衡芯片index
current chip index for balance status";
CM_ SG_ 1001 HvBattCntctClsdTimesRSMS "HV battery MainContactor total closed times";
CM_ SG_ 1001 HvBattCpCalcdCnt "Hv battery cell capacity calculated count";
CM_ SG_ 1001 HvBattCpUpdRsn "Hv battery cell capacity update reason";
CM_ SG_ 1001 HvBattHvBoxBBTemp1 "HV-Box busbar temperature 1";
CM_ SG_ 1001 HvBattHvBoxBBTemp2 "HV-Box busbar temperature 2";
CM_ SG_ 1001 HvBattHvBoxBBTemp3 "HV-Box busbar temperature 3";
CM_ SG_ 1001 HvBattPriorityThermalSt "hvbattery priority thermal state
高优电池热管理需求中";
CM_ SG_ 1001 HvBattRCalcdCnt "Hv battery cell resistance calculated count";
CM_ SG_ 1001 HvBattRUpdRsn "Hv battery cell resistance update reason";
CM_ SG_ 1001 HvBattShuntLF "Shunt type current sampling latent fault";
CM_ SG_ 1001 HvBattThermalTiOut "hvbattery thermal time out 
高压电池反馈的电池热管理响应超时状态";
CM_ SG_ 1001 HvBattThrSigFlgRsn "Thermo Runaway Single reason flg";
CM_ SG_ 1001 HvBattTotEgyAhWithCRateRSMS "HV battery total Used Ah in different mode and Crate";
CM_ SG_ 1001 HvBattTotEgyAhWithCRateRSMSCode "HV battery total Used Ah in different mode and CRate Code";
CM_ SG_ 1001 HvBattTotEgyAhWithTempRSMS "HV battery total Used Ah in different mode and Temp";
CM_ SG_ 1001 HvBattTotEgyAhWithTempRSMSCode "HV battery total Used Ah  in different mode and Temp Code";
CM_ SG_ 1001 HvBattTotOverCurrAh "HV battery total OverCharged Ah";
CM_ SG_ 1003 HvBattRemaChrgnTiChrgrInfo1 "剩余充电时间计算功能,充电桩报文信息1";
CM_ SG_ 1003 HvBattRemaChrgnTiChrgrInfo2 "剩余充电时间计算功能,充电桩报文信息2";
CM_ SG_ 1003 HvBattRemaChrgnTiChrgrInfo3 "剩余充电时间计算功能,充电桩报文信息3";
CM_ SG_ 1003 HvBattRemaChrgnTiChrgrInfo4 "剩余充电时间计算功能,充电桩报文信息4";
CM_ SG_ 1003 HvBattRemaChrgnTiChrgrInfo5 "剩余充电时间计算功能,充电桩报文信息5";
CM_ SG_ 1003 HvBattRemaChrgnTiChrgrInfo6 "剩余充电时间计算功能,充电桩报文信息6";
CM_ SG_ 1003 HvBattRemaChrgnTiChrgrInfo7 "剩余充电时间计算功能,充电桩报文信息7";
CM_ SG_ 1003 HvBattRemaChrgnTiChrgrInfo8 "剩余充电时间计算功能,充电桩报文信息8";
CM_ SG_ 1003 HvBattRemaChrgnTiCtrlCur "剩余充电时间计算功能,充电控制的电流";
CM_ SG_ 1003 HvBattRemaChrgnTiCtrlU "剩余充电时间计算功能,充电控制的电压";
CM_ SG_ 1003 HvBattRutPheatgThermReqSoc1 "在途加热功能,充电Map查表SOC0对应热管理请求";
CM_ SG_ 1003 HvBattRutPheatgThermReqSoc10 "在途加热功能,充电Map查表SOC45对应热管理请求";
CM_ SG_ 1003 HvBattRutPheatgThermReqSoc11 "在途加热功能,充电Map查表SOC50对应热管理请求";
CM_ SG_ 1003 HvBattRutPheatgThermReqSoc12 "在途加热功能,充电Map查表SOC55对应热管理请求";
CM_ SG_ 1003 HvBattRutPheatgThermReqSoc13 "在途加热功能,充电Map查表SOC60对应热管理请求";
CM_ SG_ 1003 HvBattRutPheatgThermReqSoc14 "在途加热功能,充电Map查表SOC65对应热管理请求";
CM_ SG_ 1003 HvBattRutPheatgThermReqSoc15 "在途加热功能,充电Map查表SOC70对应热管理请求";
CM_ SG_ 1003 HvBattRutPheatgThermReqSoc16 "在途加热功能,充电Map查表SOC75对应热管理请求";
CM_ SG_ 1003 HvBattRutPheatgThermReqSoc17 "在途加热功能,充电Map查表SOC80对应热管理请求";
CM_ SG_ 1003 HvBattRutPheatgThermReqSoc18 "在途加热功能,充电Map查表SOC85对应热管理请求";
CM_ SG_ 1003 HvBattRutPheatgThermReqSoc19 "在途加热功能,充电Map查表SOC90对应热管理请求";
CM_ SG_ 1003 HvBattRutPheatgThermReqSoc2 "在途加热功能,充电Map查表SOC5对应热管理请求";
CM_ SG_ 1003 HvBattRutPheatgThermReqSoc20 "在途加热功能,充电Map查表SOC95对应热管理请求";
CM_ SG_ 1003 HvBattRutPheatgThermReqSoc3 "在途加热功能,充电Map查表SOC10对应热管理请求";
CM_ SG_ 1003 HvBattRutPheatgThermReqSoc4 "在途加热功能,充电Map查表SOC15对应热管理请求";
CM_ SG_ 1003 HvBattRutPheatgThermReqSoc5 "在途加热功能,充电Map查表SOC20对应热管理请求";
CM_ SG_ 1003 HvBattRutPheatgThermReqSoc6 "在途加热功能,充电Map查表SOC25对应热管理请求";
CM_ SG_ 1003 HvBattRutPheatgThermReqSoc7 "在途加热功能,充电Map查表SOC30对应热管理请求";
CM_ SG_ 1003 HvBattRutPheatgThermReqSoc8 "在途加热功能,充电Map查表SOC35对应热管理请求";
CM_ SG_ 1003 HvBattRutPheatgThermReqSoc9 "在途加热功能,充电Map查表SOC40对应热管理请求";
CM_ SG_ 1003 HvBattShuntDriftCurr "HV Batt Shunt Zero drift Current
shunt 零漂电流值";
CM_ SG_ 1005 DCCnctrNegTemp "DC接插件负极温度";
CM_ SG_ 1005 DCCnctrPosTemp "DC接插件正极温度";
CM_ SG_ 1005 HvBattCapRSMS "BMS估计所有单体容量";
CM_ SG_ 1005 HvBattCellNTCIdx "HV battery cell NTC maximum temperature Index";
CM_ SG_ 1005 HvBattCellNTCMaxResv1 "HV battery cell NTC maximum temperature reserved1";
CM_ SG_ 1005 HvBattCellNTCMaxResv2 "HV battery cell NTC maximum temperature reserved2";
CM_ SG_ 1005 HvBattCellNTCMinResv1 "HV battery cell NTC minimum temperature reserved1";
CM_ SG_ 1005 HvBattCellNTCMinResv2 "HV battery cell NTC minimum temperature reserved2";
CM_ SG_ 1005 HvbattChrgPlsCurLv1 "充电瞬间脉冲大电流故障1级";
CM_ SG_ 1005 HvbattChrgPlsCurLv2 "充电瞬间脉冲大电流故障2级";
CM_ SG_ 1005 HvbattChrgrPlsCurLv2Cnt "充电脉冲电流故障2级发生次数";
CM_ SG_ 1005 HVBattDischargeSoCTargetReq "期望用户的放电目标SOC要求";
CM_ SG_ 1005 HvBattLCMInfo1 "LCM功能";
CM_ SG_ 1005 HvBattLCMInfo2 "LCM功能2";
CM_ SG_ 1005 HvBattLCMInfo3 "LCM功能3";
CM_ SG_ 1005 HvBattOverDchaCnt "过放发生次数";
CM_ SG_ 1005 HvBattOverDchaFlg "过放标志位";
CM_ SG_ 1005 HvBattResRSMS "BMS估计所有单体内阻";
CM_ SG_ 1005 HVBattRestTimeReq "充电电池维护阶段的剩余静置时间";
CM_ SG_ 1005 HvBattRutPheatgThermSts1 "在途加热功能,设置目标充电目标SOC对应充电内部热管理状态1";
CM_ SG_ 1005 HvBattRutPheatgThermSts2 "在途加热功能,设置目标充电目标SOC对应充电内部热管理状态2";
CM_ SG_ 1005 HvBattRutPheatgThermSts3 "在途加热功能,设置目标充电目标SOC对应充电内部热管理状态3";
CM_ SG_ 1005 HvBattRutPheatgThermSts4 "在途加热功能,设置目标充电目标SOC对应充电内部热管理状态4";
CM_ SG_ 1005 HvBattSohCalcInfo1 "SOH内部计算信息1";
CM_ SG_ 1005 HvBattSohCalcInfo2 "SOH内部计算信息2";
CM_ SG_ 1005 HvBattSohCalcInfo3 "SOH内部计算信息3";
CM_ SG_ 1005 HvBattSOHRSMSCode "循环单体容量及内阻序号";
CM_ SG_ 1005 HVFlybackPwrAllwd "Flyback rated power
Flyback的额定功率";
CM_ SG_ 1005 PyroFuseMskReq "保险丝断开驱动发出断开指令掩码";
CM_ SG_ 1005 PyroFuseReq "保险丝断开驱动发出断开指令";
CM_ SG_ 1006 HvBattMaxCellSOCPred "Predicted maximum SOC of individual cells
单体最大SOC预测值";
CM_ SG_ 1006 HvBattMaxCellTempPred "Predicted maximum temperature of battery cells
电芯最高温度预测值";
CM_ SG_ 1006 HvBattMaxCellVoltPred "Predicted maximum voltage of a single unit
单体最大电压预测值";
CM_ SG_ 1006 HvBattMinCellSOCPred "Predicted minimum SOC of individual cells
单体最小SOC预测值";
CM_ SG_ 1006 HvBattMinCellTempPred "Predicted minimum temperature of battery cells
电芯最低温度预测值";
CM_ SG_ 1006 HvBattMinCellVoltPred "Predicted minimum voltage of a single unit
单体最低电压预测值";
CM_ SG_ 1006 HvBattPackCodeX1 "Pack Code Signal Group  Pack code X1";
CM_ SG_ 1006 HvBattPackCodeX10 "Pack Code Signal Group  Pack code X10";
CM_ SG_ 1006 HvBattPackCodeX11 "Pack Code Signal Group  Pack code X11";
CM_ SG_ 1006 HvBattPackCodeX12 "Pack Code Signal Group  Pack code X12";
CM_ SG_ 1006 HvBattPackCodeX13 "Pack Code Signal Group  Pack code X13";
CM_ SG_ 1006 HvBattPackCodeX14 "Pack Code Signal Group  Pack code X14";
CM_ SG_ 1006 HvBattPackCodeX15 "Pack Code Signal Group  Pack code X15";
CM_ SG_ 1006 HvBattPackCodeX16 "Pack Code Signal Group  Pack code X16";
CM_ SG_ 1006 HvBattPackCodeX17 "Pack Code Signal Group  Pack code X17";
CM_ SG_ 1006 HvBattPackCodeX18 "Pack Code Signal Group  Pack code X18";
CM_ SG_ 1006 HvBattPackCodeX19 "Pack Code Signal Group  Pack code X19";
CM_ SG_ 1006 HvBattPackCodeX2 "Pack Code Signal Group  Pack code X2";
CM_ SG_ 1006 HvBattPackCodeX20 "Pack Code Signal Group  Pack code X20";
CM_ SG_ 1006 HvBattPackCodeX21 "Pack Code Signal Group  Pack code X21";
CM_ SG_ 1006 HvBattPackCodeX22 "Pack Code Signal Group  Pack code X22";
CM_ SG_ 1006 HvBattPackCodeX23 "Pack Code Signal Group  Pack code X23";
CM_ SG_ 1006 HvBattPackCodeX24 "Pack Code Signal Group  Pack code X24";
CM_ SG_ 1006 HvBattPackCodeX3 "Pack Code Signal Group  Pack code X3";
CM_ SG_ 1006 HvBattPackCodeX4 "Pack Code Signal Group  Pack code X4";
CM_ SG_ 1006 HvBattPackCodeX5 "Pack Code Signal Group  Pack code X5";
CM_ SG_ 1006 HvBattPackCodeX6 "Pack Code Signal Group  Pack code X6";
CM_ SG_ 1006 HvBattPackCodeX7 "Pack Code Signal Group  Pack code X7";
CM_ SG_ 1006 HvBattPackCodeX8 "Pack Code Signal Group  Pack code X8";
CM_ SG_ 1006 HvBattPackCodeX9 "Pack Code Signal Group  Pack code X9";
CM_ SG_ 1010 BDUCooltFlowReq "BDU coolant flow request.";
CM_ SG_ 1010 FlybackCtrSts "The flyback output function status
flyback对外输出功能状态";
CM_ SG_ 1010 HvBattCellBalActvt "HV battery cell balance activate or not 仅用于告知BMS所处的状态 不影响其他使用和运行";
CM_ SG_ 1010 HvBattCellTAvg "HV battery average cell temperature of all sensors.";
CM_ SG_ 1010 HvBattCellTMax "HV battery cell maximum temperature.";
CM_ SG_ 1010 HvBattCellTMaxResv "HV battery cell maximum temperature reserved";
CM_ SG_ 1010 HvBattCellTMin "HV battery cell minimum temperature.";
CM_ SG_ 1010 HvBattCellTMinResv "HV battery cell minimum temperature reserved";
CM_ SG_ 1010 HvBattCooltFlowReq "HV battery coolant flow request.";
CM_ SG_ 1010 HvBattFaultInfoFlag "BMS key fault data collection trigger flag
BMS重点故障采集车端数据触发标志位";
CM_ SG_ 1010 HvBattNTCIdx "HV battery NTC Index";
CM_ SG_ 1010 HvBattPackDesnMaxEngy "HV battery maximum discharging energy to destination";
CM_ SG_ 1010 HvBattSoH "HV battery state of health.";
CM_ SG_ 1010 HVBattTempRiskLvl "HV battery cell  temperaturer risk  level";
CM_ SG_ 1010 HvBattTotChrgdEgyAh "HV battery total charged energy by Ah   accumulate once current is negtive.   This information is used for Battery internal SoH calculation";
CM_ SG_ 1010 HvBattTotChrgdEgyWh "HV battery total charged energy by Wh   accumulate once current is negtive.";
CM_ SG_ 1010 HvBattTotDchrgdEgyAh "HV battery total discharged energy by Ah   accumulate once current is positive . This information is used for Battery internal SoH calculation";
CM_ SG_ 1010 HvBattTotDchrgdEgyWh "HV battery total discharged energy by Wh   accumulate once current is positive.";
CM_ SG_ 1012 DCChrgnPortTNegTerminal "Temperature of DC charging port negtive terminal.";
CM_ SG_ 1012 DCChrgnPortTPosTerminal "Temperature of DC charging port positive terminal.";
CM_ SG_ 1012 HvBattAvgShuntDriftCurr "Shunt average current drift
Shunt均值电流零漂值";
CM_ SG_ 1012 HvBattBMUVersion "HvBatt BMU Version";
CM_ SG_ 1012 HvBattBSWVersion "HvBatt BSW Version";
CM_ SG_ 1012 HvBattCellBBVltg3 "Cell busbar voltage 1
单体间铜巴电压";
CM_ SG_ 1012 HvBattCellQntyRSMS "Quantity of cells in HV battery";
CM_ SG_ 1012 HvBattCMCVersion "HvBatt CMC Version";
CM_ SG_ 1012 HvBattCrsChkRec "碰撞信号检测未确认碰撞事件的历史计次
The accumulated not-confirmed crash event times";
CM_ SG_ 1012 HvBattExpVlvFluNTCTemp1 "Explosion-proof Valve Flue Temperature Sampling 1
防爆阀烟道温度采样1";
CM_ SG_ 1012 HvBattExpVlvFluNTCTemp2 "Explosion-proof Valve Flue Temperature Sampling 2
防爆阀烟道温度采样2";
CM_ SG_ 1012 HvBattExpVlvFluNTCTemp3 "Explosion-proof Valve Flue Temperature Sampling 3
防爆阀烟道温度采样3";
CM_ SG_ 1012 HvBattExpVlvFluNTCTemp4 "Explosion-proof Valve Flue Temperature Sampling 4
防爆阀烟道温度采样4";
CM_ SG_ 1012 HvBattFrqHiSocWarn "Frequent use warning in high SOC area
高SOC区间频繁使用预警";
CM_ SG_ 1012 HvBattHallDriftCurr "HV Batt Hall Zero drift Current
Hall零漂电流值";
CM_ SG_ 1012 HvBattMaxTProbIDRSMS "Number of maximum Temperature Probe in HV Battery";
CM_ SG_ 1012 HvBattMinTProbIDRSMS "Number of minimum Temperature Probe in HV Battery";
CM_ SG_ 1012 HvBattOverCurrentAs "As integral of functional safety overcurrent
功能安全过流的As积分量";
CM_ SG_ 1012 HvBattPackCurrPred "Predicted value of pack current
Pack电流预测值";
CM_ SG_ 1012 HvBattPackQntyRSMS "Total number of packs in HV battery";
CM_ SG_ 1012 HvBattPackVoltPred "Predicted value of pack voltage
Pack电压预测值";
CM_ SG_ 1012 HvBattPfcChkRec "短路过流检测未确认短路事件的历史计次
The accumulated not-confirmed over-current event times";
CM_ SG_ 1012 HvBattPfcFailRsn "主动保险丝未正常点爆原因和计次信息
The reason and counter record for pyrofuse not broken status";
CM_ SG_ 1012 HVBattRefcapVoltInfo "AFE REFCAP Voltage
AFE REFCAP电压信息";
CM_ SG_ 1012 HvBattShuntTemp "Shunt temperature
Shunt 温度";
CM_ SG_ 1012 HvBattSWVersion "HvBatt SW Version";
CM_ SG_ 1012 HvBattTPrbQntyRSMS "Quantity of temperature probes in Hv battery";
CM_ SG_ 1012 HvFlybackACCWh "Flyback AWatt hour Counter
Flyback 瓦时积分";
CM_ SG_ 1012 HvFlybackAvgCur "Flyback Average Current
Flyback平均电流值";
CM_ SG_ 1012 HvFlybackAvgPwr "Flyback Average Power
Flyback平均功耗";
CM_ SG_ 1012 HvFlybackColC "FLyback Column Counter
FLyback 电流积分";
CM_ SG_ 1016 HvBattTempRSMS17 "BattTemp RSMS Signal Group  Detail temperature of probes in HV battery";
CM_ SG_ 1016 HvBattTempRSMS18 "BattTemp RSMS Signal Group  Detail temperature of probes in HV battery";
CM_ SG_ 1016 HvBattTempRSMS19 "BattTemp RSMS Signal Group  Detail temperature of probes in HV battery";
CM_ SG_ 1016 HvBattTempRSMS20 "BattTemp RSMS Signal Group  Detail temperature of probes in HV battery";
CM_ SG_ 1016 HvBattTempRSMS21 "BattTemp RSMS Signal Group  Detail temperature of probes in HV battery";
CM_ SG_ 1016 HvBattTempRSMS22 "BattTemp RSMS Signal Group  Detail temperature of probes in HV battery";
CM_ SG_ 1016 HvBattTempRSMS23 "BattTemp RSMS Signal Group  Detail temperature of probes in HV battery";
CM_ SG_ 1016 HvBattTempRSMS24 "BattTemp RSMS Signal Group  Detail temperature of probes in HV battery";
CM_ SG_ 1016 HvBattTempRSMS25 "BattTemp RSMS Signal Group  Detail temperature of probes in HV battery";
CM_ SG_ 1016 HvBattTempRSMS26 "BattTemp RSMS Signal Group  Detail temperature of probes in HV battery";
CM_ SG_ 1016 HvBattTempRSMS27 "BattTemp RSMS Signal Group  Detail temperature of probes in HV battery";
CM_ SG_ 1016 HvBattTempRSMS28 "BattTemp RSMS Signal Group  Detail temperature of probes in HV battery";
CM_ SG_ 1016 HvBattTempRSMS29 "BattTemp RSMS Signal Group  Detail temperature of probes in HV battery";
CM_ SG_ 1016 HvBattTempRSMS30 "BattTemp RSMS Signal Group  Detail temperature of probes in HV battery";
CM_ SG_ 1016 HvBattTempRSMS31 "BattTemp RSMS Signal Group  Detail temperature of probes in HV battery";
CM_ SG_ 1016 HvBattTempRSMS32 "BattTemp RSMS Signal Group  Detail temperature of probes in HV battery";
CM_ SG_ 1019 HvBattTempRSMS33 "BattTemp RSMS Signal Group  Detail temperature of probes in HV battery";
CM_ SG_ 1019 HvBattTempRSMS34 "BattTemp RSMS Signal Group  Detail temperature of probes in HV battery";
CM_ SG_ 1019 HvBattTempRSMS35 "BattTemp RSMS Signal Group  Detail temperature of probes in HV battery";
CM_ SG_ 1019 HvBattTempRSMS36 "BattTemp RSMS Signal Group  Detail temperature of probes in HV battery";
CM_ SG_ 1019 HvBattTempRSMS37 "BattTemp RSMS Signal Group  Detail temperature of probes in HV battery";
CM_ SG_ 1019 HvBattTempRSMS38 "BattTemp RSMS Signal Group  Detail temperature of probes in HV battery";
CM_ SG_ 1019 HvBattTempRSMS39 "BattTemp RSMS Signal Group  Detail temperature of probes in HV battery";
CM_ SG_ 1019 HvBattTempRSMS40 "BattTemp RSMS Signal Group  Detail temperature of probes in HV battery";
CM_ SG_ 1019 HvBattTempRSMS41 "BattTemp RSMS Signal Group  Detail temperature of probes in HV battery";
CM_ SG_ 1019 HvBattTempRSMS42 "BattTemp RSMS Signal Group  Detail temperature of probes in HV battery";
CM_ SG_ 1019 HvBattTempRSMS43 "BattTemp RSMS Signal Group  Detail temperature of probes in HV battery";
CM_ SG_ 1019 HvBattTempRSMS44 "BattTemp RSMS Signal Group  Detail temperature of probes in HV battery";
CM_ SG_ 1019 HvBattTempRSMS45 "BattTemp RSMS Signal Group  Detail temperature of probes in HV battery";
CM_ SG_ 1019 HvBattTempRSMS46 "BattTemp RSMS Signal Group  Detail temperature of probes in HV battery";
CM_ SG_ 1019 HvBattTempRSMS47 "BattTemp RSMS Signal Group  Detail temperature of probes in HV battery";
CM_ SG_ 1019 HvBattTempRSMS48 "BattTemp RSMS Signal Group  Detail temperature of probes in HV battery";
CM_ SG_ 1020 HvBattTempRSMS49 "BattTemp RSMS Signal Group  Detail temperature of probes in HV battery";
CM_ SG_ 1020 HvBattTempRSMS50 "BattTemp RSMS Signal Group  Detail temperature of probes in HV battery";
CM_ SG_ 1020 HvBattTempRSMS51 "BattTemp RSMS Signal Group  Detail temperature of probes in HV battery";
CM_ SG_ 1020 HvBattTempRSMS52 "BattTemp RSMS Signal Group  Detail temperature of probes in HV battery";
CM_ SG_ 1020 HvBattTempRSMS53 "BattTemp RSMS Signal Group  Detail temperature of probes in HV battery";
CM_ SG_ 1020 HvBattTempRSMS54 "BattTemp RSMS Signal Group  Detail temperature of probes in HV battery";
CM_ SG_ 1020 HvBattTempRSMS55 "BattTemp RSMS Signal Group  Detail temperature of probes in HV battery";
CM_ SG_ 1020 HvBattTempRSMS56 "BattTemp RSMS Signal Group  Detail temperature of probes in HV battery";
CM_ SG_ 1020 HvBattTempRSMS57 "BattTemp RSMS Signal Group  Detail temperature of probes in HV battery";
CM_ SG_ 1020 HvBattTempRSMS58 "BattTemp RSMS Signal Group  Detail temperature of probes in HV battery";
CM_ SG_ 1020 HvBattTempRSMS59 "BattTemp RSMS Signal Group  Detail temperature of probes in HV battery";
CM_ SG_ 1020 HvBattTempRSMS60 "BattTemp RSMS Signal Group  Detail temperature of probes in HV battery";
CM_ SG_ 1020 HvBattTempRSMS61 "BattTemp RSMS Signal Group  Detail temperature of probes in HV battery";
CM_ SG_ 1020 HvBattTempRSMS62 "BattTemp RSMS Signal Group  Detail temperature of probes in HV battery";
CM_ SG_ 1020 HvBattTempRSMS63 "BattTemp RSMS Signal Group  Detail temperature of probes in HV battery";
CM_ SG_ 1020 HvBattTempRSMS64 "BattTemp RSMS Signal Group  Detail temperature of probes in HV battery";

// Attribute definitions
BA_DEF_  "BaudRateCANFD" FLOAT 1000 10000000; // [bps]
BA_DEF_  "Baudrate" INT 1000 1000000; //
BA_DEF_  "BusType" STRING;
BA_DEF_  "DBName" STRING;
BA_DEF_  "ProtocolType" STRING;
BA_DEF_ BU_ "NmAsrNode" ENUM "No","Yes"; //
BA_DEF_ BO_ "CANFD_BRS" ENUM "0","1";
BA_DEF_ BO_ "GenMsgCycleTime" INT 0 30000; //
BA_DEF_ BO_ "GenMsgCycleTimeFast" INT 0 30000; //
BA_DEF_ BO_ "GenMsgDelayTime" INT 0 100000; //
BA_DEF_ BO_ "GenMsgNrOfRepetition" INT 0 100000;
BA_DEF_ BO_ "GenMsgSendType" ENUM "cyclic","spontaneous","cyclicIfActive","spontaneousWithDelay","cyclicAndSpontaneous","cyclicAndSpontaneousWithDelay","IfActive","NoMsgSendType"; // [us]
BA_DEF_ BO_ "GenMsgStartDelayTime" INT 0 100000; //
BA_DEF_ BO_ "NmAsrBaseAddress" HEX 0 536870911; //
BA_DEF_ BO_ "VFrameFormat" ENUM "StandardCAN","ExtendedCAN","reserved","J1939PG","reserved","reserved","reserved","reserved","reserved","reserved","reserved","reserved","reserved","reserved","StandardCAN_FD","ExtendedCAN_FD";
BA_DEF_ SG_ "GenSigSendType" ENUM "Cyclic","OnWrite","OnWriteWithRepetition","OnChange","OnChangeWithRepetition","IfActive","IfActiveWithRepetition","NoSigSendType";
BA_DEF_ SG_ "GenSigStartValue" FLOAT -1.7976931348623157E308 18446744073709551615;

BA_DEF_DEF_ "Baudrate" 1000;
BA_DEF_DEF_ "BusType" "CANFD";
BA_DEF_DEF_ "DBName" "";
BA_DEF_DEF_ "ProtocolType" "";
BA_DEF_DEF_ "NmAsrNode" "Yes";
BA_DEF_DEF_ "CANFD_BRS" "1";
BA_DEF_DEF_ "GenMsgCycleTime" 0;
BA_DEF_DEF_ "GenMsgCycleTimeFast" 0;
BA_DEF_DEF_ "GenMsgDelayTime" 0;
BA_DEF_DEF_ "GenMsgNrOfRepetition" 0;
BA_DEF_DEF_ "GenSigStartValue" 0;
BA_DEF_DEF_ "GenMsgStartDelayTime" 0;
BA_DEF_DEF_ "NmAsrBaseAddress" 1280;
BA_DEF_DEF_ "VFrameFormat" "J1939PG";
BA_DEF_DEF_ "GenSigSendType" "Cyclic";

// Network
BA_ "BaudRateCANFD" 2000000;
BA_ "Baudrate" 500000;
BA_ "BusType" "CAN FD";
BA_ "DBName" "EDCU_PTCANFD";
BA_ "ProtocolType" "CAN";
// Frame: BMS_PTCANFD_0x131
BA_ "GenMsgCycleTime" BO_ 305 20.000;
BA_ "GenMsgSendType" BO_ 305 0;
BA_ "VFrameFormat" BO_ 305 14;
// Frame: BMS_PTCANFD_0x1C1
BA_ "GenMsgCycleTime" BO_ 449 50.000;
BA_ "GenMsgSendType" BO_ 449 0;
BA_ "VFrameFormat" BO_ 449 14;
// Frame: BMS_PTCANFD_0x216
BA_ "GenMsgDelayTime" BO_ 534 10.000;
BA_ "GenMsgSendType" BO_ 534 1;
BA_ "VFrameFormat" BO_ 534 14;
// Frame: BMS_PTCANFD_0x272
BA_ "GenMsgCycleTime" BO_ 626 100.000;
BA_ "GenMsgSendType" BO_ 626 0;
BA_ "VFrameFormat" BO_ 626 14;
// Frame: BMS_PTCANFD_0x273
BA_ "GenMsgCycleTime" BO_ 627 100.000;
BA_ "GenMsgSendType" BO_ 627 0;
BA_ "VFrameFormat" BO_ 627 14;
// Frame: BMS_PTCANFD_0x275
BA_ "GenMsgCycleTime" BO_ 629 100.000;
BA_ "GenMsgSendType" BO_ 629 0;
BA_ "VFrameFormat" BO_ 629 14;
// Frame: BMS_PTCANFD_0x276
BA_ "GenMsgCycleTime" BO_ 630 100.000;
BA_ "GenMsgSendType" BO_ 630 0;
BA_ "VFrameFormat" BO_ 630 14;
// Frame: BMS_PTCANFD_0x278
BA_ "GenMsgCycleTime" BO_ 632 100.000;
BA_ "GenMsgSendType" BO_ 632 0;
BA_ "VFrameFormat" BO_ 632 14;
// Frame: BMS_PTCANFD_0x279
BA_ "GenMsgCycleTime" BO_ 633 500.000;
BA_ "GenMsgSendType" BO_ 633 0;
BA_ "VFrameFormat" BO_ 633 14;
// Frame: BMS_PTCANFD_0x27A
BA_ "GenMsgCycleTime" BO_ 634 500.000;
BA_ "GenMsgSendType" BO_ 634 0;
BA_ "VFrameFormat" BO_ 634 14;
// Frame: BMS_PTCANFD_0x27B
BA_ "GenMsgCycleTime" BO_ 635 500.000;
BA_ "GenMsgSendType" BO_ 635 0;
BA_ "VFrameFormat" BO_ 635 14;
// Frame: BMS_PTCANFD_0x27C
BA_ "GenMsgCycleTime" BO_ 636 500.000;
BA_ "GenMsgSendType" BO_ 636 0;
BA_ "VFrameFormat" BO_ 636 14;
// Frame: BMS_PTCANFD_0x27D
BA_ "GenMsgCycleTime" BO_ 637 500.000;
BA_ "GenMsgSendType" BO_ 637 0;
BA_ "VFrameFormat" BO_ 637 14;
// Frame: BMS_PTCANFD_0x27E
BA_ "GenMsgCycleTime" BO_ 638 500.000;
BA_ "GenMsgSendType" BO_ 638 0;
BA_ "VFrameFormat" BO_ 638 14;
// Frame: BMS_PTCANFD_0x27F
BA_ "GenMsgCycleTime" BO_ 639 500.000;
BA_ "GenMsgSendType" BO_ 639 0;
BA_ "VFrameFormat" BO_ 639 14;
// Frame: BMS_PTCANFD_0x282
BA_ "GenMsgCycleTime" BO_ 642 100.000;
BA_ "GenMsgSendType" BO_ 642 0;
BA_ "VFrameFormat" BO_ 642 14;
// Frame: BMS_PTCANFD_0x285
BA_ "GenMsgCycleTime" BO_ 645 100.000;
BA_ "GenMsgSendType" BO_ 645 0;
BA_ "VFrameFormat" BO_ 645 14;
// Frame: BMS_PTCANFD_0x286
BA_ "GenMsgCycleTime" BO_ 646 100.000;
BA_ "GenMsgSendType" BO_ 646 0;
BA_ "VFrameFormat" BO_ 646 14;
// Frame: BMS_PTCANFD_0x287
BA_ "GenMsgCycleTime" BO_ 647 500.000;
BA_ "GenMsgSendType" BO_ 647 0;
BA_ "VFrameFormat" BO_ 647 14;
// Frame: BMS_PTCANFD_0x288
BA_ "GenMsgCycleTime" BO_ 648 500.000;
BA_ "GenMsgSendType" BO_ 648 0;
BA_ "VFrameFormat" BO_ 648 14;
// Frame: BMS_PTCANFD_0x289
BA_ "GenMsgCycleTime" BO_ 649 500.000;
BA_ "GenMsgSendType" BO_ 649 0;
BA_ "VFrameFormat" BO_ 649 14;
// Frame: BMS_PTCANFD_0x28A
BA_ "GenMsgCycleTime" BO_ 650 500.000;
BA_ "GenMsgSendType" BO_ 650 0;
BA_ "VFrameFormat" BO_ 650 14;
// Frame: BMS_PTCANFD_0x28B
BA_ "GenMsgCycleTime" BO_ 651 500.000;
BA_ "GenMsgSendType" BO_ 651 0;
BA_ "VFrameFormat" BO_ 651 14;
// Frame: BMS_PTCANFD_0x28C
BA_ "GenMsgCycleTime" BO_ 652 500.000;
BA_ "GenMsgSendType" BO_ 652 0;
BA_ "VFrameFormat" BO_ 652 14;
// Frame: BMS_PTCANFD_0x28D
BA_ "GenMsgCycleTime" BO_ 653 500.000;
BA_ "GenMsgSendType" BO_ 653 0;
BA_ "VFrameFormat" BO_ 653 14;
// Frame: BMS_PTCANFD_0x28E
BA_ "GenMsgCycleTime" BO_ 654 500.000;
BA_ "GenMsgSendType" BO_ 654 0;
BA_ "VFrameFormat" BO_ 654 14;
// Frame: BMS_PTCANFD_0x2A6
BA_ "GenMsgCycleTime" BO_ 678 100.000;
BA_ "GenMsgSendType" BO_ 678 0;
BA_ "VFrameFormat" BO_ 678 14;
// Frame: BMS_PTCANFD_0x2A7
BA_ "GenMsgCycleTime" BO_ 679 500.000;
BA_ "GenMsgSendType" BO_ 679 0;
BA_ "VFrameFormat" BO_ 679 14;
// Frame: BMS_PTCANFD_0x335
BA_ "GenMsgCycleTime" BO_ 821 100.000;
BA_ "GenMsgSendType" BO_ 821 0;
BA_ "VFrameFormat" BO_ 821 14;
// Frame: BMS_PTCANFD_0x340
BA_ "GenMsgCycleTime" BO_ 832 1000.000;
BA_ "GenMsgSendType" BO_ 832 0;
BA_ "VFrameFormat" BO_ 832 14;
// Frame: BMS_PTCANFD_0x34B
BA_ "GenMsgCycleTime" BO_ 843 500.000;
BA_ "GenMsgSendType" BO_ 843 0;
BA_ "VFrameFormat" BO_ 843 14;
// Frame: BMS_PTCANFD_0x385
BA_ "GenMsgCycleTime" BO_ 901 500.000;
BA_ "GenMsgSendType" BO_ 901 0;
BA_ "VFrameFormat" BO_ 901 14;
// Frame: BMS_PTCANFD_0x390
BA_ "GenMsgCycleTime" BO_ 912 500.000;
BA_ "GenMsgSendType" BO_ 912 0;
BA_ "VFrameFormat" BO_ 912 14;
// Frame: BMS_PTCANFD_0x394
BA_ "GenMsgCycleTime" BO_ 916 500.000;
BA_ "GenMsgSendType" BO_ 916 0;
BA_ "VFrameFormat" BO_ 916 14;
// Frame: BMS_PTCANFD_0x3A0
BA_ "GenMsgCycleTime" BO_ 928 1000.000;
BA_ "GenMsgSendType" BO_ 928 0;
BA_ "VFrameFormat" BO_ 928 14;
// Frame: BMS_PTCANFD_0x3A2
BA_ "GenMsgCycleTime" BO_ 930 1000.000;
BA_ "GenMsgSendType" BO_ 930 0;
BA_ "VFrameFormat" BO_ 930 14;
// Frame: BMS_PTCANFD_0x3DF
BA_ "GenMsgCycleTime" BO_ 991 1000.000;
BA_ "GenMsgSendType" BO_ 991 0;
BA_ "VFrameFormat" BO_ 991 14;
// Frame: BMS_PTCANFD_0x3E9
BA_ "GenMsgCycleTime" BO_ 1001 1000.000;
BA_ "GenMsgSendType" BO_ 1001 0;
BA_ "VFrameFormat" BO_ 1001 14;
// Frame: BMS_PTCANFD_0x3EB
BA_ "GenMsgCycleTime" BO_ 1003 1000.000;
BA_ "GenMsgSendType" BO_ 1003 0;
BA_ "VFrameFormat" BO_ 1003 14;
// Frame: BMS_PTCANFD_0x3ED
BA_ "GenMsgCycleTime" BO_ 1005 1000.000;
BA_ "GenMsgSendType" BO_ 1005 0;
BA_ "VFrameFormat" BO_ 1005 14;
// Frame: BMS_PTCANFD_0x3EE
BA_ "GenMsgCycleTime" BO_ 1006 1000.000;
BA_ "GenMsgSendType" BO_ 1006 0;
BA_ "VFrameFormat" BO_ 1006 14;
// Frame: BMS_PTCANFD_0x3F2
BA_ "GenMsgCycleTime" BO_ 1010 1000.000;
BA_ "GenMsgSendType" BO_ 1010 0;
BA_ "VFrameFormat" BO_ 1010 14;
// Frame: BMS_PTCANFD_0x3F4
BA_ "GenMsgCycleTime" BO_ 1012 1000.000;
BA_ "GenMsgSendType" BO_ 1012 0;
BA_ "VFrameFormat" BO_ 1012 14;
// Frame: BMS_PTCANFD_0x3F8
BA_ "GenMsgCycleTime" BO_ 1016 1000.000;
BA_ "GenMsgSendType" BO_ 1016 0;
BA_ "VFrameFormat" BO_ 1016 14;
// Frame: BMS_PTCANFD_0x3FB
BA_ "GenMsgCycleTime" BO_ 1019 1000.000;
BA_ "GenMsgSendType" BO_ 1019 0;
BA_ "VFrameFormat" BO_ 1019 14;
// Frame: BMS_PTCANFD_0x3FC
BA_ "GenMsgCycleTime" BO_ 1020 1000.000;
BA_ "GenMsgSendType" BO_ 1020 0;
BA_ "VFrameFormat" BO_ 1020 14;
BA_ "GenSigSendType" SG_ 534 BMSSyncFVReq 1;
BA_ "GenSigStartValue" SG_ 1005 HVBattDischargeSoCTargetReq 720;
BA_ "GenSigStartValue" SG_ 1005 HVFlybackPwrAllwd 100;
BA_ "GenSigStartValue" SG_ 1001 HvBattCellBalTempMax 65;
BA_ "GenSigStartValue" SG_ 912 HvBattCellMaxSocErrIdx 1;
BA_ "GenSigStartValue" SG_ 912 HvBattCellMaxSocIdx 1;
BA_ "GenSigStartValue" SG_ 912 HvBattCellMinSocIdx 1;
BA_ "GenSigStartValue" SG_ 1012 HvBattCellQntyRSMS 1;
BA_ "GenSigStartValue" SG_ 632 HvBattCorsCur 32767;
BA_ "GenSigStartValue" SG_ 678 HvBattHvRawU2 16384;
BA_ "GenSigStartValue" SG_ 678 HvBattHvRawU3 16384;
BA_ "GenSigStartValue" SG_ 678 HvBattHvRawU4 16384;
BA_ "GenSigStartValue" SG_ 678 HvBattHvRawU5 16384;
BA_ "GenSigStartValue" SG_ 678 HvBattHvRawU6 16384;
BA_ "GenSigStartValue" SG_ 678 HvBattHvRawU7 16384;
BA_ "GenSigStartValue" SG_ 678 HvBattHvRawU8 16384;
BA_ "GenSigStartValue" SG_ 646 HvBattInsulRN 65535;
BA_ "GenSigStartValue" SG_ 646 HvBattInsulRP 65535;
BA_ "GenSigStartValue" SG_ 1012 HvBattMaxTProbIDRSMS 1;
BA_ "GenSigStartValue" SG_ 627 HvBattMaxUCellIDRSMS 1;
BA_ "GenSigStartValue" SG_ 1012 HvBattMinTProbIDRSMS 1;
BA_ "GenSigStartValue" SG_ 627 HvBattMinUCellIDRSMS 1;
BA_ "GenSigStartValue" SG_ 1012 HvBattPackQntyRSMS 1;
BA_ "GenSigStartValue" SG_ 626 HvBattRlyHldSts 2;
BA_ "GenSigStartValue" SG_ 1005 HvBattSOHRSMSCode 1;
BA_ "GenSigStartValue" SG_ 1012 HvBattTPrbQntyRSMS 1;
BA_ "GenSigStartValue" SG_ 646 HvBusInsulRN 65535;
BA_ "GenSigStartValue" SG_ 646 HvBusInsulRP 65535;
BA_ "GenSigStartValue" SG_ 1012 HvFlybackACCWh 65535;
BA_ "GenSigStartValue" SG_ 1012 HvFlybackAvgCur 65535;
BA_ "GenSigStartValue" SG_ 1012 HvFlybackAvgPwr 65535;

VAL_ 305 HvBattAvgCur 65535 "Invalid";
VAL_ 305 HvBattChrgnModSts 0 "Not_in_charge" 1 "AC_charging" 2 "DC_charging" 3 "Wireless_charging" 4 "V2L" 5 "V2V";
VAL_ 305 HvBattHVIL1Sts 0 "Close" 1 "Open" 2 "Not_determined" 3 "Invalid";
VAL_ 305 HvBattHVIL2Sts 0 "Close" 1 "Open" 2 "Not_determined" 3 "Invalid";
VAL_ 305 HvBattServModSts 0 "No_request" 1 "Requet" 2 "Not_Used" 3 "Not_Used";
VAL_ 449 BMSAuthenticationSts 0 "Standby" 1 "2015P_Pass";
VAL_ 449 BMSBCPErrSts 0 "No" 1 "Yes";
VAL_ 449 BMSBHMErrSts 0 "No" 1 "Yes";
VAL_ 449 BMSChrgnAwakeSts 0 "Init" 1 "Chrgr_Awake_Succ" 2 "Veh_Awake_Succ" 3 "Chrgr_Awake_Fail" 4 "Veh_Awake_Fail";
VAL_ 449 BMSChrgnPauseSts 0 "Start" 1 "Pause";
VAL_ 449 BMSChrgnRepeatReq 0 "No_Req" 1 "Chrgr_Req" 2 "Veh_Req";
VAL_ 449 DCChrgnCntctSts 0 "Open" 1 "Close" 2 "Not_determined";
VAL_ 449 DCChrgnNegCntctSts 0 "Open" 1 "Close" 2 "Not_determined";
VAL_ 449 DCChrgnPosCntctSts 0 "Open" 1 "Close" 2 "Not_determined";
VAL_ 449 DCPileType 0 "Not_available" 1 "MI_PUB" 2 "MI_HPC" 3 "MI_PRV" 4 "GBT_DC" 5 "GBT_HPC";
VAL_ 449 HvBattAvgCurBackUp 65535 "Invalid";
VAL_ 449 HvBattCoolgLvlReq 0 "NoReq" 1 "Level1" 2 "Level2" 3 "Level3" 4 "Level4";
VAL_ 449 HvBattFlgChrgnSoCLimFinish 0 "Not_finish" 1 "Finish";
VAL_ 449 HvBattFlgDchrgnSoCLimFinish 0 "Not_finish" 1 "Finish";
VAL_ 449 HvBattFlgFullChrgnFinish 0 "Not_finish" 1 "Finish";
VAL_ 449 HvBattHeatCurLim 16383 "Invalid";
VAL_ 449 HvBattHeatgLvlReq 0 "NoReq" 1 "Level1" 2 "Level2" 3 "Level3" 4 "Level4";
VAL_ 449 PrechargnPosCntctSts 0 "Open" 1 "Close" 2 "Not_determined";
VAL_ 626 HvBattActvThermRemd 0 "Init" 1 "Active_Heat" 2 "Active_Cool" 3 "Reserved";
VAL_ 626 HvBattFlgLowSoc 0 "Invalid" 1 "level1" 2 "level2" 3 "level3";
VAL_ 626 HvBattFlgPfmn 0 "No_performance_assurance_event" 1 "Performance_assurance_event_detected";
VAL_ 626 HvBattFlgSfty 0 "No_safetyEvent" 1 "Over_TemperatureDetected" 2 "Over_VoltageDetected" 3 "Under_VoltageDetected" 4 "Reserved";
VAL_ 626 HvBattFlgThermRunAway 0 "Normal" 1 "Thermal_run_away_warning" 2 "Thermal_run_away_alarm";
VAL_ 626 HvBattHlthMngtFcnSts 0 "Default" 1 "Disable" 2 "Enable";
VAL_ 626 HvBattHWFailReq 0 "No_Req" 1 "Req";
VAL_ 626 HvBattLowSocDrvInhb 0 "No_request" 1 "Request";
VAL_ 626 HvBattRlyHldSts 0 "继电器保持未置位" 1 "继电器保持置位" 2 "无效";
VAL_ 626 HvbattSrvReq 0 "No_request" 1 "Service_requested";
VAL_ 626 HvBattSupChrgnResp 0 "Init" 1 "Ongoing" 2 "No_Response";
VAL_ 626 HvBattTempLowFault 0 "No_Fault" 1 "Fault";
VAL_ 627 HvBattCellUDifFltRSMS 0 "no_fault" 1 "level_1_fault" 2 "level_2_fault" 3 "level_3_fault";
VAL_ 627 HvBattCellUOverFltRSMS 0 "no_fault" 1 "level_1_fault" 2 "level_2_fault" 3 "level_3_fault";
VAL_ 627 HvBattCellUUnderFltRSMS 0 "no_fault" 1 "level_1_fault" 2 "level_2_fault" 3 "level_3_fault";
VAL_ 627 HvBattChrgnrComFltRSMS 0 "no_fault" 1 "level_1_fault" 2 "level_2_fault" 3 "level_3_fault";
VAL_ 627 HvBattColdWarn 0 "Not_Active" 1 "Active";
VAL_ 627 HvBattMILReq 0 "Not_Request" 1 "Lamp_On_Request";
VAL_ 627 HvBattOperationReq 0 "No_request" 1 "FullChrg_request" 2 "FullChrg_recommend" 3 "SOH_correct" 4 "LowCurrent_Chrg_Request" 5 "LowSoc_Chrg_request" 6 "No_FrequentFullDischrg_request";
VAL_ 627 HvBattOverChrgnFltRSMS 0 "no_fault" 1 "level_1_fault" 2 "level_2_fault" 3 "level_3_fault";
VAL_ 627 HvBattOverCurFltRSMS 0 "no_fault" 1 "level_1_fault" 2 "level_2_fault" 3 "level_3_fault";
VAL_ 627 HvBattPackUOverFltRSMS 0 "no_fault" 1 "level_1_fault" 2 "level_2_fault" 3 "level_3_fault";
VAL_ 627 HvBattPackUUnderFltRSMS 0 "no_fault" 1 "level_1_fault" 2 "level_2_fault" 3 "level_3_fault";
VAL_ 627 HvBattPwrDoMoSceRSMS 0 "No_Wake" 1 "Wake_Without_Warning" 2 "Wake_With_Warning" 3 "Invalid";
VAL_ 627 HvBattRutPheatgChrgnSts2 0 "No_Command" 1 "OFF" 2 "ON";
VAL_ 627 HvBattSocHiFltRSMS 0 "no_fault" 1 "level_1_fault" 2 "level_2_fault" 3 "level_3_fault";
VAL_ 627 HvBattSocHopFltRSMS 0 "no_fault" 1 "level_1_fault" 2 "level_2_fault" 3 "level_3_fault";
VAL_ 627 HvBattSocLoFltRSMS 0 "no_fault" 1 "level_1_fault" 2 "level_2_fault" 3 "level_3_fault";
VAL_ 627 HvBattTDifFltRSMS 0 "no_fault" 1 "level_1_fault" 2 "level_2_fault" 3 "level_3_fault";
VAL_ 627 HvBattTOverFltRSMS 0 "no_fault" 1 "level_1_fault" 2 "level_2_fault" 3 "level_3_fault";
VAL_ 627 MainNegCntctFlt 0 "No_fault" 1 "Stuck_close" 2 "Stuck_open" 3 "Contact_control_fault";
VAL_ 627 MainPosCntctFlt 0 "No_fault" 1 "Stuck_close" 2 "Stuck_open" 3 "Contact_control_fault";
VAL_ 630 DCChrgnProtocolVers 0 "Not_available" 1 "GBT_2011" 2 "GBT_2015" 3 "GBT_2015P";
VAL_ 630 DCChrgrTypInfo 0 "Not_available" 1 "MI_PUB" 2 "MI_Supercharger" 3 "MI_PRV" 4 "GBT_DC" 5 "CHAOJI" 6 "GBT/DC_2015P" 7 "GBT_HPC";
VAL_ 630 HvBatt2CCUSleepCmd 0 "No_req" 90 "Sleep" 165 "Keep-Wake";
VAL_ 630 HvBattChrgdEgyThisChrgnCyc 131071 "Invalid";
VAL_ 630 HvBattDCChrgnfltTyp 0 "No_fault" 1 "Derating" 2 "Charger_Fault" 3 "Veh_No_Supp";
VAL_ 630 HvBattDCChrgnSts 0 "Standby" 1 "Buck_request" 2 "Boost_Charging" 3 "DC_Charging" 4 "ChargingStopedWithCSTFirst" 5 "Quit_Buck" 6 "Preheating" 7 "Warming";
VAL_ 630 HvBattDCChrgnTyp 0 "No_req" 1 "Direct_Charging" 2 "Boost_Charging";
VAL_ 630 HvBattUCellAvg 8191 "Invalid";
VAL_ 630 HvBattUCellMax 8191 "Invalid";
VAL_ 630 HvBattUCellMin 8191 "Invalid";
VAL_ 632 HvBattV2VSts 0 "Standby" 1 "Buck_request" 2 "Charging" 3 "Charging_stopped";
VAL_ 633 HvBattCellURSMS10 8191 "Invalid";
VAL_ 642 BMUFuSaFltRct 0 "Fault_reaction_is_not_triggered_by_function_safety_SW_component" 1 "Fault_reaction_is_triggered_by_function_safety_SW_component";
VAL_ 642 GaCMSAfeDieTempOTTestFail 0 "No_fault" 1 "Fault";
VAL_ 642 GaCTMModlTempSampElecFault 0 "No_fault" 1 "Fault";
VAL_ 642 GaCTMModlTempSamplingOoRSts 0 "No_fault" 1 "Fault";
VAL_ 642 GeACCChargeOvercurrentL1Fault 0 "No_fault" 1 "Fault";
VAL_ 642 GeACCChargeOvercurrentL2Fault 0 "No_fault" 1 "Fault";
VAL_ 642 GeACCChargeOverCurrentL3Fault 0 "No_fault" 1 "Fault";
VAL_ 642 GeACCChargeOverCurrentL4Fault 0 "No_fault" 1 "Fault";
VAL_ 642 GeACCChargeOverCurrentL5Fault 0 "No_fault" 1 "Fault";
VAL_ 642 GeBCSOverCurrentDeviationFault 0 "No_fault" 1 "Fault";
VAL_ 642 GeBCVVdncSmpCircAbnFault 0 "No_fault" 1 "Fault";
VAL_ 642 GeBCVVdpcSmpCircAbnFault 0 "No_fault" 1 "Fault";
VAL_ 642 GeBCVVmncSmpCircAbnFault 0 "No_fault" 1 "Fault";
VAL_ 642 GeBCVVmpcSmpCircAbnFault 0 "No_fault" 1 "Fault";
VAL_ 642 GeDCCChargeOvercurrentL1Fault 0 "No_fault" 1 "Fault";
VAL_ 642 GeDCCChargeOvercurrentL2Fault 0 "No_fault" 1 "Fault";
VAL_ 642 GeDCCChargeOverCurrentL3Fault 0 "No_fault" 1 "Fault";
VAL_ 642 GeDCCChargeOverCurrentL4Fault 0 "No_fault" 1 "Fault";
VAL_ 642 GeDCCChargeOverCurrentL5Fault 0 "No_fault" 1 "Fault";
VAL_ 645 HvBattAFECommSt 65535 "Invalid";
VAL_ 646 BMSCHMRxSts 0 "No" 1 "Yes";
VAL_ 646 BMSCMLRxSts 0 "No" 1 "Yes";
VAL_ 646 BMSCRMARxSts 0 "No" 1 "Yes";
VAL_ 646 BMSCRMORxSts 0 "No" 1 "Yes";
VAL_ 646 BMSCROARxSts 0 "No" 1 "Yes";
VAL_ 646 BMSCROORxSts 0 "No" 1 "Yes";
VAL_ 646 DCChrgnNegCntctFlt 0 "No_fault" 1 "Stuck_close" 2 "Stuck_open" 3 "Contact_control_fault";
VAL_ 646 DCChrgnPosCntctFlt 0 "No_fault" 1 "Stuck_close" 2 "Stuck_open" 3 "Contact_control_fault";
VAL_ 646 DCChrgrCc1ConnectnSts 0 "Disconnected" 1 "Half_connected" 2 "Connected_Charging" 3 "Reserved";
VAL_ 646 DchaByChrgrBattallwFlg 0 "Invalid" 1 "Not_Allow" 2 "Allow" 3 "Reserved";
VAL_ 646 HvBattChrgnDeratForT 0 "No_Req" 1 "Low_HvBattTemp" 2 "High_HvBattTemp";
VAL_ 646 HvBattCmptFaultIndcn 0 "No_Prpmpt" 1 "Level_1" 2 "Level_2" 3 "Level_3" 4 "Level_4" 5 "Level_5" 6 "Level_6" 7 "Level_7" 8 "Level_8" 9 "Level_9" 10 "Level_10" 11 "Level_11" 12 "Level_12" 13 "Level_13" 14 "Level_14" 15 "Level_15";
VAL_ 646 HvBattInsulChkSts 0 "Not_Determined" 1 "Insulation_error_battery_warning" 2 "Insulation_error_battery_serious_alarm" 3 "Insulation_error_HV_bus_warning" 4 "Insulation_error_HV_bus_serious_alarm" 5 "Insulation_check_OK" 6 "Insulation_check_block_from_Scantool" 7 "Invalid";
VAL_ 646 PrechargnPosCntctFlt 0 "No_fault" 1 "Stuck_close" 2 "Stuck_open" 3 "Contact_control_fault";
VAL_ 678 BmsFaultReact 4294967295 "Invalid";
VAL_ 678 HallCurrSampDiag 255 "Invalid";
VAL_ 678 HvBattCellTempNotOkNum 255 "Invalid";
VAL_ 678 HvBattCellVoltNotOkNum 255 "Invalid";
VAL_ 678 HvBattDcChgSts 0 "DCC_CHARGE_FLOW_STANBY" 1 "DCC_CHARGE_FLOW_HANDSHAKE_START" 2 "DCC_CHARGE_FLOW_HANDSHAKE_BHM" 3 "DCC_CHARGE_FLOW_HANDSHAKE_BRM" 4 "DCC_CHARGE_FLOW_PARAMENTE_BCP" 5 "DCC_CHARGE_FLOW_PARAMENTE_BRO" 6 "DCC_CHARGE_FLOW_PARAMENTE_READY" 7 "DCC_CHARGE_FLOW_CHARGING" 8 "DCC_CHARGE_FLOW_CHARGE_STOP" 9 "DCC_CHARGE_FLOW_CHARGE_FAULT" 16 "DCC_CHARGE_FLOW_CAR_TIMEOUT" 17 "DCC_CHARGE_FLOW_CHARGER_TIMEOUT" 18 "DCC_CHARGE_FLOW_CHARGE_END";
VAL_ 678 HvBattDchaSocThisDischrgnCyc 2001 "Invaild";
VAL_ 678 HvBattLeakSensU 255 "Invalid";
VAL_ 678 HvBattPfcChipDiag 255 "Invalid";
VAL_ 678 HvBattPfcDeploySts 255 "Invalid";
VAL_ 678 HvBattRutPheatgFinshd 0 "OFF" 1 "Ready" 2 "Heating" 3 "Finished" 4 "Exit";
VAL_ 678 HVSampDiag 255 "Invalid";
VAL_ 678 ShuntCurrSampDiag 255 "Invalid";
VAL_ 832 HvBattTempRSMS1 511 "Invalid";
VAL_ 832 HvBattTempRSMS10 511 "Invalid";
VAL_ 832 HvBattTempRSMS11 511 "Invalid";
VAL_ 832 HvBattTempRSMS12 511 "Invalid";
VAL_ 832 HvBattTempRSMS13 511 "Invalid";
VAL_ 832 HvBattTempRSMS14 511 "Invalid";
VAL_ 832 HvBattTempRSMS15 511 "Invalid";
VAL_ 832 HvBattTempRSMS16 511 "Invalid";
VAL_ 832 HvBattTempRSMS2 511 "Invalid";
VAL_ 832 HvBattTempRSMS3 511 "Invalid";
VAL_ 832 HvBattTempRSMS4 511 "Invalid";
VAL_ 832 HvBattTempRSMS5 511 "Invalid";
VAL_ 832 HvBattTempRSMS6 511 "Invalid";
VAL_ 832 HvBattTempRSMS7 511 "Invalid";
VAL_ 832 HvBattTempRSMS8 511 "Invalid";
VAL_ 832 HvBattTempRSMS9 511 "Invalid";
VAL_ 912 HvBattPressureInsdPack 4095 "Invalid";
VAL_ 916 HvBattDchaEgyThisCycRSMS 2047 "Invalid";
VAL_ 916 HvBattRecupEgyThisCycRSMS 2047 "Invalid";
VAL_ 1001 BMUMcuResetReason 4294967295 "Invalid";
VAL_ 1001 BMUNVFault 0 "No_fault" 1 "Fault";
VAL_ 1001 HvBattAFECellTempLF 0 "No_fault" 65535 "Invalid";
VAL_ 1001 HvBattAFECellVoltLF 0 "No_fault" 65535 "Invalid";
VAL_ 1001 HvBattBPSDiag 0 "No_fault" 15 "Invalid";
VAL_ 1001 HvBattCellBBTemp1 511 "Invalid";
VAL_ 1001 HvBattCellBBTemp2 511 "Invalid";
VAL_ 1001 HvBattCellBBTemp3 511 "Invalid";
VAL_ 1001 HvBattCellBBTemp4 511 "Invalid";
VAL_ 1001 HvBattCellBBTemp5 511 "Invalid";
VAL_ 1001 HvBattCellBBTemp6 511 "Invalid";
VAL_ 1001 HvBattCellBBVltg1 2047 "Invalid";
VAL_ 1001 HvBattCellBBVltg2 2047 "Invalid";
VAL_ 1001 HvBattHvBoxBBTemp1 511 "Invalid";
VAL_ 1001 HvBattHvBoxBBTemp2 511 "Invalid";
VAL_ 1001 HvBattHvBoxBBTemp3 511 "Invalid";
VAL_ 1001 HvBattPriorityThermalSt 0 "False" 1 "Ture";
VAL_ 1001 HvBattShuntLF 0 "No_fault" 1 "Fault";
VAL_ 1001 HvBattThermalTiOut 0 "False" 1 "Ture";
VAL_ 1005 HvBattOverDchaFlg 0 "No_Fault" 1 "Fault";
VAL_ 1010 HvBattCellBalActvt 0 "Not_activate" 1 "Activated";
VAL_ 1010 HvBattCellTAvg 511 "Invalid";
VAL_ 1010 HvBattCellTMax 511 "Invalid";
VAL_ 1010 HvBattCellTMaxResv 511 "Invalid";
VAL_ 1010 HvBattCellTMin 511 "Invalid";
VAL_ 1010 HvBattCellTMinResv 511 "Invalid";
VAL_ 1010 HvBattFaultInfoFlag 0 "No_Fault" 1 "Fault";
VAL_ 1010 HvBattNTCIdx 63 "Invalid";
VAL_ 1010 HvBattPackDesnMaxEngy 2047 "Invalid";
VAL_ 1010 HVBattTempRiskLvl 0 "0" 1 "1" 2 "2" 3 "3" 4 "4" 5 "5" 6 "6" 7 "7" 8 "8" 9 "9" 10 "10";
VAL_ 1012 DCChrgnPortTNegTerminal 255 "Invalid";
VAL_ 1012 DCChrgnPortTPosTerminal 255 "Invalid";
VAL_ 1012 HvBattFrqHiSocWarn 0 "Normal" 1 "Warn1" 2 "reserved1" 3 "reserved2";
VAL_ 1016 HvBattTempRSMS17 511 "Invalid";
VAL_ 1016 HvBattTempRSMS18 511 "Invalid";
VAL_ 1016 HvBattTempRSMS19 511 "Invalid";
VAL_ 1016 HvBattTempRSMS20 511 "Invalid";
VAL_ 1016 HvBattTempRSMS21 511 "Invalid";
VAL_ 1016 HvBattTempRSMS22 511 "Invalid";
VAL_ 1016 HvBattTempRSMS23 511 "Invalid";
VAL_ 1016 HvBattTempRSMS24 511 "Invalid";
VAL_ 1016 HvBattTempRSMS25 511 "Invalid";
VAL_ 1016 HvBattTempRSMS26 511 "Invalid";
VAL_ 1016 HvBattTempRSMS27 511 "Invalid";
SIG_GROUP_ 449 DCChrgnHvBattSoCSigGrp 1 : DCChrgnCntctSts DCChrgnHvBattSoCSigGrpChks DCChrgnHvBattSoCSigGrpCntr DCChrgnNegCntctSts DCChrgnPosCntctSts HvBattSoCAct;
SIG_GROUP_ 1010 HvBattCellTSigGrp 1 : HvBattCellTMax HvBattCellTMin HvBattCellTSigGrpChks HvBattCellTSigGrpCntr;
SIG_GROUP_ 626 HvBattFlgSftySigGrp 1 : HvBattFlgSfty HvBattFlgSftySigGrpChks HvBattFlgSftySigGrpCntr HvBattFlgThermRunAway;
SIG_GROUP_ 305 HvBattHVILStsSigGrp 1 : HvBattHVIL1Sts HvBattHVIL2Sts HvBattHVILStsSigGrpChks HvBattHVILStsSigGrpCntr;
SIG_GROUP_ 646 HvBattInsulChkSigGrp 1 : HvBattInsulChkSigGrpChks HvBattInsulChkSigGrpCntr HvBattInsulChkSts HvBattInsulRN HvBattInsulRP HvBusInsulRN HvBusInsulRP;
SIG_GROUP_ 626 HvBattRlyHldStsGrp 1 : HvBattRlyHldSts HvBattRlyHldStsChks HvBattRlyHldStsCntr;
SIG_GROUP_ 630 HvBattUCellSigGrp 1 : HvBattCurMaxLimACChrgn HvBattUCellMax HvBattUCellMin HvBattUCellSigGrpChks HvBattUCellSigGrpCntr HvBattUMaxLimACChrgn;
SIG_GROUP_ 630 HvBattUCellSyncSigGrp 1 : HvBattSyncUCellMax HvBattSyncUCellMin HvBattUCellSyncCur HvBattUCellSyncSigGrpChks HvBattUCellSyncSigGrpCntr;
